VERSION ""

NS_ :

BS_:

BU_: EMS FR_CMR TCU vBDM AFS ILCU_LH ILCU_RH VCU BMS CLU EPB ESC H_U_MM IBU IBU_HS LDC MCU MDPS OBC RR_C_RDR SVM DATC ADAS_DRV ADAS_PRK AWD RWS AMP APSU DAU DVRS Dummy FCS HUD IAU ICSC ICU MLM PFSU PTGM SBW ACU ADM ECS TPMS HCU OPU PSB eCall AHLS ODS VESS AHV DHV DLBCU DPSS DPSU PSM RLHV RRHV SHVU_FR SHVU_RR DIBOX SAS FPCM SCM AFCU_DRV ESC_C CGW SCU WPC MFSW SWRC ESU AFCU_AST AFCU_RL AFCU_RR APSM ARS BCM BCW CCM DSS ECW FCU FICU GST HFKS HSWS LPI OPI PSD PSU RDC RLPSM RRPSM RWPC SLB SMK YRS SML CTM FR_C_RDR_LH FR_C_RDR_RH RR_C_RDR_LH CLU_MM HUD_MM LSD MKBD MM_CGW SBW_FF eCall_MM H_U_ETH FR_RDR

BO_ 388 L_FR_CMR_Obj_05_30ms: 32 FR_CMR
 SG_ FR_CMR_Obj_Crc05Val : 0|16@1+ (1,0) [0|65535] ""  ADAS_DRV
 SG_ FR_CMR_Obj_AlvCnt05Val : 16|8@1+ (1,0) [0|255] ""  ADAS_DRV
 SG_ FR_CMR_Obj_QualLvl09Sta : 24|7@1+ (1,0) [0|100] "%"  ADAS_DRV
 SG_ FR_CMR_Obj_AlvAge09Val : 32|8@1+ (1,0) [0|255] ""  ADAS_DRV
 SG_ FR_CMR_Obj_MvngFlag09Sta : 40|4@1+ (1,0) [0|9] ""  ADAS_DRV
 SG_ FR_CMR_Obj_Id09Val : 44|7@1+ (1,0) [0|127] ""  ADAS_DRV
 SG_ FR_CMR_Obj_Wth09Val : 52|7@1+ (0.05,0) [0|6.35] "m"  ADAS_DRV
 SG_ FR_CMR_Obj_Clfct09Sta : 60|3@1+ (1,0) [0|6] ""  ADAS_DRV
 SG_ FR_CMR_Obj_RelPosX09Val : 64|13@1+ (0.05,0) [0|350] "m"  ADAS_DRV
 SG_ FR_CMR_Obj_RelPosY09Val : 78|12@1+ (0.05,-102.4) [-102.4|102.35] "m"  ADAS_DRV
 SG_ FR_CMR_Obj_RelVelX09Val : 91|12@1+ (0.05,-100) [-100|100] "m/s"  ADAS_DRV
 SG_ FR_CMR_Obj_RelVelY09Val : 104|10@1+ (0.05,-25) [-25|25] "m/s"  ADAS_DRV
 SG_ FR_CMR_Obj_RelAccelX09Val : 115|9@1- (0.05,0) [-12.8|12.75] "m/s^2"  ADAS_DRV
 SG_ FR_CMR_Obj_QualLvl10Sta : 152|7@1+ (1,0) [0|100] "%"  ADAS_DRV
 SG_ FR_CMR_Obj_AlvAge10Val : 160|8@1+ (1,0) [0|255] ""  ADAS_DRV
 SG_ FR_CMR_Obj_MvngFlag10Sta : 168|4@1+ (1,0) [0|9] ""  ADAS_DRV
 SG_ FR_CMR_Obj_Id10Val : 172|7@1+ (1,0) [0|127] ""  ADAS_DRV
 SG_ FR_CMR_Obj_Wth10Val : 180|7@1+ (0.05,0) [0|6.35] "m"  ADAS_DRV
 SG_ FR_CMR_Obj_Clfct10Sta : 188|3@1+ (1,0) [0|6] ""  ADAS_DRV
 SG_ FR_CMR_Obj_RelPosX10Val : 192|13@1+ (0.05,0) [0|350] "m"  ADAS_DRV
 SG_ FR_CMR_Obj_RelPosY10Val : 206|12@1+ (0.05,-102.4) [-102.4|102.35] "m"  ADAS_DRV
 SG_ FR_CMR_Obj_RelVelX10Val : 219|12@1+ (0.05,-100) [-100|100] "m/s"  ADAS_DRV
 SG_ FR_CMR_Obj_RelVelY10Val : 232|10@1+ (0.05,-25) [-25|25] "m/s"  ADAS_DRV
 SG_ FR_CMR_Obj_RelAccelX10Val : 243|9@1- (0.05,0) [-12.8|12.75] "m/s^2"  ADAS_DRV

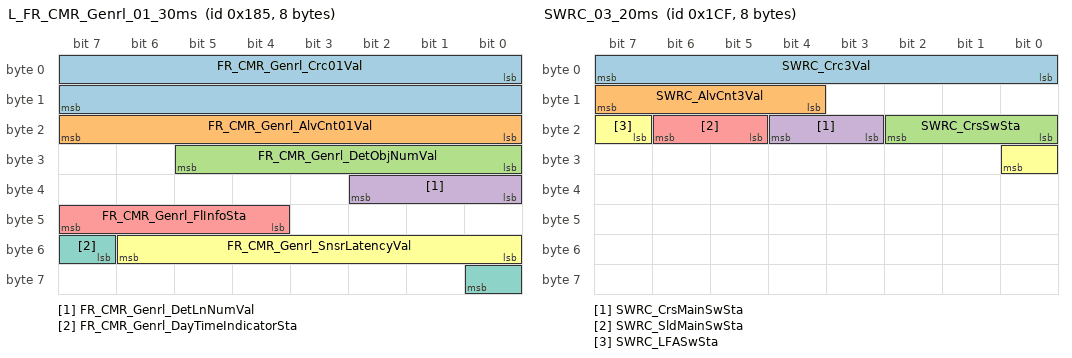
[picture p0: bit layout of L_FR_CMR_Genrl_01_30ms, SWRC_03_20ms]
BO_ 389 L_FR_CMR_Genrl_01_30ms: 8 FR_CMR
 SG_ FR_CMR_Genrl_Crc01Val : 0|16@1+ (1,0) [0|65535] ""  ADAS_DRV
 SG_ FR_CMR_Genrl_AlvCnt01Val : 16|8@1+ (1,0) [0|255] ""  ADAS_DRV
 SG_ FR_CMR_Genrl_DetObjNumVal : 24|6@1+ (1,0) [0|20] ""  ADAS_DRV
 SG_ FR_CMR_Genrl_DetLnNumVal : 32|3@1+ (1,0) [0|4] ""  ADAS_DRV
 SG_ FR_CMR_Genrl_FlInfoSta : 44|4@1+ (1,0) [0|2] ""  ADAS_DRV
 SG_ FR_CMR_Genrl_SnsrLatencyVal : 48|7@1+ (10,0) [0|1270] "ms"  ADAS_DRV
 SG_ FR_CMR_Genrl_DayTimeIndicatorSta : 55|2@1+ (1,0) [0|2] ""  ADAS_DRV

BO_ 416 ADAS_CMD_20_20ms: 32 FR_CMR
 SG_ ADAS_CMD_Crc20Val : 0|16@1+ (1,0) [0|65535] ""  ESC_C
 SG_ ADAS_CMD_AlvCnt20Val : 16|8@1+ (1,0) [0|255] ""  ESC_C,FR_CMR,CGW
 SG_ SCC_ObjDstVal : 24|11@1+ (0.1,0) [0|0] "m"  ESC_C,CGW
 SG_ SCC_ObjRelSpdVal : 35|12@1+ (0.1,-170) [0|0] "m/s"  CGW
 SG_ SCC_ObjLatPosVal : 47|9@1+ (0.1,-20) [0|0] "m"  CGW
 SG_ SCC_SysFlrSta : 64|2@1+ (1,0) [0|0] ""  ACU,ESC_C,CGW
 SG_ SCC_MainOnOffSta : 66|2@1+ (1,0) [0|0] ""  ACU,ESC_C,CGW
 SG_ SCC_OpSta : 68|3@1+ (1,0) [0|0] ""  ACU,ESC_C,CGW
 SG_ SCC_TakeoverReq : 72|2@1+ (1,0) [0|0] ""  ESC_C,CGW
 SG_ SCC_InfoDis : 74|3@1+ (1,0) [0|0] ""  ESC_C,CGW
 SG_ SCC_DrvAlrtDis : 77|2@1+ (1,0) [0|0] ""  ESC_C,CGW
 SG_ SCC_ObjDstLvlVal : 80|8@1+ (1,0) [0|0] ""  CGW
 SG_ SCC_HeadwayDstSetVal : 88|4@1+ (1,0) [0|0] ""  CGW
 SG_ SCC_EquipSta : 92|2@1+ (1,0) [0|0] ""  ESC_C,CGW
 SG_ SCC_TrgtSpdSetVal : 96|8@1+ (1,0) [0|0] "km/h or MPH"  ACU,ESC_C,CGW
 SG_ SCC_NSCCOpSta : 104|2@1+ (1,0) [0|0] ""  CGW
 SG_ SCC_NSCCOnOffSta : 106|2@1+ (1,0) [0|0] ""  FR_CMR,CGW
 SG_ SCC_ObjSta : 108|3@1+ (1,0) [0|0] ""  CGW
 SG_ SCC_SnstvtyModRetVal : 112|3@1+ (1,0) [0|0] ""  ESC_C,CGW
 SG_ SCC_AccelReqVal : 128|11@1+ (0.01,-10.23) [0|0] "m/s^2"  ESC_C,CGW
 SG_ SCC_AccelReqRawVal : 140|11@1+ (0.01,-10.23) [-10.23|10.24] "m/s^2"  ESC_C,CGW
 SG_ SCC_JrkUppLimVal : 152|7@1+ (0.1,0) [0|0] "m/s^3"  ESC_C,CGW
 SG_ SCC_JrkLwrLimVal : 160|7@1+ (0.1,0) [0|0] "m/s^3"  ESC_C,CGW
 SG_ SCC_AccelLimBandUppVal : 168|6@1+ (0.02,0) [0|1.26] "m/s^2"  ESC_C,CGW
 SG_ SCC_AccelLimBandLwrVal : 176|6@1+ (0.02,0) [0|1.26] "m/s^2"  ESC_C,CGW
 SG_ SCC_VehStpReq : 184|2@1+ (1,0) [0|0] ""  EPB,ESC_C,CGW
 SG_ SCC_TrgtDstVal : 192|11@1+ (0.1,0) [0|0] "m"  CGW

BO_ 426 CLU_01_20ms: 16 CLU
 SG_ CLU_Crc1Val : 0|16@1+ (1,0) [0|65535] ""  ADAS_PRK,DPSS,DPSU,Dummy,FR_CMR,ICU,MDPS,PSM,vBDM
 SG_ CLU_AlvCnt1Val : 16|8@1+ (1,0) [0|255] ""  ADAS_DRV,ADAS_PRK,AHLS,DPSS,DPSU,EMS,EPB,FR_CMR,ICU,MDPS,PSM,vBDM
 SG_ CLU_DtntOutSta : 28|2@1+ (1,0) [0|3] ""  ADAS_PRK,APSU,DATC,DAU,DVRS,FCS,FR_CMR,H_U_MM,IBU_HS,ICU,RR_C_RDR,SBW,SVM,WPC,vBDM
 SG_ CLU_SpdUnitTyp : 30|2@1+ (1,0) [0|3] ""  ACU,ADAS_DRV,ADAS_PRK,AMP,DPSU,EMS,FR_CMR,HCU,HUD,H_U_MM,IAU,ICU,MDPS,PSM,RR_C_RDR,SCM,VCU,WPC,eCall,vBDM
 SG_ CLU_SWRCLFASwSta : 39|2@1+ (1,0) [0|3] ""  ACU,ADAS_DRV,EMS,FR_CMR,TCU
 SG_ CLU_RhstaLvlSta : 43|5@1+ (1,0) [0|31] ""  ADAS_PRK,DATC,DAU,FCS,FR_CMR,HUD,H_U_MM,IBU_HS,ICU,MFSW,RR_C_RDR,SBW,SVM,SWRC,WPC,vBDM
 SG_ CLU_DisSpdVal : 48|10@1+ (0.5,0) [0|511.5] "km/h or MPH"  ADAS_DRV,ADAS_PRK,ADM,AMP,APSU,DPSU,EMS,FR_CMR,HCU,HUD,H_U_MM,IAU,IBU_HS,ICU,MDPS,PSM,RR_C_RDR,SCM,WPC,eCall,vBDM

BO_ 437 FR_CMR_03_50ms: 32 FR_CMR
 SG_ FR_CMR_Crc3Val : 0|16@1+ (1,0) [0|65535] ""  Dummy,ECS,vBDM
 SG_ FR_CMR_AlvCnt3Val : 16|8@1+ (1,0) [0|255] ""  Dummy,ECS,vBDM
 SG_ Info_LftLnQualSta : 24|3@1+ (1,0) [0|7] ""  Dummy,ECS,vBDM
 SG_ Info_LftLnDptSta : 27|2@1+ (1,0) [0|3] ""  Dummy,vBDM
 SG_ Info_LftLnPosVal : 29|14@1- (0.0039625,0) [-32.4608|32.4568375] "m"  Dummy,vBDM
 SG_ Info_LftLnHdingAnglVal : 43|10@1- (0.000976563,0) [-0.500000256|0.499023693] "rad"  Dummy,ECS,vBDM
 SG_ Info_LftLnCvtrVal : 64|16@1- (1E-006,0) [-0.032768|0.032767] "1/m"  Dummy,ECS,vBDM
 SG_ Info_LftLnCrvtrDrvtvVal : 80|16@1- (4E-009,0) [-0.000131072|0.000131068] "1/m2"  Dummy,ECS,vBDM
 SG_ Info_RtLnQualSta : 96|3@1+ (1,0) [0|7] ""  Dummy,ECS,vBDM
 SG_ Info_RtLnDptSta : 99|2@1+ (1,0) [0|3] ""  Dummy,vBDM
 SG_ Info_RtLnPosVal : 101|14@1- (0.0039625,0) [-32.4608|32.4568375] "m"  Dummy,vBDM
 SG_ Info_RtLnHdingAnglVal : 115|10@1- (0.000976563,0) [-0.500000256|0.499023693] "rad"  Dummy,ECS,vBDM
 SG_ Info_RtLnCvtrVal : 128|16@1- (1E-006,0) [-0.032768|0.032767] "1/m"  Dummy,ECS,vBDM
 SG_ Info_RtLnCrvtrDrvtvVal : 144|16@1- (4E-009,0) [-0.000131072|0.000131068] "1/m2"  Dummy,ECS,vBDM

BO_ 442 ADAS_CMD_40_50ms: 24 ADAS_DRV
 SG_ ADAS_CMD_AlvCnt40Val : 16|8@1+ (1,0) [0|0] ""  CLU,ESC,FR_CMR,H_U_MM,vBDM
 SG_ BCA_Sta : 64|4@1+ (1,0) [0|0] ""  CLU,ESC,FR_CMR,H_U_MM,vBDM
 SG_ BCA_LftWrngSta : 72|2@1+ (1,0) [0|0] ""  CLU,ESC,FR_CMR,H_U_MM,vBDM
 SG_ BCA_RtWrngSta : 74|2@1+ (1,0) [0|0] ""  CLU,ESC,FR_CMR,H_U_MM,vBDM

BO_ 463 SWRC_03_20ms: 8 SWRC
 SG_ SWRC_Crc3Val : 0|8@1+ (1,0) [0|0] ""  ACU,ADAS_DRV,Dummy,EMS,FR_CMR,TCU
 SG_ SWRC_AlvCnt3Val : 12|4@1+ (1,0) [0|0] ""  ACU,ADAS_DRV,Dummy,EMS,FR_CMR,TCU
 SG_ SWRC_CrsSwSta : 16|3@1+ (1,0) [0|0] ""  ACU,ADAS_DRV,EMS,FR_CMR,TCU
 SG_ SWRC_CrsMainSwSta : 19|2@1+ (1,0) [0|0] ""  FR_CMR
 SG_ SWRC_SldMainSwSta : 21|2@1+ (1,0) [0|0] ""  FR_CMR
 SG_ SWRC_LFASwSta : 23|2@1+ (1,0) [0|0] ""  ACU,ADAS_DRV,EMS,FR_CMR,TCU

BO_ 480 ADAS_CMD_31_50ms: 16 FR_CMR
 SG_ ADAS_CMD_Crc31Val : 0|16@1+ (1,0) [0|0] ""  CGW
 SG_ ADAS_CMD_AlvCnt31Val : 16|8@1+ (1,0) [0|0] ""  CGW
 SG_ HDA_OptUsmSta : 24|3@1+ (1,0) [0|0] ""  CGW
 SG_ LFA_OptUsmSta : 27|3@1+ (1,0) [0|0] ""  CGW
 SG_ HDA_CntrlModSta : 30|2@1+ (1,0) [0|0] ""  CGW
 SG_ HDA_InfoPUDis : 32|3@1+ (1,0) [0|0] ""  CGW
 SG_ HDA_AutoSetSpdSta : 35|2@1+ (1,0) [0|0] ""  CGW
 SG_ HDA_AutoSetSpdUpdtSta : 37|2@1+ (1,0) [0|0] ""  CGW
 SG_ HDA_AutoSetSpdVal : 39|8@1+ (1,0) [0|0] "km/h"  CGW
 SG_ HDA_LFA_SymSta : 47|2@1+ (1,0) [0|0] ""  CGW
 SG_ HDA_LFA_WrnSnd : 49|2@1+ (1,0) [0|0] ""  Dummy

BO_ 506 FR_CMR_02_100ms: 32 FR_CMR
 SG_ ISLA_SpdwOffst : 112|8@1+ (1,0) [0|255] ""  CLU,CGW
 SG_ ISLA_SwIgnoreReq : 120|2@1+ (1,0) [0|3] ""  CGW
 SG_ ISLA_SpdChgReq : 122|2@1+ (1,0) [0|3] ""  CGW
 SG_ ISLA_SpdWrn : 124|2@1+ (1,0) [0|3] ""  CLU,CGW
 SG_ ISLA_IcyWrn : 126|2@1+ (1,0) [0|3] ""  CLU,CGW
 SG_ ISLA_SymFlashMod : 128|3@1+ (1,0) [0|7] ""  CLU,CGW
 SG_ ISLA_Popup : 131|3@1+ (1,0) [0|7] ""  CLU
 SG_ ISLA_OptUsmSta : 136|3@1+ (1,0) [0|7] ""  CLU,CGW
 SG_ ISLA_OffstUsmSta : 139|3@1+ (1,0) [0|7] ""  CLU,CGW
 SG_ ISLA_AutoUsmSta : 142|2@1+ (1,0) [0|3] ""  CLU,CGW
 SG_ ISLA_Cntry : 144|4@1+ (1,0) [0|15] ""  CLU,CGW
 SG_ ISLA_AddtnlSign : 149|5@1+ (1,0) [0|31] ""  CLU,CGW
 SG_ ISLA_SchoolZone : 154|2@1+ (1,0) [0|3] ""  CLU,CGW
 SG_ FR_CMR_Crc2Val : 0|16@1+ (1,0) [0|65535] ""  CLU,IBU_HS
 SG_ FR_CMR_AlvCnt2Val : 16|8@1+ (1,0) [0|255] ""  CLU,H_U_MM,IBU_HS
 SG_ ISLW_OptUsmSta : 24|2@1+ (1,0) [0|3] ""  CLU,HUD,H_U_MM
 SG_ ISLW_SysSta : 26|2@1+ (1,0) [0|3] ""  CGW,CLU,EMS,HUD,H_U_MM
 SG_ ISLW_NoPassingInfoDis : 28|3@1+ (1,0) [0|7] ""  CGW,CLU,HUD,H_U_MM
 SG_ ISLW_OvrlpSignDis : 31|2@1+ (1,0) [0|3] ""  CGW,CLU,HUD,H_U_MM
 SG_ ISLW_SpdCluMainDis : 33|8@1+ (1,0) [0|255] ""  CLU,HUD,H_U_MM
 SG_ ISLW_SpdNaviMainDis : 41|8@1+ (1,0) [0|255] ""  CGW,H_U_MM
 SG_ ISLW_SubCondinfoSta1 : 49|4@1+ (1,0) [0|15] ""  CGW,CLU,H_U_MM
 SG_ ISLW_SubCondinfoSta2 : 53|4@1+ (1,0) [0|15] ""  CGW,CLU,H_U_MM
 SG_ ISLW_SpdCluSubMainDis : 64|8@1+ (1,0) [0|255] ""  CLU,H_U_MM
 SG_ ISLW_SpdCluDisSubCond1 : 72|8@1+ (1,0) [0|255] ""  CLU,H_U_MM
 SG_ ISLW_SpdCluDisSubCond2 : 80|8@1+ (1,0) [0|255] ""  CLU,H_U_MM
 SG_ ISLW_SpdNaviSubMainDis : 88|8@1+ (1,0) [0|255] ""  CLU,H_U_MM
 SG_ ISLW_SpdNaviDisSubCond1 : 96|8@1+ (1,0) [0|255] ""  CGW,CLU,H_U_MM
 SG_ ISLW_SpdNaviDisSubCond2 : 104|8@1+ (1,0) [0|255] ""  CGW,CLU,H_U_MM

BO_ 549 CLU_02_100ms: 16 CLU
 SG_ CLU_AlvCnt2Val : 16|8@1+ (1,0) [0|255] ""  AWD,EMS,ESC,FR_CMR,H_U_MM,IBU,RWS,vBDM
 SG_ CLU_TerrainMainSwSta : 62|2@1+ (1,0) [0|3] ""  AWD,ESC,FR_CMR,HCU,H_U_MM,ICSC,MDPS,VCU,vBDM
 SG_ CLU_OdoVal : 72|24@1+ (0.1,0) [0|1677721.5] "km"  ADAS_DRV,AMP,AWD,BMS,EMS,EPB,ESC,ESU,FR_CMR,HCU,H_U_MM,IAU,IBU,ICU,LDC,MCU,OBC,OPU,RR_C_RDR,TCU,TPMS,VCU,eCall,vBDM
 SG_ CLU_DawLastBrkTimeVal : 96|4@1+ (1,0) [0|15] ""  Dummy,FR_CMR,H_U_MM,vBDM
 SG_ CLU_IceWrnIndSta : 102|2@1+ (1,0) [0|3] ""  Dummy,FR_CMR,vBDM
 SG_ CLU_DrvngModSwSta : 104|4@1+ (1,0) [0|15] ""  ADAS_DRV,AMP,AWD,DATC,ECS,EMS,ESC,FR_CMR,HCU,HUD,H_U_MM,ICSC,MDPS,TCU,vBDM
 SG_ CLU_TerrainModSwSta : 123|3@1+ (1,0) [0|7] ""  ADAS_DRV,AWD,DATC,ECS,EMS,ESC,FR_CMR,HCU,HUD,H_U_MM,ICSC,MDPS,TCU,vBDM

BO_ 560 HCU_05_100ms: 32 HCU
 SG_ HCU_BrkLmpOnReq : 80|2@1+ (1,0) [0|0] ""  CLU,ESC,FR_CMR,H_U_MM,ICU

BO_ 608 EMS_05_100ms: 32 EMS
 SG_ ENG_TransmsnTyp : 176|6@1+ (1,0) [0|63] ""  ACU,AWD,DATC,EPB,ESC,FR_CMR,HUD,H_U_MM,IBU,IBU_HS,ICSC,ICU,RR_C_RDR,TCU,vBDM
 SG_ ENG_EngDsplceTyp : 184|8@1+ (0.1,0) [0|25.5] "liter"  ACU,ADAS_PRK,AMP,AWD,CLU,DATC,EPB,ESC,FR_CMR,H_U_MM,IBU,ICSC,ICU,vBDM

BO_ 613 EMS_08_100ms: 32 EMS
 SG_ HEV_BrkLtSwSta : 62|2@1+ (1,0) [0|0] ""  ACU,EPB,FR_CMR,H_U_MM,OPU,RR_C_RDR,TCU

BO_ 661 EMS_06_100ms: 24 EMS
 SG_ OBD_EngRpmVal : 40|16@1+ (0.25,0) [0|0] "rpm"  BMS,FR_CMR,MCU,TCU,vBDM

BO_ 674 L_FR_CMR_Ln_01_50ms: 32 FR_CMR
 SG_ FR_CMR_Ln_Crc01Val : 0|16@1+ (1,0) [0|65535] ""  ADAS_DRV
 SG_ FR_CMR_Ln_AlvCnt01Val : 16|8@1+ (1,0) [0|255] ""  ADAS_DRV
 SG_ FR_CMR_Ln_LftDptDstVal : 24|16@1+ (0.01,-10) [-10|10] "m"  ADAS_DRV
 SG_ FR_CMR_Ln_RtDptDstVal : 40|16@1+ (0.01,-10) [-10|10] "m"  ADAS_DRV
 SG_ FR_CMR_Ln_LftDptAnglVal : 64|16@1+ (0.000977,-0.357) [-0.357|0.357] "rad"  ADAS_DRV
 SG_ FR_CMR_Ln_RtDptAnglVal : 96|16@1+ (0.000977,-0.357) [-0.357|0.357] "rad"  ADAS_DRV
 SG_ FR_CMR_Ln_LftCurveVal : 128|32@1+ (9.77E-007,-0.032) [-0.032|0.032] "1/m"  ADAS_DRV
 SG_ FR_CMR_Ln_RtCurveVal : 160|32@1+ (9.77E-007,-0.032) [-0.032|0.032] "1/m"  ADAS_DRV
 SG_ FR_CMR_Ln_LftCurveRatVal : 192|32@1+ (3.73E-009,-0.00012) [-0.00012|0.000122] "1/m^2"  ADAS_DRV
 SG_ FR_CMR_Ln_RtCurveRatVal : 224|32@1+ (3.73E-009,-0.00012) [-0.00012|0.000122] "1/m^2"  ADAS_DRV

BO_ 675 L_FR_CMR_Ln_02_50ms: 32 FR_CMR
 SG_ FR_CMR_Ln_Crc02Val : 0|16@1+ (1,0) [0|65535] ""  ADAS_DRV
 SG_ FR_CMR_Ln_AlvCnt02Val : 16|8@1+ (1,0) [0|255] ""  ADAS_DRV
 SG_ FR_CMR_Ln_LftNextLnDptDstVal : 24|16@1+ (0.01,-10) [-10|10] "m"  ADAS_DRV
 SG_ FR_CMR_Ln_RtNextDptDstVal : 40|16@1+ (0.01,-10) [-10|10] "m"  ADAS_DRV
 SG_ FR_CMR_Ln_LftNextDptAnglVal : 64|16@1+ (0.000977,-0.357) [-0.357|0.357] "rad"  ADAS_DRV
 SG_ FR_CMR_Ln_RtNextDptAnglVal : 96|16@1+ (0.000977,-0.357) [-0.357|0.357] "rad"  ADAS_DRV
 SG_ FR_CMR_Ln_LftNextCurveVal : 128|32@1+ (9.77E-007,-0.032) [-0.032|0.032] "1/m"  ADAS_DRV
 SG_ FR_CMR_Ln_RtNextCurveVal : 160|32@1+ (9.77E-007,-0.032) [-0.032|0.032] "1/m"  ADAS_DRV
 SG_ FR_CMR_Ln_LftNextCurveRatVal : 192|32@1+ (3.73E-009,-0.00012) [-0.00012|0.000122] "1/m^2"  ADAS_DRV
 SG_ FR_CMR_Ln_RtNextCurveRatVal : 224|32@1+ (3.73E-009,-0.00012) [-0.00012|0.000122] "1/m^2"  ADAS_DRV

BO_ 676 L_FR_CMR_Ln_03_50ms: 24 FR_CMR
 SG_ FR_CMR_Ln_Crc03Val : 0|16@1+ (1,0) [0|65535] ""  ADAS_DRV
 SG_ FR_CMR_Ln_AlvCnt03Val : 16|8@1+ (1,0) [0|255] ""  ADAS_DRV
 SG_ FR_CMR_Ln_WthLnLft01Val : 24|8@1+ (0.01,0) [0|0.5] "m"  ADAS_DRV
 SG_ FR_CMR_Ln_WthLnRt01Val : 32|8@1+ (0.01,0) [0|0.5] "m"  ADAS_DRV
 SG_ FR_CMR_Ln_ClfctLft01Sta : 40|4@1+ (1,0) [0|8] ""  ADAS_DRV
 SG_ FR_CMR_Ln_ClfctRt01Sta : 44|4@1+ (1,0) [0|8] ""  ADAS_DRV
 SG_ FR_CMR_Ln_LftClr01Sta : 48|3@1+ (1,0) [0|3] ""  ADAS_DRV
 SG_ FR_CMR_Ln_RtClr01Sta : 52|3@1+ (1,0) [0|3] ""  ADAS_DRV
 SG_ FR_CMR_Ln_QualLvlLft01Sta : 56|3@1+ (1,0) [0|7] ""  ADAS_DRV
 SG_ FR_CMR_Ln_QualLvlRt01Sta : 60|3@1+ (1,0) [0|7] ""  ADAS_DRV
 SG_ FR_CMR_Ln_ClfctLft02Sta : 64|4@1+ (1,0) [0|8] ""  ADAS_DRV
 SG_ FR_CMR_Ln_ClfctRt02Sta : 68|4@1+ (1,0) [0|8] ""  ADAS_DRV
 SG_ FR_CMR_Ln_QualLvlLft02Sta : 72|3@1+ (1,0) [0|7] ""  ADAS_DRV
 SG_ FR_CMR_Ln_QualLvlRt02Sta : 76|3@1+ (1,0) [0|7] ""  ADAS_DRV
 SG_ FR_CMR_Ln_LftViewRngVal : 80|16@1+ (0.1,0) [0|200] "m"  ADAS_DRV
 SG_ FR_CMR_Ln_RtViewRngVal : 96|16@1+ (0.1,0) [0|200] "m"  ADAS_DRV

BO_ 698 FR_CMR_04_00ms: 32 FR_CMR
 SG_ FR_CMR_Crc4Val : 0|16@1+ (1,0) [0|0] ""  Dummy
 SG_ FR_CMR_AlvCnt4Val : 16|8@1+ (1,0) [0|0] ""  Dummy
 SG_ IFSref_FR_CMR_Sta : 24|2@1+ (1,0) [0|0] ""  ILCU_LH,ILCU_RH
 SG_ IFSref_VehNumVal : 26|4@1+ (1,0) [0|0] ""  ILCU_LH,ILCU_RH
 SG_ IFSref_ILLAmbtSta : 30|2@1+ (0.1,0) [0|0] ""  ILCU_LH,ILCU_RH
 SG_ IFSref_VehLftAngl1Val : 32|9@1+ (0.1,-25) [0|0] "Deg"  ILCU_LH,ILCU_RH
 SG_ IFSref_VehRtAngl1Val : 41|9@1+ (0.1,-25) [0|0] "Deg"  ILCU_LH,ILCU_RH
 SG_ IFSref_VehLftAngl2Val : 50|9@1+ (0.1,-25) [0|0] "Deg"  ILCU_LH,ILCU_RH
 SG_ IFSref_VehDst1Val : 59|4@1+ (1,0) [0|0] ""  ILCU_LH,ILCU_RH
 SG_ IFSref_VehRtAngl2Val : 64|9@1+ (0.1,-25) [0|0] "Deg"  ILCU_LH,ILCU_RH
 SG_ IFSref_VehLftAngl3Val : 73|9@1+ (0.1,-25) [0|0] "Deg"  ILCU_LH,ILCU_RH
 SG_ IFSref_VehRtAngl3Val : 82|9@1+ (0.1,-25) [0|0] "Deg"  ILCU_LH,ILCU_RH
 SG_ IFSref_VehLftAngl4Val : 91|9@1+ (0.1,-25) [0|0] "Deg"  ILCU_LH,ILCU_RH
 SG_ IFSref_VehRtAngl4Val : 100|9@1+ (0.1,-25) [0|0] "Deg"  ILCU_LH,ILCU_RH
 SG_ IFSref_VehLftAngl5Val : 109|9@1+ (0.1,-25) [0|0] "Deg"  ILCU_LH,ILCU_RH
 SG_ IFSref_VehRtAngl5Val : 118|9@1+ (0.1,-25) [0|0] "Deg"  ILCU_LH,ILCU_RH
 SG_ IFSref_VehLftAngl6Val : 128|9@1+ (0.1,-25) [0|0] "Deg"  ILCU_LH,ILCU_RH
 SG_ IFSref_VehRtAngl6Val : 137|9@1+ (0.1,-25) [0|0] "Deg"  ILCU_LH,ILCU_RH
 SG_ IFSref_VehLftAngl7Val : 146|9@1+ (0.1,-25) [0|0] "Deg"  ILCU_LH,ILCU_RH
 SG_ IFSref_VehRtAngl7Val : 155|9@1+ (0.1,-25) [0|0] "Deg"  ILCU_LH,ILCU_RH
 SG_ IFSref_VehLftAngl8Val : 164|9@1+ (0.1,-25) [0|0] "Deg"  ILCU_LH,ILCU_RH
 SG_ IFSref_VehRtAngl8Val : 173|9@1+ (0.1,-25) [0|0] "Deg"  ILCU_LH,ILCU_RH
 SG_ IFSref_VehLftAngl9Val : 182|9@1+ (0.1,-25) [0|0] "Deg"  ILCU_LH,ILCU_RH
 SG_ IFSref_VehRtAngl9Val : 192|9@1+ (0.1,-25) [0|0] "Deg"  ILCU_LH,ILCU_RH
 SG_ IFSref_VehLftAngl10Val : 201|9@1+ (0.1,-25) [0|0] "Deg"  ILCU_LH,ILCU_RH
 SG_ IFSref_VehRtAngl10Val : 210|9@1+ (0.1,-25) [0|0] "Deg"  ILCU_LH,ILCU_RH
 SG_ IFSref_VehDst2Val : 219|4@1+ (1,0) [0|0] ""  ILCU_LH,ILCU_RH
 SG_ IFSref_VehDst3Val : 223|4@1+ (1,0) [0|0] ""  ILCU_LH,ILCU_RH
 SG_ IFSref_VehDst4Val : 227|4@1+ (1,0) [0|0] ""  ILCU_LH,ILCU_RH
 SG_ IFSref_VehDst5Val : 231|4@1+ (1,0) [0|0] ""  ILCU_LH,ILCU_RH
 SG_ IFSref_VehDst6Val : 235|4@1+ (1,0) [0|0] ""  ILCU_LH,ILCU_RH
 SG_ IFSref_VehDst7Val : 239|4@1+ (1,0) [0|0] ""  ILCU_LH,ILCU_RH
 SG_ IFSref_VehDst8Val : 243|4@1+ (1,0) [0|0] ""  ILCU_LH,ILCU_RH
 SG_ IFSref_VehDst9Val : 247|4@1+ (1,0) [0|0] ""  ILCU_LH,ILCU_RH
 SG_ IFSref_VehDst10Val : 251|4@1+ (1,0) [0|0] ""  ILCU_LH,ILCU_RH

BO_ 720 TCU_03_100ms: 32 TCU
 SG_ TCU_Crc3Val : 0|16@1+ (1,0) [0|0] ""  CLU,EMS,ESC,FR_CMR,H_U_MM,vBDM
 SG_ TCU_AlvCnt3Val : 16|8@1+ (1,0) [0|0] ""  CLU,EMS,ESC,FR_CMR,H_U_MM,vBDM
 SG_ TCU_WrngMsgSta : 24|8@1+ (1,0) [0|0] ""  CLU,EMS,ESC,FR_CMR,H_U_MM,ICSC,vBDM

BO_ 832 EMS_13_100ms: 32 EMS
 SG_ HEV_OBD_EngRpmVal : 40|16@1+ (0.25,0) [0|0] "rpm"  BMS,FR_CMR,MCU,TCU,vBDM

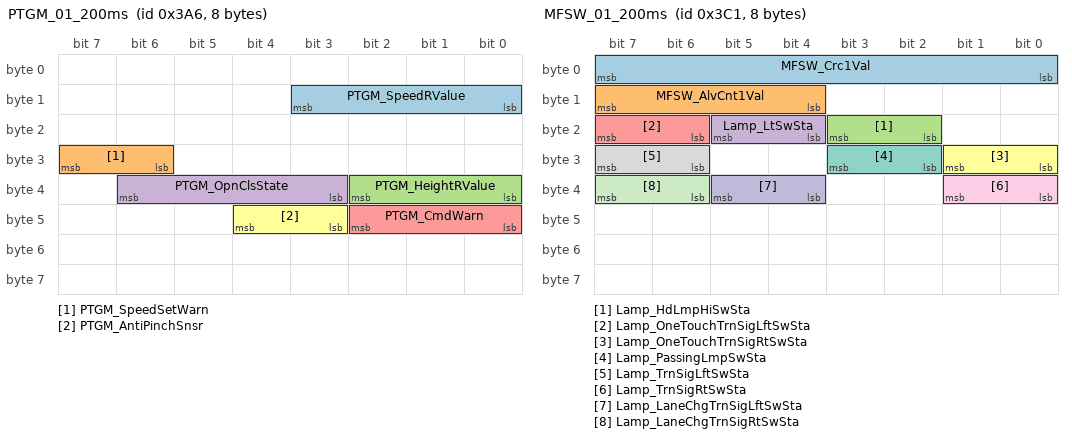
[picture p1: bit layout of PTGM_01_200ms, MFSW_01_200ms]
BO_ 934 PTGM_01_200ms: 8 PTGM
 SG_ PTGM_SpeedRValue : 8|4@1+ (1,0) [0|0] ""  ACU,ADAS_DRV,ADAS_PRK,ADM,AFCU_AST,AFCU_DRV,AFCU_RL,AFCU_RR,AFS,AHLS,AHV,APSM,APSU,ARS,AWD,BCM,BCW,BMS,CCM,CLU,DATC,DAU,DHV,DIBOX,DLBCU,DPSS,DPSU,DSS,DVRS,Dummy,ECS,ECW,EMS,EPB,ESC,ESU,FCS,FCU,FICU,FPCM,FR_CMR,GST,HCU,HFKS,HSWS,HUD,H_U_MM,IAU,IBU,IBU_HS,ICSC,ICU,ILCU_LH,ILCU_RH,LDC,LPI,MCU,MDPS,MFSW,MLM,OBC,ODS,OPI,OPU,PSB,PSD,PSM,PSU,RDC,RLHV,RLPSM,RRHV,RRPSM,RR_C_RDR,RWPC,RWS,SAS,SBW,SCM,SCU,SHVU_FR,SHVU_RR,SLB,SMK,SVM,SWRC,TCU,TPMS,VCU,VESS,WPC,YRS,eCall,vBDM
 SG_ PTGM_SpeedSetWarn : 30|2@1+ (1,0) [0|0] ""  ACU,ADAS_DRV,ADAS_PRK,ADM,AFCU_AST,AFCU_DRV,AFCU_RL,AFCU_RR,AFS,AHLS,AHV,APSM,APSU,ARS,AWD,BCM,BCW,BMS,CCM,CLU,DATC,DAU,DHV,DIBOX,DLBCU,DPSS,DPSU,DSS,DVRS,Dummy,ECS,ECW,EMS,EPB,ESC,ESU,FCS,FCU,FICU,FPCM,FR_CMR,GST,HCU,HFKS,HSWS,HUD,H_U_MM,IAU,IBU,IBU_HS,ICSC,ICU,ILCU_LH,ILCU_RH,LDC,LPI,MCU,MDPS,MFSW,MLM,OBC,ODS,OPI,OPU,PSB,PSD,PSM,PSU,RDC,RLHV,RLPSM,RRHV,RRPSM,RR_C_RDR,RWPC,RWS,SAS,SBW,SCM,SCU,SHVU_FR,SHVU_RR,SLB,SMK,SVM,SWRC,TCU,TPMS,VCU,VESS,WPC,YRS,eCall,vBDM
 SG_ PTGM_HeightRValue : 32|3@1+ (1,0) [0|0] ""  ACU,ADAS_DRV,ADAS_PRK,ADM,AFCU_AST,AFCU_DRV,AFCU_RL,AFCU_RR,AFS,AHLS,AHV,APSM,APSU,ARS,AWD,BCM,BCW,BMS,CCM,CLU,DATC,DAU,DHV,DIBOX,DLBCU,DPSS,DPSU,DSS,DVRS,Dummy,ECS,ECW,EMS,EPB,ESC,ESU,FCS,FCU,FICU,FPCM,FR_CMR,GST,HCU,HFKS,HSWS,HUD,H_U_MM,IAU,IBU,IBU_HS,ICSC,ICU,ILCU_LH,ILCU_RH,LDC,LPI,MCU,MDPS,MFSW,MLM,OBC,ODS,OPI,OPU,PSB,PSD,PSM,PSU,RDC,RLHV,RLPSM,RRHV,RRPSM,RR_C_RDR,RWPC,RWS,SAS,SBW,SCM,SCU,SHVU_FR,SHVU_RR,SLB,SMK,SVM,SWRC,TCU,TPMS,VCU,VESS,WPC,YRS,eCall,vBDM
 SG_ PTGM_OpnClsState : 35|4@1+ (1,0) [0|0] ""  ACU,ADAS_DRV,ADAS_PRK,ADM,AFCU_AST,AFCU_DRV,AFCU_RL,AFCU_RR,AFS,AHLS,AHV,APSM,APSU,ARS,AWD,BCM,BCW,BMS,CCM,CLU,DATC,DAU,DHV,DIBOX,DLBCU,DPSS,DPSU,DSS,DVRS,Dummy,ECS,ECW,EMS,EPB,ESC,ESU,FCS,FCU,FICU,FPCM,FR_CMR,GST,HCU,HFKS,HSWS,HUD,H_U_MM,IAU,IBU,IBU_HS,ICSC,ICU,ILCU_LH,ILCU_RH,LDC,LPI,MCU,MDPS,MFSW,MLM,OBC,ODS,OPI,OPU,PSB,PSD,PSM,PSU,RDC,RLHV,RLPSM,RRHV,RRPSM,RR_C_RDR,RWPC,RWS,SAS,SBW,SCM,SCU,SHVU_FR,SHVU_RR,SLB,SMK,SVM,SWRC,TCU,TPMS,VCU,VESS,WPC,YRS,eCall,vBDM
 SG_ PTGM_CmdWarn : 40|3@1+ (1,0) [0|0] ""  ACU,ADAS_DRV,ADAS_PRK,ADM,AFCU_AST,AFCU_DRV,AFCU_RL,AFCU_RR,AFS,AHLS,AHV,APSM,APSU,ARS,AWD,BCM,BCW,BMS,CCM,CLU,DATC,DAU,DHV,DIBOX,DLBCU,DPSS,DPSU,DSS,DVRS,Dummy,ECS,ECW,EMS,EPB,ESC,ESU,FCS,FCU,FICU,FPCM,FR_CMR,GST,HCU,HFKS,HSWS,HUD,H_U_MM,IAU,IBU,IBU_HS,ICSC,ICU,ILCU_LH,ILCU_RH,LDC,LPI,MCU,MDPS,MFSW,MLM,OBC,ODS,OPI,OPU,PSB,PSD,PSM,PSU,RDC,RLHV,RLPSM,RRHV,RRPSM,RR_C_RDR,RWPC,RWS,SAS,SBW,SCM,SCU,SHVU_FR,SHVU_RR,SLB,SMK,SVM,SWRC,TCU,TPMS,VCU,VESS,WPC,YRS,eCall,vBDM
 SG_ PTGM_AntiPinchSnsr : 43|2@1+ (1,0) [0|0] ""  ACU,ADAS_DRV,ADAS_PRK,ADM,AFCU_AST,AFCU_DRV,AFCU_RL,AFCU_RR,AFS,AHLS,AHV,APSM,APSU,ARS,AWD,BCM,BCW,BMS,CCM,CLU,DATC,DAU,DHV,DIBOX,DLBCU,DPSS,DPSU,DSS,DVRS,Dummy,ECS,ECW,EMS,EPB,ESC,ESU,FCS,FCU,FICU,FPCM,FR_CMR,GST,HCU,HFKS,HSWS,HUD,H_U_MM,IAU,IBU,IBU_HS,ICSC,ICU,ILCU_LH,ILCU_RH,LDC,LPI,MCU,MDPS,MFSW,MLM,OBC,ODS,OPI,OPU,PSB,PSD,PSM,PSU,RDC,RLHV,RLPSM,RRHV,RRPSM,RR_C_RDR,RWPC,RWS,SAS,SBW,SCM,SCU,SHVU_FR,SHVU_RR,SLB,SMK,SVM,SWRC,TCU,TPMS,VCU,VESS,WPC,YRS,eCall,vBDM

BO_ 961 MFSW_01_200ms: 8 IBU_HS
 SG_ MFSW_Crc1Val : 0|8@1+ (1,0) [0|0] ""  Dummy,FR_CMR,IBU_HS,ICU
 SG_ MFSW_AlvCnt1Val : 12|4@1+ (1,0) [0|0] ""  Dummy,FR_CMR,IBU_HS,ICU
 SG_ Lamp_HdLmpHiSwSta : 18|2@1+ (1,0) [0|0] ""  ADAS_DRV,Dummy,FR_CMR,IBU_HS
 SG_ Lamp_LtSwSta : 20|2@1+ (1,0) [0|0] ""  AFS,CLU,Dummy,FR_CMR,IBU_HS,ILCU_LH,ILCU_RH,SBW
 SG_ Lamp_OneTouchTrnSigLftSwSta : 22|2@1+ (1,0) [0|0] ""  Dummy,FR_CMR,IBU_HS,RR_C_RDR
 SG_ Lamp_OneTouchTrnSigRtSwSta : 24|2@1+ (1,0) [0|0] ""  Dummy,FR_CMR,IBU_HS,RR_C_RDR
 SG_ Lamp_PassingLmpSwSta : 26|2@1+ (1,0) [0|0] ""  AFS,FR_CMR,IBU_HS,ILCU_LH,ILCU_RH
 SG_ Lamp_TrnSigLftSwSta : 30|2@1+ (1,0) [0|0] ""  ADAS_DRV,CLU,Dummy,FR_CMR,HCU,H_U_MM,IBU_HS,ICU,RR_C_RDR,TCU
 SG_ Lamp_TrnSigRtSwSta : 32|2@1+ (1,0) [0|0] ""  ADAS_DRV,CLU,Dummy,FR_CMR,HCU,H_U_MM,IBU_HS,ICU,RR_C_RDR,TCU
 SG_ Lamp_LaneChgTrnSigLftSwSta : 36|2@1+ (1,0) [0|0] ""  ADAS_DRV,CLU,Dummy,FR_CMR,HCU,IBU_HS,ICU,TCU
 SG_ Lamp_LaneChgTrnSigRtSwSta : 38|2@1+ (1,0) [0|0] ""  ADAS_DRV,CLU,Dummy,FR_CMR,HCU,IBU_HS,ICU,TCU

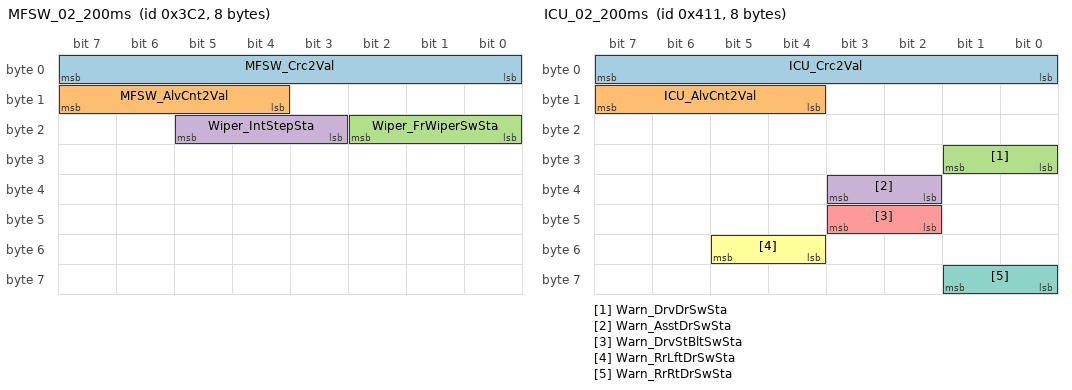
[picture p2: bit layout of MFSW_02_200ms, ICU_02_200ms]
BO_ 962 MFSW_02_200ms: 8 IBU_HS
 SG_ MFSW_Crc2Val : 0|8@1+ (1,0) [0|0] ""  Dummy,FR_CMR,IBU_HS
 SG_ MFSW_AlvCnt2Val : 12|4@1+ (1,0) [0|0] ""  Dummy,FR_CMR,IBU_HS
 SG_ Wiper_FrWiperSwSta : 16|3@1+ (1,0) [0|0] ""  CLU,Dummy,EMS,ESC,FICU,FR_CMR,H_U_MM,IBU_HS,LDC
 SG_ Wiper_IntStepSta : 19|3@1+ (1,0) [0|0] ""  ADAS_DRV,CLU,Dummy,EMS,ESC,FR_CMR,H_U_MM,IBU_HS,LDC

BO_ 1035 FICU_01_200ms: 8 FICU
 SG_ ExtLamp_IRLmpLftFlSta : 0|2@1+ (1,0) [0|0] ""  Dummy,FR_CMR
 SG_ ExtLamp_IRLmpRtFlSta : 2|2@1+ (1,0) [0|0] ""  Dummy,FR_CMR

BO_ 1041 ICU_02_200ms: 8 ICU
 SG_ ICU_Crc2Val : 0|8@1+ (1,0) [0|0] ""  ADAS_PRK,Dummy,FR_CMR,IBU_HS,vBDM
 SG_ ICU_AlvCnt2Val : 12|4@1+ (1,0) [0|0] ""  ADAS_PRK,Dummy,FR_CMR,IBU_HS,vBDM
 SG_ Warn_DrvDrSwSta : 24|2@1+ (1,0) [0|0] ""  ADAS_DRV,ADAS_PRK,AMP,CLU,DATC,DAU,DPSU,EPB,ESC,FR_CMR,HCU,HUD,H_U_MM,IAU,IBU_HS,LPI,MLM,PSM,PTGM,RWPC,SBW,SCM,SML,SVM,TCU,WPC,vBDM
 SG_ Warn_AsstDrSwSta : 34|2@1+ (1,0) [0|0] ""  ADAS_DRV,ADAS_PRK,AMP,APSM,APSU,BMS,CLU,DATC,DAU,FR_CMR,HCU,HUD,H_U_MM,IAU,IBU_HS,MLM,PTGM,RWPC,SBW,SCM,SML,SVM,TCU,WPC,vBDM
 SG_ Warn_DrvStBltSwSta : 42|2@1+ (1,0) [0|0] ""  ADAS_DRV,ADAS_PRK,DPSU,Dummy,EPB,ESC,FR_CMR,H_U_MM,IBU_HS,PSB,PSM,TCU,vBDM
 SG_ Warn_RrLftDrSwSta : 52|2@1+ (1,0) [0|0] ""  ADAS_DRV,ADAS_PRK,AMP,APSU,BMS,CLU,DATC,DAU,FR_CMR,HCU,HUD,H_U_MM,IAU,IBU_HS,MLM,PSM,PTGM,RLPSM,RWPC,SCM,SML,SVM,TCU,WPC,vBDM
 SG_ Warn_RrRtDrSwSta : 56|2@1+ (1,0) [0|0] ""  ADAS_DRV,ADAS_PRK,AMP,APSU,BMS,CLU,DATC,DAU,FR_CMR,HCU,HUD,H_U_MM,IAU,IBU_HS,MLM,PSM,PTGM,RLPSM,RWPC,SCM,SML,SVM,TCU,WPC,vBDM

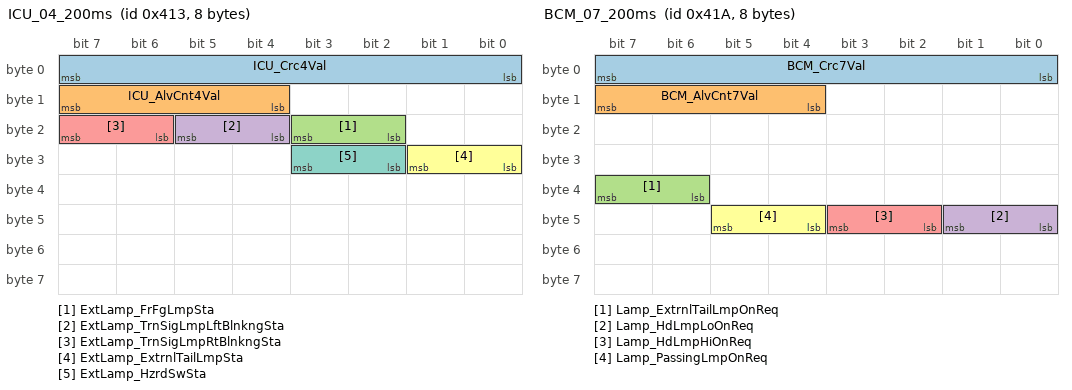
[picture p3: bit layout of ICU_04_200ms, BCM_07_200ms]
BO_ 1043 ICU_04_200ms: 8 ICU
 SG_ ICU_Crc4Val : 0|8@1+ (1,0) [0|0] ""  Dummy,FR_CMR
 SG_ ICU_AlvCnt4Val : 12|4@1+ (1,0) [0|0] ""  Dummy,FR_CMR
 SG_ ExtLamp_FrFgLmpSta : 18|2@1+ (1,0) [0|0] ""  AFS,CLU,Dummy,FR_CMR
 SG_ ExtLamp_TrnSigLmpLftBlnkngSta : 20|2@1+ (1,0) [0|3] ""  ADAS_DRV,CLU,DATC,Dummy,FR_CMR,IBU_HS
 SG_ ExtLamp_TrnSigLmpRtBlnkngSta : 22|2@1+ (1,0) [0|3] ""  ADAS_DRV,CLU,DATC,Dummy,FR_CMR,IBU_HS
 SG_ ExtLamp_ExtrnlTailLmpSta : 24|2@1+ (1,0) [0|0] ""  ADAS_PRK,CLU,DVRS,Dummy,FR_CMR,HUD,H_U_MM,RR_C_RDR,SVM
 SG_ ExtLamp_HzrdSwSta : 26|2@1+ (1,0) [0|0] ""  ADAS_DRV,ESC,FR_CMR,H_U_MM

BO_ 1044 ICU_05_200ms: 8 ICU
 SG_ C_CrashUnlockState : 58|2@1+ (1,0) [0|0] ""  ACU,ADAS_DRV,ADAS_PRK,ADM,AFCU_AST,AFCU_DRV,AFCU_RL,AFCU_RR,AFS,AHLS,AHV,APSM,APSU,ARS,AWD,BCM,BCW,BMS,CCM,CLU,CTM,DATC,DAU,DHV,DIBOX,DLBCU,DPSS,DPSU,DSS,DVRS,Dummy,ECS,ECW,EMS,EPB,ESC,ESU,FCS,FCU,FICU,FPCM,FR_CMR,FR_C_RDR_LH,FR_C_RDR_RH,GST,HCU,HFKS,HSWS,HUD,H_U_MM,IAU,IBU,IBU_HS,ICSC,ILCU_LH,ILCU_RH,LDC,LPI,MCU,MDPS,MFSW,MLM,OBC,ODS,OPI,OPU,PFSU,PSB,PSD,PSM,PSU,PTGM,RDC,RLHV,RLPSM,RRHV,RRPSM,RR_C_RDR,RR_C_RDR_LH,RWPC,RWS,SAS,SBW,SCM,SCU,SHVU_FR,SHVU_RR,SLB,SMK,SVM,SWRC,TCU,TPMS,VCU,VESS,WPC,YRS,eCall,vBDM

BO_ 1050 BCM_07_200ms: 8 IBU_HS
 SG_ BCM_Crc7Val : 0|8@1+ (1,0) [0|0] ""  ADAS_PRK,Dummy,FR_CMR,vBDM
 SG_ BCM_AlvCnt7Val : 12|4@1+ (1,0) [0|0] ""  ADAS_PRK,Dummy,FR_CMR
 SG_ Lamp_ExtrnlTailLmpOnReq : 38|2@1+ (1,0) [0|0] ""  ADAS_PRK,CLU,FR_CMR,HUD,H_U_MM,ICU,ILCU_LH,ILCU_RH
 SG_ Lamp_HdLmpLoOnReq : 40|2@1+ (1,0) [0|0] ""  AFS,FR_CMR,ILCU_LH,ILCU_RH
 SG_ Lamp_HdLmpHiOnReq : 42|2@1+ (1,0) [0|0] ""  FR_CMR,ILCU_LH,ILCU_RH
 SG_ Lamp_PassingLmpOnReq : 44|2@1+ (1,0) [0|0] ""  Dummy,FR_CMR

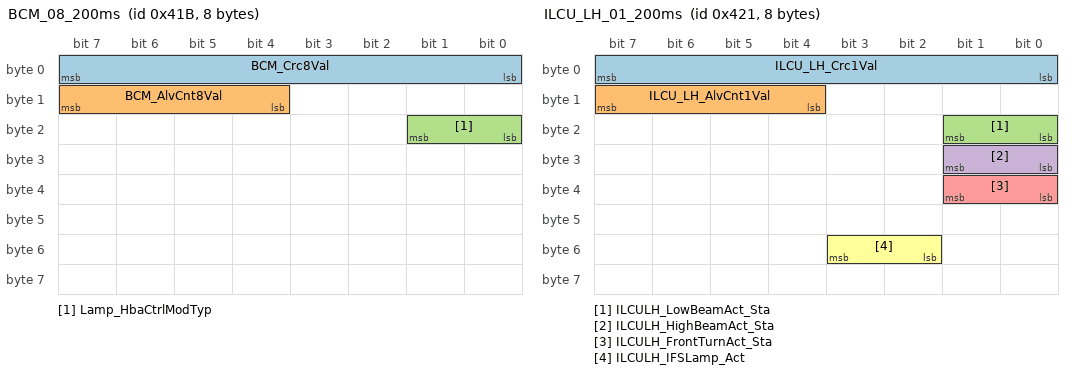
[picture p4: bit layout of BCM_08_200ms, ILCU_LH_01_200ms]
BO_ 1051 BCM_08_200ms: 8 IBU_HS
 SG_ BCM_Crc8Val : 0|8@1+ (1,0) [0|0] ""  Dummy,FR_CMR,vBDM
 SG_ BCM_AlvCnt8Val : 12|4@1+ (1,0) [0|0] ""  Dummy,FR_CMR
 SG_ Lamp_HbaCtrlModTyp : 16|2@1+ (1,0) [0|0] ""  Dummy,FR_CMR

BO_ 1052 BCM_09_200ms: 8 IBU_HS
 SG_ Lamp_AutoLtSnsrNightSta : 19|2@1+ (1,0) [0|0] ""  CLU,Dummy,ECS,FR_CMR,H_U_MM,RR_C_RDR,SML

BO_ 1057 ILCU_LH_01_200ms: 8 ILCU_LH
 SG_ ILCU_LH_Crc1Val : 0|8@1+ (1,0) [0|0] ""  ADAS_DRV,CLU,FR_CMR,IBU_HS,ICU
 SG_ ILCU_LH_AlvCnt1Val : 12|4@1+ (1,0) [0|0] ""  ADAS_DRV,CLU,FR_CMR,IBU_HS,ICU
 SG_ ILCULH_LowBeamAct_Sta : 16|2@1+ (1,0) [0|0] ""  CLU,Dummy,FR_CMR
 SG_ ILCULH_HighBeamAct_Sta : 24|2@1+ (1,0) [0|0] ""  CLU,Dummy,FR_CMR
 SG_ ILCULH_FrontTurnAct_Sta : 32|2@1+ (1,0) [0|0] ""  ADAS_DRV,Dummy,FR_CMR,ICU,RR_C_RDR
 SG_ ILCULH_IFSLamp_Act : 50|2@1+ (1,0) [0|0] ""  CLU,Dummy,FR_CMR

BO_ 1058 BCM_10_200ms: 8 IBU_HS
 SG_ Wiper_PrkngPosSta : 16|2@1+ (1,0) [0|0] ""  AFS,Dummy,ECS,FR_CMR
 SG_ Wiper_RainSnsrSta : 22|4@1+ (1,0) [0|0] ""  AFS,AWD,EMS,ESC,FR_CMR,H_U_MM

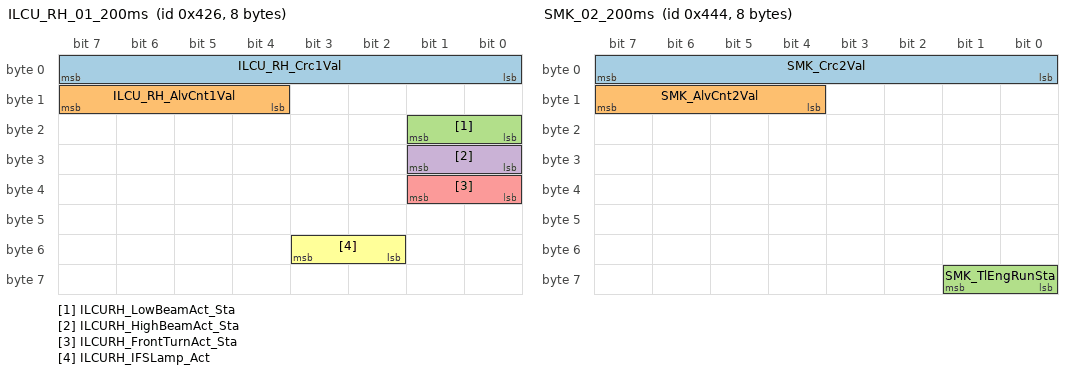
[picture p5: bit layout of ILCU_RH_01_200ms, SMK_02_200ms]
BO_ 1062 ILCU_RH_01_200ms: 8 ILCU_RH
 SG_ ILCU_RH_Crc1Val : 0|8@1+ (1,0) [0|0] ""  ADAS_DRV,CLU,Dummy,FR_CMR,IBU_HS,ICU
 SG_ ILCU_RH_AlvCnt1Val : 12|4@1+ (1,0) [0|0] ""  ADAS_DRV,CLU,Dummy,FR_CMR,IBU_HS,ICU
 SG_ ILCURH_LowBeamAct_Sta : 16|2@1+ (1,0) [0|0] ""  CLU,Dummy,FR_CMR
 SG_ ILCURH_HighBeamAct_Sta : 24|2@1+ (1,0) [0|0] ""  CLU,Dummy,FR_CMR
 SG_ ILCURH_FrontTurnAct_Sta : 32|2@1+ (1,0) [0|0] ""  ADAS_DRV,Dummy,FR_CMR,ICU,RR_C_RDR
 SG_ ILCURH_IFSLamp_Act : 50|2@1+ (1,0) [0|0] ""  CLU,Dummy,FR_CMR

BO_ 1076 IAU_16_200ms: 8 IAU
 SG_ IAU_ProfileIDRVal : 10|4@1+ (1,0) [0|0] ""  ACU,ADAS_DRV,ADAS_PRK,ADM,AFCU_AST,AFCU_DRV,AFCU_RL,AFCU_RR,AFS,AHLS,AHV,AMP,APSM,APSU,ARS,AWD,BCM,BCW,BMS,CCM,CGW,CLU,CLU_MM,CTM,DATC,DAU,DHV,DIBOX,DLBCU,DPSS,DPSU,DSS,DVRS,Dummy,ECS,ECW,EMS,EPB,ESC,ESU,FCS,FCU,FICU,FPCM,FR_CMR,FR_C_RDR_LH,FR_C_RDR_RH,GST,HCU,HFKS,HSWS,HUD,HUD_MM,H_U_MM,IBU,IBU_HS,ICSC,ICU,ILCU_LH,ILCU_RH,LDC,LPI,LSD,MCU,MDPS,MFSW,MKBD,MLM,MM_CGW,OBC,ODS,OPI,OPU,PFSU,PSB,PSD,PSM,PSU,PTGM,RDC,RLHV,RLPSM,RRHV,RRPSM,RR_C_RDR,RR_C_RDR_LH,RWPC,RWS,SAS,SBW,SBW_FF,SCM,SCU,SHVU_FR,SHVU_RR,SLB,SMK,SML,SVM,SWRC,TCU,TPMS,VCU,VESS,WPC,YRS,eCall,eCall_MM,vBDM

BO_ 1092 SMK_02_200ms: 8 IBU_HS
 SG_ SMK_Crc2Val : 0|8@1+ (1,0) [0|0] ""  ADAS_PRK,Dummy,FR_CMR
 SG_ SMK_AlvCnt2Val : 12|4@1+ (1,0) [0|0] ""  ADAS_PRK,Dummy,FR_CMR
 SG_ SMK_TlEngRunSta : 56|2@1+ (1,0) [0|0] ""  APSU,DLBCU,DPSS,DPSU,Dummy,FR_CMR,H_U_MM,ICU,PSM

BO_ 1097 BCM_13_200ms: 8 IBU_HS
 SG_ Lamp_ExtrnlTailLmpSta_BCM : 18|2@1+ (1,0) [0|0] ""  ADAS_PRK,Dummy,FR_CMR,HUD,H_U_MM,SVM
 SG_ Lamp_HzrdSwSta_BCM : 20|2@1+ (1,0) [0|0] ""  Dummy,ESC,FR_CMR

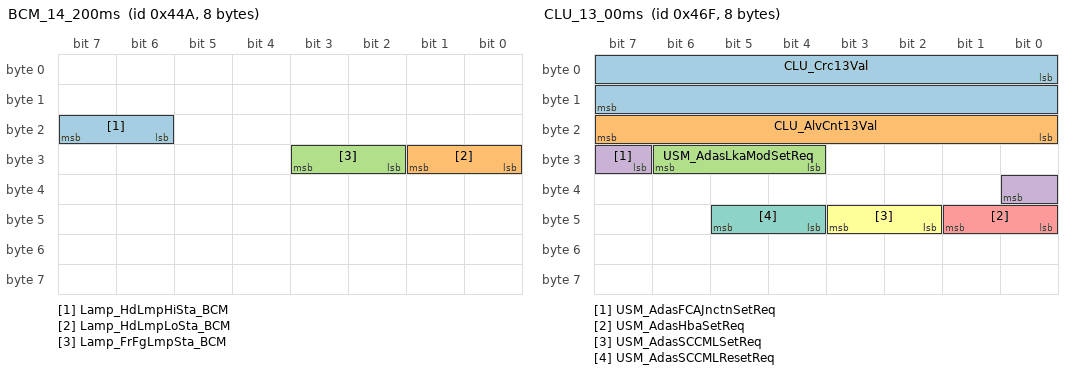
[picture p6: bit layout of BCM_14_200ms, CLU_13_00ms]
BO_ 1098 BCM_14_200ms: 8 IBU_HS
 SG_ Lamp_HdLmpHiSta_BCM : 22|2@1+ (1,0) [0|0] ""  AFS,CLU,Dummy,FR_CMR,HCU,H_U_MM
 SG_ Lamp_HdLmpLoSta_BCM : 24|2@1+ (1,0) [0|0] ""  AFS,CLU,Dummy,FR_CMR,HCU,H_U_MM
 SG_ Lamp_FrFgLmpSta_BCM : 26|2@1+ (1,0) [0|0] ""  AFS,CLU,Dummy,FR_CMR,H_U_MM

BO_ 1135 CLU_13_00ms: 8 CLU
 SG_ CLU_Crc13Val : 0|16@1+ (1,0) [0|65535] ""  Dummy,FR_CMR
 SG_ CLU_AlvCnt13Val : 16|8@1+ (1,0) [0|255] ""  Dummy,FR_CMR
 SG_ USM_AdasLkaModSetReq : 28|3@1+ (1,0) [0|7] ""  ADAS_DRV,FR_CMR
 SG_ USM_AdasFCAJnctnSetReq : 31|2@1+ (1,0) [0|3] ""  FR_CMR
 SG_ USM_AdasHbaSetReq : 40|2@1+ (1,0) [0|3] ""  FR_CMR
 SG_ USM_AdasSCCMLSetReq : 42|2@1+ (1,0) [0|3] ""  ADAS_DRV,FR_CMR
 SG_ USM_AdasSCCMLResetReq : 44|2@1+ (1,0) [0|3] ""  ADAS_DRV,FR_CMR

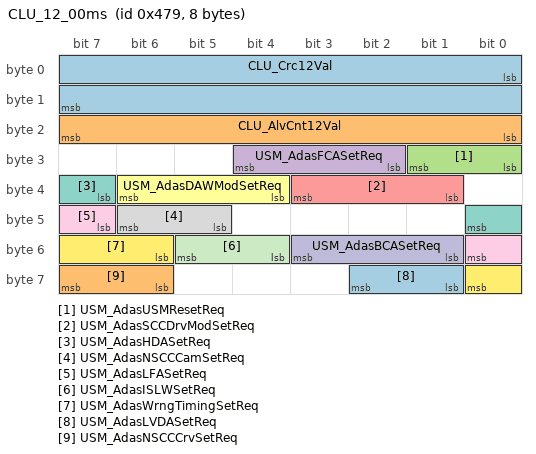
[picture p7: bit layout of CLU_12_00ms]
BO_ 1145 CLU_12_00ms: 8 CLU
 SG_ CLU_Crc12Val : 0|16@1+ (1,0) [0|65535] ""  FR_CMR
 SG_ CLU_AlvCnt12Val : 16|8@1+ (1,0) [0|255] ""  Dummy,FR_CMR
 SG_ USM_AdasUSMResetReq : 24|2@1+ (1,0) [0|3] ""  ADAS_DRV,ADAS_PRK,FR_CMR,RR_C_RDR
 SG_ USM_AdasFCASetReq : 26|3@1+ (1,0) [0|7] ""  ADAS_DRV,FR_CMR
 SG_ USM_AdasSCCDrvModSetReq : 33|3@1+ (1,0) [0|0] ""  FR_CMR
 SG_ USM_AdasDAWModSetReq : 36|3@1+ (1,0) [0|7] ""  ADAS_DRV,FR_CMR
 SG_ USM_AdasHDASetReq : 39|2@1+ (1,0) [0|3] ""  ADAS_DRV,FR_CMR
 SG_ USM_AdasNSCCCamSetReq : 45|2@1+ (1,0) [0|3] ""  FR_CMR
 SG_ USM_AdasLFASetReq : 47|2@1+ (1,0) [0|3] ""  ADAS_DRV,FR_CMR
 SG_ USM_AdasBCASetReq : 49|3@1+ (1,0) [0|7] ""  ADAS_DRV,FR_CMR,RR_C_RDR
 SG_ USM_AdasISLWSetReq : 52|2@1+ (1,0) [0|3] ""  ADAS_DRV,FR_CMR
 SG_ USM_AdasWrngTimingSetReq : 54|3@1+ (1,0) [0|7] ""  ADAS_DRV,FR_CMR,RR_C_RDR
 SG_ USM_AdasLVDASetReq : 57|2@1+ (1,0) [0|3] ""  ADAS_DRV,FR_CMR
 SG_ USM_AdasNSCCCrvSetReq : 62|2@1+ (1,0) [0|0] ""  FR_CMR

CM_ BO_ 388 "[P] Periodic";
CM_ SG_ 388 FR_CMR_Obj_Crc05Val "FR_CMR_Obj_CyclicRedundancyCheck05Value";
CM_ SG_ 388 FR_CMR_Obj_AlvCnt05Val "FR_CMR_Obj_AliveCounter05Value";
CM_ SG_ 388 FR_CMR_Obj_QualLvl09Sta "FR_CMR_Obj_QualityLevel09Value";
CM_ SG_ 388 FR_CMR_Obj_AlvAge09Val "FR_CMR_Obj_AliveAge09Value";
CM_ SG_ 388 FR_CMR_Obj_MvngFlag09Sta "FR_CMR_Obj_MovingFlag09Status";
CM_ SG_ 388 FR_CMR_Obj_Id09Val "FR_CMR_Obj_ID09Value";
CM_ SG_ 388 FR_CMR_Obj_Wth09Val "FR_CMR_Obj_Width09Value";
CM_ SG_ 388 FR_CMR_Obj_Clfct09Sta "FR_CMR_Obj_Classification09Status";
CM_ SG_ 388 FR_CMR_Obj_RelPosX09Val "FR_CMR_Obj_RelativePositionX09Value";
CM_ SG_ 388 FR_CMR_Obj_RelPosY09Val "FR_CMR_Obj_RelativePositionY09Value";
CM_ SG_ 388 FR_CMR_Obj_RelVelX09Val "FR_CMR_Obj_RelativeVelocityX09Value";
CM_ SG_ 388 FR_CMR_Obj_RelVelY09Val "FR_CMR_Obj_RelativeVelocityY09Value";
CM_ SG_ 388 FR_CMR_Obj_RelAccelX09Val "FR_CMR_Obj_RelativeAccelerationX09Value";
CM_ SG_ 388 FR_CMR_Obj_QualLvl10Sta "FR_CMR_Obj_QualityLevel10Value";
CM_ SG_ 388 FR_CMR_Obj_AlvAge10Val "FR_CMR_Obj_AliveAge10Value";
CM_ SG_ 388 FR_CMR_Obj_MvngFlag10Sta "FR_CMR_Obj_MovingFlag10Status";
CM_ SG_ 388 FR_CMR_Obj_Id10Val "FR_CMR_Obj_ID10Value";
CM_ SG_ 388 FR_CMR_Obj_Wth10Val "FR_CMR_Obj_Width10Value";
CM_ SG_ 388 FR_CMR_Obj_Clfct10Sta "FR_CMR_Obj_Classification10Status";
CM_ SG_ 388 FR_CMR_Obj_RelPosX10Val "FR_CMR_Obj_RelativePositionX10Value";
CM_ SG_ 388 FR_CMR_Obj_RelPosY10Val "FR_CMR_Obj_RelativePositionY10Value";
CM_ SG_ 388 FR_CMR_Obj_RelVelX10Val "FR_CMR_Obj_RelativeVelocityX10Value";
CM_ SG_ 388 FR_CMR_Obj_RelVelY10Val "FR_CMR_Obj_RelativeVelocityY10Value";
CM_ SG_ 388 FR_CMR_Obj_RelAccelX10Val "FR_CMR_Obj_RelativeAccelerationX10Value";
CM_ BO_ 389 "[P] Periodic";
CM_ SG_ 389 FR_CMR_Genrl_Crc01Val "FR_CMR_Genrl_CyclicRedundancyCheck01Value";
CM_ SG_ 389 FR_CMR_Genrl_AlvCnt01Val "FR_CMR_Genrl_AliveCounter01Value";
CM_ SG_ 389 FR_CMR_Genrl_DetObjNumVal "FR_CMR_Genrl_DetectionObjectNumberValue";
CM_ SG_ 389 FR_CMR_Genrl_DetLnNumVal "FR_CMR_Genrl_DetectionLineNumberValue";
CM_ SG_ 389 FR_CMR_Genrl_FlInfoSta "FR_CMR_Genrl_FailInformationStatus";
CM_ SG_ 389 FR_CMR_Genrl_SnsrLatencyVal "FR_CMR_Genrl_SensorLatencyValue";
CM_ SG_ 389 FR_CMR_Genrl_DayTimeIndicatorSta "FR_CMR_Genrl_DayTimeIndicatorStatus";
CM_ BO_ 416 "[P] Periodic";
CM_ SG_ 416 ADAS_CMD_Crc20Val "ADAS_CMD_CyclicRedundancyCheck20Value ##2G##SCC - SCC12 - CR_VSM_ChkSum";
CM_ SG_ 416 ADAS_CMD_AlvCnt20Val "ADAS_CMD_AliveCounter20Value ##2G##SCC - SCC12 - CR_VSM_Alive";
CM_ SG_ 416 SCC_ObjDstVal "SCC_ObjectDistanceValue ##2G##SCC - SCC11 - SCC_ObjDist";
CM_ SG_ 416 SCC_ObjRelSpdVal "SCC_ObjectRelativeSpeedValue ##2G##SCC - SCC11 - SCC_ObjRelSpd";
CM_ SG_ 416 SCC_ObjLatPosVal "SCC_ObjectLateralPositionValue ##2G##SCC - SCC11 - SCC_ObjLatPos";
CM_ SG_ 416 SCC_SysFlrSta "SCC_SystemFailureStatus ##2G##SCC - SCC12 - SCCFailInfo";
CM_ SG_ 416 SCC_MainOnOffSta "SCC_MainOnOffStatus ##2G##SCC - SCC11 - MainMode_SCC";
CM_ SG_ 416 SCC_OpSta "SCC_OperatingStatus ##2G##SCC - SCC14 - SCCMode2";
CM_ SG_ 416 SCC_TakeoverReq "SCC_TakeoverRequest ##2G##SCC - SCC12 - TakeOverReq";
CM_ SG_ 416 SCC_InfoDis "SCC_InformationDisplay ##2G##SCC - SCC11 - SCCInfoDisplay";
CM_ SG_ 416 SCC_DrvAlrtDis "SCC_DriverAlertDisplay ##2G##SCC - SCC11 - DriverAlertDisplay";
CM_ SG_ 416 SCC_ObjDstLvlVal "SCC_ObjectDistanceLevelValue ##2G##SCC - SCC14 - ObjGap";
CM_ SG_ 416 SCC_HeadwayDstSetVal "SCC_HeadwayDistanceSettingValue ##2G##SCC - SCC11 - TauGapSet";
CM_ SG_ 416 SCC_EquipSta "SCC_EquipmentStatus ##2G##SCC - SCC13 - SCC_Equip";
CM_ SG_ 416 SCC_TrgtSpdSetVal "SCC_TargetSpeedSettingValue ##2G##SCC - SCC11 - VSetDis";
CM_ SG_ 416 SCC_NSCCOpSta "SCC_NSCCOperatingStatus ##2G##SCC - SCC11 - NSCC_Camera_Act";
CM_ SG_ 416 SCC_NSCCOnOffSta "SCC_NSCCOnOffStatus ##2G##SCC - SCC13 - NSCC_Zone_USM";
CM_ SG_ 416 SCC_ObjSta "SCC_ObjectState";
CM_ SG_ 416 SCC_SnstvtyModRetVal "SCC_SensitivityModeReturnValue ##2G##SCC - SCC13 - SCCDrvModeRValue";
CM_ SG_ 416 SCC_AccelReqVal "SCC_AccelerationRequestValue ##2G##SCC - SCC12 - aReqValue";
CM_ SG_ 416 SCC_AccelReqRawVal "SCC_AccelerationRequestRawValue ##2G##SCC - SCC12 - aReqRaw";
CM_ SG_ 416 SCC_JrkUppLimVal "SCC_JerkUpperLimitValue ##2G##SCC - SCC14 - JerkUpperLimit";
CM_ SG_ 416 SCC_JrkLwrLimVal "SCC_JerkLowerLimitValue ##2G##SCC - SCC14 - JerkLowerLimit";
CM_ SG_ 416 SCC_AccelLimBandUppVal "SCC_AccelerationLimitBandUpperValue ##2G##SCC - SCC14 - ComfortBandUpper";
CM_ SG_ 416 SCC_AccelLimBandLwrVal "SCC_AccelerationLimitBandLowerValue ##2G##SCC - SCC14 - ComfortBandLower";
CM_ SG_ 416 SCC_VehStpReq "SCC_VehicleStopRequest ##2G##SCC - SCC12 - StopReq";
CM_ SG_ 416 SCC_TrgtDstVal "SCC_TargetDistanceValue";
CM_ BO_ 426 "[P] Periodic";
CM_ SG_ 426 CLU_Crc1Val "CLU_CyclicRedundancyCheck1Value";
CM_ SG_ 426 CLU_AlvCnt1Val "CLU_AliveCounter1Value";
CM_ SG_ 426 CLU_DtntOutSta "CLU_DetentOutStatus";
CM_ SG_ 426 CLU_SpdUnitTyp "CLU_SpeedUnitType";
CM_ SG_ 426 CLU_SWRCLFASwSta "SWRC_LFASwitchStatus";
CM_ SG_ 426 CLU_RhstaLvlSta "CLU_RheostatLevelStatus";
CM_ SG_ 426 CLU_DisSpdVal "CLU_DisplaySpeedValue";
CM_ BO_ 437 "[P] Periodic";
CM_ SG_ 437 FR_CMR_Crc3Val "FR_CMR_CyclicRedundancyCheck3Value";
CM_ SG_ 437 FR_CMR_AlvCnt3Val "FR_CMR_AliveCounter3Value";
CM_ SG_ 437 Info_LftLnQualSta "Info_LeftLineQualityStatus ##2G##LDW_LKA - LKA14 - CF_LeftLine_Quality";
CM_ SG_ 437 Info_LftLnDptSta "Info_LeftLineDepartureStatus ##2G##LDW_LKA - LKA14 - CF_LeftLine_Departure";
CM_ SG_ 437 Info_LftLnPosVal "Info_LeftLinePositionValue ##2G##LDW_LKA - LKA14 - CF_LeftLine_Position";
CM_ SG_ 437 Info_LftLnHdingAnglVal "Info_LeftLineHeadingAngleValue ##2G##LDW_LKA - LKA14 - CF_LeftLine_HeadingAngle";
CM_ SG_ 437 Info_LftLnCvtrVal "Info_LeftLineCurvatureValue";
CM_ SG_ 437 Info_LftLnCrvtrDrvtvVal "Info_LeftLineCurvatureDerivativeValue";
CM_ SG_ 437 Info_RtLnQualSta "Info_RightLineQualityStatus ##2G##LDW_LKA - LKA14 - CF_RightLine_Quality";
CM_ SG_ 437 Info_RtLnDptSta "Info_RightLineDepartureStatus ##2G##LDW_LKA - LKA14 - CF_RightLine_Departure";
CM_ SG_ 437 Info_RtLnPosVal "Info_RightLinePositionValue ##2G##LDW_LKA - LKA14 - CF_RightLine_Position";
CM_ SG_ 437 Info_RtLnHdingAnglVal "Info_RightLineHeadingAngleValue ##2G##LDW_LKA - LKA14 - CF_RightLine_HeadingAngle";
CM_ SG_ 437 Info_RtLnCvtrVal "Info_RightLineCurvatureValue";
CM_ SG_ 437 Info_RtLnCrvtrDrvtvVal "Info_RightLineCurvatureDerivativeValue";
CM_ BO_ 442 "[P] Periodic";
CM_ SG_ 442 ADAS_CMD_AlvCnt40Val "ADAS_CMD_AliveCounter40Value ##2G##BCW - BCA11 - AliveCounter";
CM_ SG_ 442 BCA_Sta "BCA_Status ##2G##BCW - BCA11 - CF_BCA_State";
CM_ SG_ 442 BCA_LftWrngSta "BCA_LeftWarningStatus ##2G##BCW - BCA11 - CF_BCA_Warning";
CM_ SG_ 442 BCA_RtWrngSta "BCA_RightWarningStatus ##2G##BCW - BCA11 - CF_BCA_Warning";
CM_ BO_ 463 "[P] Periodic";
CM_ SG_ 463 SWRC_Crc3Val "SWRC_CyclicRedundancyCheck3Value";
CM_ SG_ 463 SWRC_AlvCnt3Val "SWRC_AliveCounter3Value";
CM_ SG_ 463 SWRC_CrsSwSta "SWRC_CruiseSwitchStatus";
CM_ SG_ 463 SWRC_CrsMainSwSta "SWRC_CruiseMainSwitchStatus";
CM_ SG_ 463 SWRC_SldMainSwSta "SWRC_SpeedLimiterMainSwitchStatus";
CM_ SG_ 463 SWRC_LFASwSta "SWRC_LFASwitchStatus";
CM_ BO_ 480 "[P] Periodic";
CM_ SG_ 480 ADAS_CMD_Crc31Val "ADAS_CMD_CyclicRedundancyCheck31Value";
CM_ SG_ 480 ADAS_CMD_AlvCnt31Val "ADAS_CMD_AliveCounter31Value";
CM_ SG_ 480 HDA_OptUsmSta "HDA_OptionUSMStatus ##2G##LDW_LKA - HDA11 - CF_HDA_Opt_USM";
CM_ SG_ 480 LFA_OptUsmSta "LFA_OptionUSMStatus ##2G##LDW_LKA - HDA11 - CF_LFA_Opt_USM";
CM_ SG_ 480 HDA_CntrlModSta "HDA_ControlModeStatus ##2G##LDW_LKA - HDA11 - CF_HDA_Mode";
CM_ SG_ 480 HDA_InfoPUDis "HDA_InformationPopUpDisplay ##2G##LDW_LKA - HDA11 - CF_HDA_InfoDisplay";
CM_ SG_ 480 HDA_AutoSetSpdSta "HDA_AutoSetSpeedStatus ##2G##LDW_LKA - HDA11 - CF_HDA_AutoSetSpdEnable";
CM_ SG_ 480 HDA_AutoSetSpdUpdtSta "HDA_AutoSetSpeedUpdateStatus ##2G##LDW_LKA - HDA11 - CF_HDA_AutoSetSpdUpdate";
CM_ SG_ 480 HDA_AutoSetSpdVal "HDA_AutoSetSpeedValue ##2G##LDW_LKA - HDA11 - CF_HDA_AutoSetSpd";
CM_ SG_ 480 HDA_LFA_SymSta "HDA_LFA_SymbolStatus ##2G##LDW_LKA - HDA11 - CF_HDA_LFA_SymbolState";
CM_ SG_ 480 HDA_LFA_WrnSnd "HDA/LFA Additional Warning Sound";
CM_ BO_ 506 "[P] Periodic";
CM_ SG_ 506 FR_CMR_Crc2Val "FR_CMR_CyclicRedundancyCheck2Value";
CM_ SG_ 506 FR_CMR_AlvCnt2Val "FR_CMR_AliveCounter2Value";
CM_ SG_ 506 ISLW_OptUsmSta "ISLW_OptionUsmStatus ##2G##LDW_LKA - LKA12 - CF_ISLW_Opt_USM";
CM_ SG_ 506 ISLW_SysSta "ISLW_SystemStatus ##2G##LDW_LKA - LKA12 - CF_ISLW_Status";
CM_ SG_ 506 ISLW_NoPassingInfoDis "ISLW_NoPassingInfoDisplay ##2G##LDW_LKA - LKA12 - CF_ISLW_Addinfo_Display";
CM_ SG_ 506 ISLW_OvrlpSignDis "ISLW_OverlapSignDisplay ##2G##LDW_LKA - LKA12 - CF_ISLW_OvrlapSign_Dis";
CM_ SG_ 506 ISLW_SpdCluMainDis "ISLW_SpeedCluMainDisplay ##2G##LDW_LKA - LKA12 - CF_ISLW_Spd_Dis_CLU_Main";
CM_ SG_ 506 ISLW_SpdNaviMainDis "ISLW_SpeedNaviMainDisplay ##2G##LDW_LKA - LKA12 - CF_ISLW_Spd_Dis_NAVI_Main";
CM_ SG_ 506 ISLW_SubCondinfoSta1 "ISLW_SubConditionInformationStatus1 ##2G##LDW_LKA - LKA13 - CF_ISLW_ConInfo_Sta_Con1";
CM_ SG_ 506 ISLW_SubCondinfoSta2 "ISLW_SubConditionInformationStatus2 ##2G##LDW_LKA - LKA13 - CF_ISLW_ConInfo_Sta_Con2";
CM_ SG_ 506 ISLW_SpdCluSubMainDis "ISLW_SpeedClusterSubMainDisplay ##2G##LDW_LKA - LKA13 - CF_ISLW_Speed_Dis_Clu_ConM";
CM_ SG_ 506 ISLW_SpdCluDisSubCond1 "ISLW_SpeedCluDisplaySubCondition1 ##2G##LDW_LKA - LKA13 - CF_ISLW_Spd_Dis_CLU_Con1";
CM_ SG_ 506 ISLW_SpdCluDisSubCond2 "ISLW_SpeedCluDisplaySubCondition2 ##2G##LDW_LKA - LKA13 - CF_ISLW_Spd_Dis_CLU_Con2";
CM_ SG_ 506 ISLW_SpdNaviSubMainDis "ISLW_SpeedNaviSubMainDisplay ##2G##LDW_LKA - LKA13 - CF_ISLW_Speed_Dis_NAVI_ConM";
CM_ SG_ 506 ISLW_SpdNaviDisSubCond1 "ISLW_SpeedNaviDisplaySubCondition1 ##2G##LDW_LKA - LKA13 - CF_ISLW_Spd_Dis_NAVI_Con1";
CM_ SG_ 506 ISLW_SpdNaviDisSubCond2 "ISLW_SpeedNaviDisplaySubCondition2 ##2G##LDW_LKA - LKA13 - CF_ISLW_Spd_Dis_NAVI_Con1";
CM_ BO_ 549 "[P] Periodic";
CM_ SG_ 549 CLU_AlvCnt2Val "CLU_AliveCounter2Value";
CM_ SG_ 549 CLU_TerrainMainSwSta "CLU_TerrainMainSwitchStatus";
CM_ SG_ 549 CLU_OdoVal "CLU_OdometerValue";
CM_ SG_ 549 CLU_DawLastBrkTimeVal "CLU_DawLastBreakTimeValue";
CM_ SG_ 549 CLU_IceWrnIndSta "CLU_IceWarnIndicatorStatus";
CM_ SG_ 549 CLU_DrvngModSwSta "CLU_DrivingModeSwitchStatus";
CM_ SG_ 549 CLU_TerrainModSwSta "CLU_TerrainModeSwitchStatus";
CM_ BO_ 560 "[P] Periodic";
CM_ SG_ 560 HCU_BrkLmpOnReq "HCU_BrakeLampOnRequest";
CM_ BO_ 608 "[P] Periodic";
CM_ SG_ 608 ENG_TransmsnTyp "ENG_TransmissionType";
CM_ SG_ 608 ENG_EngDsplceTyp "ENG_EngineDisplacementType ##2G##EMS - EMS12 - ENG_VOL";
CM_ BO_ 613 "[P] Periodic";
CM_ SG_ 613 HEV_BrkLtSwSta "HEV_BrakeLightSwitchStatus";
CM_ BO_ 661 "[P] Periodic";
CM_ SG_ 661 OBD_EngRpmVal "OBD_EngineRpmValue ##2G##EMS - EngFrzFrm11 - PID_0Ch";
CM_ BO_ 674 "[P] Periodic";
CM_ SG_ 674 FR_CMR_Ln_Crc01Val "FR_CMR_Ln_CyclicRedundancyCheck01Value";
CM_ SG_ 674 FR_CMR_Ln_AlvCnt01Val "FR_CMR_Ln_AliveCounter01Value";
CM_ SG_ 674 FR_CMR_Ln_LftDptDstVal "FR_CMR_Ln_LeftDepartureDistanceValue";
CM_ SG_ 674 FR_CMR_Ln_RtDptDstVal "FR_CMR_Ln_RightDepartureDistanceValue";
CM_ SG_ 674 FR_CMR_Ln_LftDptAnglVal "FR_CMR_Ln_LeftDepartureAngleValue";
CM_ SG_ 674 FR_CMR_Ln_RtDptAnglVal "FR_CMR_Ln_RightDepartureAngleValue";
CM_ SG_ 674 FR_CMR_Ln_LftCurveVal "FR_CMR_Ln_LeftCurvatureValue";
CM_ SG_ 674 FR_CMR_Ln_RtCurveVal "FR_CMR_Ln_RightCurvatureValue";
CM_ SG_ 674 FR_CMR_Ln_LftCurveRatVal "FR_CMR_Ln_LeftCurvatureRateValue";
CM_ SG_ 674 FR_CMR_Ln_RtCurveRatVal "FR_CMR_Ln_RightCurvatureRateValue";
CM_ BO_ 675 "[P] Periodic";
CM_ SG_ 675 FR_CMR_Ln_Crc02Val "FR_CMR_Ln_CyclicRedundancyCheck02Value";
CM_ SG_ 675 FR_CMR_Ln_AlvCnt02Val "FR_CMR_Ln_AliveCounter02Value";
CM_ SG_ 675 FR_CMR_Ln_LftNextLnDptDstVal "FR_CMR_Ln_LeftNextDepartureDistanceValue";
CM_ SG_ 675 FR_CMR_Ln_RtNextDptDstVal "FR_CMR_Ln_RightNextDepartureDistanceValue";
CM_ SG_ 675 FR_CMR_Ln_LftNextDptAnglVal "FR_CMR_Ln_LeftNextDepartureAngleValue";
CM_ SG_ 675 FR_CMR_Ln_RtNextDptAnglVal "FR_CMR_Ln_RightNextDepartureAngleValue";
CM_ SG_ 675 FR_CMR_Ln_LftNextCurveVal "FR_CMR_Ln_LeftNextCurvatureValue";
CM_ SG_ 675 FR_CMR_Ln_RtNextCurveVal "FR_CMR_Ln_RightNextCurvatureValue";
CM_ SG_ 675 FR_CMR_Ln_LftNextCurveRatVal "FR_CMR_Ln_LeftNextCurvatureRateValue";
CM_ SG_ 675 FR_CMR_Ln_RtNextCurveRatVal "FR_CMR_Ln_RightNextCurvatureRateValue";
CM_ BO_ 676 "[P] Periodic";
CM_ SG_ 676 FR_CMR_Ln_Crc03Val "FR_CMR_Ln_CyclicRedundancyCheck03Value";
CM_ SG_ 676 FR_CMR_Ln_AlvCnt03Val "FR_CMR_Ln_AliveCounter03Value";
CM_ SG_ 676 FR_CMR_Ln_WthLnLft01Val "FR_CMR_Ln_WidthLineLeft01Value";
CM_ SG_ 676 FR_CMR_Ln_WthLnRt01Val "FR_CMR_Ln_WidthLineRight01Value";
CM_ SG_ 676 FR_CMR_Ln_ClfctLft01Sta "FR_CMR_Ln_ClassificationLeft01Status";
CM_ SG_ 676 FR_CMR_Ln_ClfctRt01Sta "FR_CMR_Ln_ClassificationRight01Status";
CM_ SG_ 676 FR_CMR_Ln_LftClr01Sta "FR_CMR_Ln_LeftColor01Status";
CM_ SG_ 676 FR_CMR_Ln_RtClr01Sta "FR_CMR_Ln_RightColor01Status";
CM_ SG_ 676 FR_CMR_Ln_QualLvlLft01Sta "FR_CMR_Ln_QualityLevelLeft01Status";
CM_ SG_ 676 FR_CMR_Ln_QualLvlRt01Sta "FR_CMR_Ln_QualityLevelRight01Status";
CM_ SG_ 676 FR_CMR_Ln_ClfctLft02Sta "FR_CMR_Ln_ClassificationLeft02Status";
CM_ SG_ 676 FR_CMR_Ln_ClfctRt02Sta "FR_CMR_Ln_ClassificationRight02Status";
CM_ SG_ 676 FR_CMR_Ln_QualLvlLft02Sta "FR_CMR_Ln_QualityLevelLeft02Status";
CM_ SG_ 676 FR_CMR_Ln_QualLvlRt02Sta "FR_CMR_Ln_QualityLevelRight02Status";
CM_ SG_ 676 FR_CMR_Ln_LftViewRngVal "FR_CMR_Ln_LeftViewRangeValue";
CM_ SG_ 676 FR_CMR_Ln_RtViewRngVal "FR_CMR_Ln_RightViewRangeValue";
CM_ BO_ 698 "[EW] On Event and On Write";
CM_ SG_ 698 FR_CMR_Crc4Val "FR_CMR_CyclicRedundancyCheck4Value";
CM_ SG_ 698 FR_CMR_AlvCnt4Val "FR_CMR_AliveCounter4Value";
CM_ SG_ 698 IFSref_FR_CMR_Sta "IFSref_FR_CMR_Status";
CM_ SG_ 698 IFSref_VehNumVal "IFSref_VehicleNumberValue";
CM_ SG_ 698 IFSref_ILLAmbtSta "IFSref_IlluminationAmbientStatus";
CM_ SG_ 698 IFSref_VehLftAngl1Val "IFSref_VehicleLeftAngle1Value";
CM_ SG_ 698 IFSref_VehRtAngl1Val "IFSref_VehicleRightAngle1Value";
CM_ SG_ 698 IFSref_VehLftAngl2Val "IFSref_VehicleLeftAngle2Value";
CM_ SG_ 698 IFSref_VehDst1Val "IFSref_VehicleDistance1Value";
CM_ SG_ 698 IFSref_VehRtAngl2Val "IFSref_VehicleRightAngle2Value";
CM_ SG_ 698 IFSref_VehLftAngl3Val "IFSref_VehicleLeftAngle3Value";
CM_ SG_ 698 IFSref_VehRtAngl3Val "IFSref_VehicleRightAngle3Value";
CM_ SG_ 698 IFSref_VehLftAngl4Val "IFSref_VehicleLeftAngle4Value";
CM_ SG_ 698 IFSref_VehRtAngl4Val "IFSref_VehicleRightAngle4Value";
CM_ SG_ 698 IFSref_VehLftAngl5Val "IFSref_VehicleLeftAngle5Value";
CM_ SG_ 698 IFSref_VehRtAngl5Val "IFSref_VehicleRightAngle5Value";
CM_ SG_ 698 IFSref_VehLftAngl6Val "IFSref_VehicleLeftAngle6Value";
CM_ SG_ 698 IFSref_VehRtAngl6Val "IFSref_VehicleRightAngle6Value";
CM_ SG_ 698 IFSref_VehLftAngl7Val "IFSref_VehicleLeftAngle7Value";
CM_ SG_ 698 IFSref_VehRtAngl7Val "IFSref_VehicleRightAngle7Value";
CM_ SG_ 698 IFSref_VehLftAngl8Val "IFSref_VehicleLeftAngle8Value";
CM_ SG_ 698 IFSref_VehRtAngl8Val "IFSref_VehicleRightAngle8Value";
CM_ SG_ 698 IFSref_VehLftAngl9Val "IFSref_VehicleLeftAngle9Value";
CM_ SG_ 698 IFSref_VehRtAngl9Val "IFSref_VehicleRightAngle9Value";
CM_ SG_ 698 IFSref_VehLftAngl10Val "IFSref_VehicleLeftAngle10Value";
CM_ SG_ 698 IFSref_VehRtAngl10Val "IFSref_VehicleRightAngle10Value";
CM_ SG_ 698 IFSref_VehDst2Val "IFSref_VehicleDistance2Value";
CM_ SG_ 698 IFSref_VehDst3Val "IFSref_VehicleDistance3Value";
CM_ SG_ 698 IFSref_VehDst4Val "IFSref_VehicleDistance4Value";
CM_ SG_ 698 IFSref_VehDst5Val "IFSref_VehicleDistance5Value";
CM_ SG_ 698 IFSref_VehDst6Val "IFSref_VehicleDistance6Value";
CM_ SG_ 698 IFSref_VehDst7Val "IFSref_VehicleDistance7Value";
CM_ SG_ 698 IFSref_VehDst8Val "IFSref_VehicleDistance8Value";
CM_ SG_ 698 IFSref_VehDst9Val "IFSref_VehicleDistance9Value";
CM_ SG_ 698 IFSref_VehDst10Val "IFSref_VehicleDistance10Value";
CM_ BO_ 720 "[P] Periodic";
CM_ SG_ 720 TCU_Crc3Val "TCU_CyclicRedundancyCheck3Value";
CM_ SG_ 720 TCU_AlvCnt3Val "TCU_AliveCounter3Value";
CM_ SG_ 720 TCU_WrngMsgSta "TCU_WarningMessageStatus";
CM_ BO_ 832 "[P] Periodic";
CM_ SG_ 832 HEV_OBD_EngRpmVal "OBD_EngineRpmValue ##2G##EMS - EngFrzFrm11 - PID_0Ch";
CM_ BO_ 934 "[PE] Periodic and On Event";
CM_ BO_ 961 "[PE] Periodic and On Event";
CM_ SG_ 961 MFSW_Crc1Val "MFSW_CyclicRedundancyCheck1Value";
CM_ SG_ 961 MFSW_AlvCnt1Val "MFSW_AliveCounter1Value";
CM_ SG_ 961 Lamp_HdLmpHiSwSta "Lamp_HeadLampHighSwitchStatus";
CM_ SG_ 961 Lamp_LtSwSta "Lamp_LightSwitchStatus";
CM_ SG_ 961 Lamp_OneTouchTrnSigLftSwSta "Lamp_OneTouchTurnSignalLeftSwitchStatus";
CM_ SG_ 961 Lamp_OneTouchTrnSigRtSwSta "Lamp_OneTouchTurnSignalRightSwitchStatus";
CM_ SG_ 961 Lamp_PassingLmpSwSta "Lamp_PassingLampSwitchStatus";
CM_ SG_ 961 Lamp_TrnSigLftSwSta "Lamp_TurnSignalLeftSwitchStatus";
CM_ SG_ 961 Lamp_TrnSigRtSwSta "Lamp_TurnSignalRightSwitchStatus";
CM_ SG_ 961 Lamp_LaneChgTrnSigLftSwSta "Lamp_LaneChangeTurnSignalLeftSwitchStatus";
CM_ SG_ 961 Lamp_LaneChgTrnSigRtSwSta "Lamp_LaneChangeTurnSignalRightSwitchStatus";
CM_ BO_ 962 "[PE] Periodic and On Event";
CM_ SG_ 962 MFSW_Crc2Val "MFSW_CyclicRedundancyCheck2Value";
CM_ SG_ 962 MFSW_AlvCnt2Val "MFSW_AliveCounter2Value";
CM_ SG_ 962 Wiper_FrWiperSwSta "Wiper_FrontWiperSwitchStatus";
CM_ SG_ 962 Wiper_IntStepSta "Wiper_IntermittentStepStatus";
CM_ BO_ 1035 "[PE] Periodic and On Event";
CM_ SG_ 1035 ExtLamp_IRLmpLftFlSta "ExtLamp_IRLampLeftFailStatus";
CM_ SG_ 1035 ExtLamp_IRLmpRtFlSta "ExtLamp_IRLampRightFailStatus";
CM_ BO_ 1041 "[PE] Periodic and On Event";
CM_ SG_ 1041 ICU_Crc2Val "ICU_CyclicRedundancyCheck2Value";
CM_ SG_ 1041 ICU_AlvCnt2Val "ICU_AliveCounter2Value";
CM_ SG_ 1041 Warn_DrvDrSwSta "DoorLock_DriverDoorSwitchStatus ##2G## -  - C_DrvDrSw,CF_Gway_DrvDrSw,Warn_DrvDrSwSta";
CM_ SG_ 1041 Warn_AsstDrSwSta "Warn_AssistDoorSwitchStatus ##2G## -  - C_AstDrSw,CF_Gway_AstDrSw,Warn_AsstDrSwSta";
CM_ SG_ 1041 Warn_DrvStBltSwSta "Warn_DriverSeatbeltSwitchStatus ##2G## -  - C_DrvSeatBeltSw,CF_Gway_DrvSeatBeltSw";
CM_ SG_ 1041 Warn_RrLftDrSwSta "Warn_RearLeftDoorSwitchStatus ##2G## -  - C_RLDrSw,CF_Gway_RLDrSw,Warn_RrLftDrSwSta";
CM_ SG_ 1041 Warn_RrRtDrSwSta "Warn_RearRightDoorSwitchStatus ##2G## -  - C_RRDrSw,CF_Gway_RRDrSw,Warn_RrRtDrSwSta";
CM_ BO_ 1043 "[PE] Periodic and On Event";
CM_ SG_ 1043 ICU_Crc4Val "ICU_CyclicRedundancyCheck4Value";
CM_ SG_ 1043 ICU_AlvCnt4Val "ICU_AliveCounter4Value";
CM_ SG_ 1043 ExtLamp_FrFgLmpSta "ExtLamp_FrontFogLampStatus ##2G## -  - C_FrtFogAct";
CM_ SG_ 1043 ExtLamp_TrnSigLmpLftBlnkngSta "ExtLamp_TurnSignalLampLeftBlinkingStatus ##2G## -  - CF_Gway_TurnSigLh,C_TSigLhAct";
CM_ SG_ 1043 ExtLamp_TrnSigLmpRtBlnkngSta "ExtLamp_TurnSignalLampRightBlinkingStatus ##2G## -  - CF_Gway_TurnSigRh,C_TSigRhAct";
CM_ SG_ 1043 ExtLamp_ExtrnlTailLmpSta "ExtLamp_ExternalTailLampStatus ##2G## -  - C_ExtTailAct,CF_Gway_ExtTailAct";
CM_ SG_ 1043 ExtLamp_HzrdSwSta "ExtLamp_HazardSwitchStatus ##2G## -  - C_HazardSw,CF_Gway_HazardSw";
CM_ BO_ 1044 "[PE] Periodic and On Event";
CM_ SG_ 1044 C_CrashUnlockState "Crash Unlock Active State";
CM_ BO_ 1050 "[PE] Periodic and On Event";
CM_ SG_ 1050 BCM_Crc7Val "BCM_CyclicRedundancyCheck7Value";
CM_ SG_ 1050 BCM_AlvCnt7Val "BCM_AliveCounter7Value";
CM_ SG_ 1050 Lamp_ExtrnlTailLmpOnReq "Lamp_ExternalTailLampOnRequest ##2G##BCM - BCMmsg19 - C_ExtTailOn";
CM_ SG_ 1050 Lamp_HdLmpLoOnReq "Lamp_HeadLampLowOnRequest ##2G##BCM - BCMmsg19 - C_HLpLowOn";
CM_ SG_ 1050 Lamp_HdLmpHiOnReq "Lamp_HeadLampHighOnRequest ##2G##BCM - BCMmsg19 - C_HLpHighOn";
CM_ SG_ 1050 Lamp_PassingLmpOnReq "Lamp_PassingLampOnRequest ##2G##BCM - BCMmsg19 - C_PassingLpOn";
CM_ BO_ 1051 "[PE] Periodic and On Event";
CM_ SG_ 1051 BCM_Crc8Val "BCM_CyclicRedundancyCheck8Value";
CM_ SG_ 1051 BCM_AlvCnt8Val "BCM_AliveCounter8Value";
CM_ SG_ 1051 Lamp_HbaCtrlModTyp "Lamp_HbaControlModeType ##2G##BCM - BCMmsg22 - C_HBAControlMode";
CM_ BO_ 1052 "[PE] Periodic and On Event";
CM_ SG_ 1052 Lamp_AutoLtSnsrNightSta "Lamp_AutoLightSensorNightStatus ##2G##BCM - BCMmsg24 - C_AutolightValue";
CM_ BO_ 1057 "[PE] Periodic and On Event";
CM_ SG_ 1057 ILCU_LH_Crc1Val "ILCU_LH_CyclicRedundancyCheck1Value";
CM_ SG_ 1057 ILCU_LH_AlvCnt1Val "ILCU_LH_AliveCounter1Value";
CM_ SG_ 1057 ILCULH_LowBeamAct_Sta "LH Lowbeam activation feedback";
CM_ SG_ 1057 ILCULH_HighBeamAct_Sta "LH Highbeam activation feedback";
CM_ SG_ 1057 ILCULH_FrontTurnAct_Sta "LH Front turn tell-tale";
CM_ SG_ 1057 ILCULH_IFSLamp_Act "LH IFS activation status feedback";
CM_ BO_ 1058 "[PE] Periodic and On Event";
CM_ SG_ 1058 Wiper_PrkngPosSta "Wiper_ParkingPositionStatus ##2G##BCM - BCMmsg22 - C_WiperParkPosition";
CM_ SG_ 1058 Wiper_RainSnsrSta "Wiper_RainSensorStatus ##2G##BCM - BCMmsg24 - C_RainSnsState";
CM_ BO_ 1062 "[PE] Periodic and On Event";
CM_ SG_ 1062 ILCU_RH_Crc1Val "ILCU_RH_CyclicRedundancyCheck1Value";
CM_ SG_ 1062 ILCU_RH_AlvCnt1Val "ILCU_RH_AliveCounter1Value";
CM_ SG_ 1062 ILCURH_LowBeamAct_Sta "RH Lowbeam activation feedback";
CM_ SG_ 1062 ILCURH_HighBeamAct_Sta "RH Highbeam activation feedback";
CM_ SG_ 1062 ILCURH_FrontTurnAct_Sta "RH Front turn tell-tale";
CM_ SG_ 1062 ILCURH_IFSLamp_Act "RH IFS activation status feedback";
CM_ BO_ 1076 "[PE] Periodic and On Event";
CM_ SG_ 1076 IAU_ProfileIDRVal "This signal Indicate the Current detected Profile ID by IAU.";
CM_ BO_ 1092 "[PE] Periodic and On Event";
CM_ SG_ 1092 SMK_Crc2Val "SMK_CyclicRedundancyCheck2Value";
CM_ SG_ 1092 SMK_AlvCnt2Val "SMK_AliveCounter2Value";
CM_ SG_ 1092 SMK_TlEngRunSta "SMK_TeleEngineRunStatus ##2G##SMK - SMKmsg18 - C_SMKTeleEngineRunning";
CM_ BO_ 1097 "[PE] Periodic and On Event";
CM_ SG_ 1097 Lamp_ExtrnlTailLmpSta_BCM "Lamp_ExternalTailLampStatus ##2G##BCM - BCMmsg20 - C_ExtTailAct";
CM_ SG_ 1097 Lamp_HzrdSwSta_BCM "Lamp_HazardSwitchStatus ##2G##BCM - BCMmsg20 - C_HazardSw";
CM_ BO_ 1098 "[PE] Periodic and On Event";
CM_ SG_ 1098 Lamp_HdLmpHiSta_BCM "Lamp_HeadLampHighStatus ##2G##BCM - BCMmsg20 - C_HLpHighAct";
CM_ SG_ 1098 Lamp_HdLmpLoSta_BCM "Lamp_HeadLampLowStatus ##2G##BCM - BCMmsg20 - C_HLpLowAct";
CM_ SG_ 1098 Lamp_FrFgLmpSta_BCM "Lamp_FrontFogLampStatus ##2G##BCM - BCMmsg20 - C_FrtFogAct";
CM_ BO_ 1135 "[EC] Periodic and On Event";
CM_ SG_ 1135 CLU_Crc13Val "CLU_CyclicRedundancyCheck13Value";
CM_ SG_ 1135 CLU_AlvCnt13Val "CLU_AliveCounter13Value";
CM_ SG_ 1135 USM_AdasLkaModSetReq "USM_AdasLkaModSetRequest";
CM_ SG_ 1135 USM_AdasFCAJnctnSetReq "USM_AdasFCAJnctnSetReq";
CM_ SG_ 1135 USM_AdasHbaSetReq "USM_AdasHbaSetReq";
CM_ SG_ 1135 USM_AdasSCCMLSetReq "USM_AdasSCCMLSetReq";
CM_ SG_ 1135 USM_AdasSCCMLResetReq "USM_AdasSCCMLResetReq";
CM_ BO_ 1145 "[EC] Periodic and On Event";
CM_ SG_ 1145 CLU_Crc12Val "CLU_CyclicRedundancyCheck12Value";
CM_ SG_ 1145 CLU_AlvCnt12Val "CLU_AliveCounter12Value";
CM_ SG_ 1145 USM_AdasUSMResetReq "USM_AdasUSMResetRequest";
CM_ SG_ 1145 USM_AdasFCASetReq "USM_AdasFCASetRequest";
CM_ SG_ 1145 USM_AdasSCCDrvModSetReq "USM_AdasSCCDrivingModeSetRequest";
CM_ SG_ 1145 USM_AdasDAWModSetReq "USM_AdasDAWModeSetRequest";
CM_ SG_ 1145 USM_AdasHDASetReq "USM_AdasHDASetRequest";
CM_ SG_ 1145 USM_AdasNSCCCamSetReq "USM_AdasNSCCCamSetRequest";
CM_ SG_ 1145 USM_AdasLFASetReq "USM_AdasLFASetRequest";
CM_ SG_ 1145 USM_AdasBCASetReq "USM_AdasBCASetRequest";
CM_ SG_ 1145 USM_AdasISLWSetReq "USM_AdasISLWSetRequest";
CM_ SG_ 1145 USM_AdasWrngTimingSetReq "USM_AdasWarningTimingSetRequest";
CM_ SG_ 1145 USM_AdasLVDASetReq "USM_AdasLVDASetRequest";
CM_ SG_ 1145 USM_AdasNSCCCrvSetReq "USM_AdasNSCCCrvSetRequest";
BA_DEF_ BO_  "GenMsgILSupport" ENUM  "No","Yes";
BA_DEF_ BO_  "DiagState" ENUM  "No","Yes";
BA_DEF_ BO_  "DiagResponse" ENUM  "No","Yes";
BA_DEF_ BO_  "DiagRequest" ENUM  "No","Yes";
BA_DEF_ BO_  "VFrameFormat" ENUM  "StandardCAN","ExtendedCAN","reserved","reserved","reserved","reserved","reserved","reserved","reserved","reserved","reserved","reserved","reserved","reserved","StandardCAN_FD","ExtendedCAN_FD";
BA_DEF_ BO_  "GenMsgSendType" ENUM  "Cyclic","NoMsgSendType";
BA_DEF_ SG_  "UserSigValidity" ENUM  "B+","ACC","IG","IG1","IG2","IG3","IG1 or IG2","IG1 or IG3","Undef";
BA_DEF_ SG_  "RoutingFactor" INT 1 1215752192;
BA_DEF_ SG_  "NetworkRequestHoldingTime" INT 0 65535;
BA_DEF_ SG_  "Description" STRING ;
BA_DEF_ SG_  "Version" STRING ;
BA_DEF_ BO_  "GenMsgCycleTime" INT 0 2000;
BA_DEF_ BO_  "GenMsgStartDelayTime" INT 0 2000;
BA_DEF_ SG_  "UsrSigPurpose" ENUM  "Undef","FN","DIAG","DEV","NM";
BA_DEF_ SG_  "GenSigStartValue" INT 0 0;
BA_DEF_DEF_  "GenMsgILSupport" "Yes";
BA_DEF_DEF_  "DiagState" "No";
BA_DEF_DEF_  "DiagResponse" "No";
BA_DEF_DEF_  "DiagRequest" "No";
BA_DEF_DEF_  "VFrameFormat" "";
BA_DEF_DEF_  "GenMsgSendType" "NoMsgSendType";
BA_DEF_DEF_  "UserSigValidity" "IG";
BA_DEF_DEF_  "RoutingFactor" 1;
BA_DEF_DEF_  "NetworkRequestHoldingTime" 0;
BA_DEF_DEF_  "Description" "";
BA_DEF_DEF_  "Version" "";
BA_DEF_DEF_  "GenMsgCycleTime" 0;
BA_DEF_DEF_  "GenMsgStartDelayTime" 0;
BA_DEF_DEF_  "UsrSigPurpose" "FN";
BA_DEF_DEF_  "GenSigStartValue" 0;
BA_ "GenMsgCycleTime" BO_ 388 30;
BA_ "GenMsgSendType" BO_ 388 0;
BA_ "VFrameFormat" BO_ 388 14;
BA_ "GenMsgCycleTime" BO_ 389 30;
BA_ "GenMsgSendType" BO_ 389 0;
BA_ "VFrameFormat" BO_ 389 14;
BA_ "GenMsgCycleTime" BO_ 416 20;
BA_ "GenMsgSendType" BO_ 416 0;
BA_ "VFrameFormat" BO_ 416 14;
BA_ "GenMsgCycleTime" BO_ 426 20;
BA_ "GenMsgSendType" BO_ 426 0;
BA_ "VFrameFormat" BO_ 426 14;
BA_ "GenMsgCycleTime" BO_ 437 50;
BA_ "GenMsgSendType" BO_ 437 0;
BA_ "VFrameFormat" BO_ 437 14;
BA_ "GenMsgCycleTime" BO_ 442 50;
BA_ "GenMsgSendType" BO_ 442 0;
BA_ "VFrameFormat" BO_ 442 14;
BA_ "GenMsgCycleTime" BO_ 463 20;
BA_ "GenMsgSendType" BO_ 463 0;
BA_ "VFrameFormat" BO_ 463 0;
BA_ "GenMsgCycleTime" BO_ 480 50;
BA_ "GenMsgSendType" BO_ 480 0;
BA_ "VFrameFormat" BO_ 480 14;
BA_ "GenMsgCycleTime" BO_ 506 100;
BA_ "GenMsgSendType" BO_ 506 0;
BA_ "VFrameFormat" BO_ 506 14;
BA_ "GenMsgCycleTime" BO_ 549 100;
BA_ "GenMsgSendType" BO_ 549 0;
BA_ "VFrameFormat" BO_ 549 14;
BA_ "GenMsgCycleTime" BO_ 560 100;
BA_ "GenMsgSendType" BO_ 560 0;
BA_ "VFrameFormat" BO_ 560 14;
BA_ "GenMsgCycleTime" BO_ 608 100;
BA_ "GenMsgSendType" BO_ 608 0;
BA_ "VFrameFormat" BO_ 608 14;
BA_ "GenMsgCycleTime" BO_ 613 100;
BA_ "GenMsgSendType" BO_ 613 0;
BA_ "VFrameFormat" BO_ 613 14;
BA_ "GenMsgCycleTime" BO_ 661 100;
BA_ "GenMsgSendType" BO_ 661 0;
BA_ "VFrameFormat" BO_ 661 14;
BA_ "GenMsgCycleTime" BO_ 674 50;
BA_ "GenMsgSendType" BO_ 674 0;
BA_ "VFrameFormat" BO_ 674 14;
BA_ "GenMsgCycleTime" BO_ 675 50;
BA_ "GenMsgSendType" BO_ 675 0;
BA_ "VFrameFormat" BO_ 675 14;
BA_ "GenMsgCycleTime" BO_ 676 50;
BA_ "GenMsgSendType" BO_ 676 0;
BA_ "VFrameFormat" BO_ 676 14;
BA_ "VFrameFormat" BO_ 698 14;
BA_ "GenMsgCycleTime" BO_ 720 100;
BA_ "GenMsgSendType" BO_ 720 0;
BA_ "VFrameFormat" BO_ 720 14;
BA_ "GenMsgCycleTime" BO_ 832 100;
BA_ "GenMsgSendType" BO_ 832 0;
BA_ "VFrameFormat" BO_ 832 14;
BA_ "GenMsgCycleTime" BO_ 934 200;
BA_ "GenMsgSendType" BO_ 934 0;
BA_ "VFrameFormat" BO_ 934 0;
BA_ "GenMsgCycleTime" BO_ 961 200;
BA_ "GenMsgSendType" BO_ 961 0;
BA_ "VFrameFormat" BO_ 961 0;
BA_ "GenMsgCycleTime" BO_ 962 200;
BA_ "GenMsgSendType" BO_ 962 0;
BA_ "VFrameFormat" BO_ 962 0;
BA_ "GenMsgCycleTime" BO_ 1035 200;
BA_ "GenMsgSendType" BO_ 1035 0;
BA_ "VFrameFormat" BO_ 1035 0;
BA_ "GenMsgCycleTime" BO_ 1041 200;
BA_ "GenMsgSendType" BO_ 1041 0;
BA_ "VFrameFormat" BO_ 1041 0;
BA_ "GenMsgCycleTime" BO_ 1043 200;
BA_ "GenMsgSendType" BO_ 1043 0;
BA_ "VFrameFormat" BO_ 1043 0;
BA_ "GenMsgCycleTime" BO_ 1044 200;
BA_ "GenMsgSendType" BO_ 1044 0;
BA_ "VFrameFormat" BO_ 1044 0;
BA_ "GenMsgCycleTime" BO_ 1050 200;
BA_ "GenMsgSendType" BO_ 1050 0;
BA_ "VFrameFormat" BO_ 1050 0;
BA_ "GenMsgCycleTime" BO_ 1051 200;
BA_ "GenMsgSendType" BO_ 1051 0;
BA_ "VFrameFormat" BO_ 1051 0;
BA_ "GenMsgCycleTime" BO_ 1052 200;
BA_ "GenMsgSendType" BO_ 1052 0;
BA_ "VFrameFormat" BO_ 1052 0;
BA_ "GenMsgCycleTime" BO_ 1057 200;
BA_ "GenMsgSendType" BO_ 1057 0;
BA_ "VFrameFormat" BO_ 1057 0;
BA_ "GenMsgCycleTime" BO_ 1058 200;
BA_ "GenMsgSendType" BO_ 1058 0;
BA_ "VFrameFormat" BO_ 1058 0;
BA_ "GenMsgCycleTime" BO_ 1062 200;
BA_ "GenMsgSendType" BO_ 1062 0;
BA_ "VFrameFormat" BO_ 1062 0;
BA_ "GenMsgCycleTime" BO_ 1076 200;
BA_ "GenMsgSendType" BO_ 1076 0;
BA_ "VFrameFormat" BO_ 1076 0;
BA_ "GenMsgCycleTime" BO_ 1092 200;
BA_ "GenMsgSendType" BO_ 1092 0;
BA_ "VFrameFormat" BO_ 1092 0;
BA_ "GenMsgCycleTime" BO_ 1097 200;
BA_ "GenMsgSendType" BO_ 1097 0;
BA_ "VFrameFormat" BO_ 1097 0;
BA_ "GenMsgCycleTime" BO_ 1098 200;
BA_ "GenMsgSendType" BO_ 1098 0;
BA_ "VFrameFormat" BO_ 1098 0;
BA_ "GenMsgSendType" BO_ 1135 0;
BA_ "VFrameFormat" BO_ 1135 14;
BA_ "GenMsgSendType" BO_ 1145 0;
BA_ "VFrameFormat" BO_ 1145 14;
BA_ "UserSigValidity" SG_ 388 FR_CMR_Obj_Crc05Val 3;
BA_ "GenSigStartValue" SG_ 388 FR_CMR_Obj_Crc05Val 65535;
BA_ "Description" SG_ 388 FR_CMR_Obj_Crc05Val "[Cyclic redundancy check] The CRC checking process calculates the CRC over the entire data block, including the CRC result CRC Polynomial (0x1021) ,

Initial Value : 0xFFFF, XOR value : 0x0000

The mathematical expression to 16 bit CRC polynomial is give";
BA_ "Version" SG_ 388 FR_CMR_Obj_Crc05Val "18.03.01";
BA_ "UserSigValidity" SG_ 388 FR_CMR_Obj_AlvCnt05Val 3;
BA_ "Description" SG_ 388 FR_CMR_Obj_AlvCnt05Val "[Alive counter] For the first transmission request for a data element the counter shall be initialized with 0 and shall be incremented by 1

for every subsequent send request. When the counter reaches the maximum value(0xFF), then it shall restart with �";
BA_ "Version" SG_ 388 FR_CMR_Obj_AlvCnt05Val "18.03.01";
BA_ "UserSigValidity" SG_ 388 FR_CMR_Obj_QualLvl09Sta 3;
BA_ "Description" SG_ 388 FR_CMR_Obj_QualLvl09Sta "[Quality level] Information quality for a target object. Information quality can be interpreted by reliability, validity, probability etc.  

Value range : 0~100 (0~30 : Low, 30~60 : Medium, 60~100 : High)";
BA_ "Version" SG_ 388 FR_CMR_Obj_QualLvl09Sta "18.03.01";
BA_ "UserSigValidity" SG_ 388 FR_CMR_Obj_AlvAge09Val 3;
BA_ "Description" SG_ 388 FR_CMR_Obj_AlvAge09Val "[Alive Age] Lifetime

(Keep the higher values than 255 as 255.)";
BA_ "Version" SG_ 388 FR_CMR_Obj_AlvAge09Val "18.03.01";
BA_ "UserSigValidity" SG_ 388 FR_CMR_Obj_MvngFlag09Sta 3;
BA_ "Description" SG_ 388 FR_CMR_Obj_MvngFlag09Sta "[Moving flag] Moving information for a forward or oncoming object (ex. preceding vehicle, oncoming vehicle) : Stationary, Movable (Moving, Stopped) etc.";
BA_ "Version" SG_ 388 FR_CMR_Obj_MvngFlag09Sta "18.03.01";
BA_ "UserSigValidity" SG_ 388 FR_CMR_Obj_Id09Val 3;
BA_ "Description" SG_ 388 FR_CMR_Obj_Id09Val "[Track ID] Unlike radar (including corner radar), extra 'Track ID' signal is required because camera automatically sorts messages according to distance between subject and track vehicle. (1-127 valid and 0 is always invalid)";
BA_ "Version" SG_ 388 FR_CMR_Obj_Id09Val "18.03.01";
BA_ "UserSigValidity" SG_ 388 FR_CMR_Obj_Wth09Val 3;
BA_ "Description" SG_ 388 FR_CMR_Obj_Wth09Val "[Object width] Target object width. ";
BA_ "Version" SG_ 388 FR_CMR_Obj_Wth09Val "18.03.01";
BA_ "UserSigValidity" SG_ 388 FR_CMR_Obj_Clfct09Sta 3;
BA_ "Description" SG_ 388 FR_CMR_Obj_Clfct09Sta "[Object classification] Object classification result. 

Passenger car, Motor bike, truck, bicycle, pedestrian, etc. ";
BA_ "Version" SG_ 388 FR_CMR_Obj_Clfct09Sta "18.03.01";
BA_ "UserSigValidity" SG_ 388 FR_CMR_Obj_RelPosX09Val 3;
BA_ "GenSigStartValue" SG_ 388 FR_CMR_Obj_RelPosX09Val 7000;
BA_ "Description" SG_ 388 FR_CMR_Obj_RelPosX09Val "[Longitudinal distance] Physical distance between the subject vehicle and a target object in the x-axis of vehicle fixed coordinate system (ISO).

Reference point of the subject vehicle : the center of front bumper

Reference point of a target object : t";
BA_ "Version" SG_ 388 FR_CMR_Obj_RelPosX09Val "18.03.01";
BA_ "UserSigValidity" SG_ 388 FR_CMR_Obj_RelPosY09Val 3;
BA_ "Description" SG_ 388 FR_CMR_Obj_RelPosY09Val "[Lateral distance] Physical distance between the subject and a target object in the y-axis of vehicle fixed coordinate system (ISO). 

Reference point of the subject vehicle : centerline of the subject vehicle (x-axis of vehicle fixed coordinate system)

";
BA_ "Version" SG_ 388 FR_CMR_Obj_RelPosY09Val "18.03.01";
BA_ "UserSigValidity" SG_ 388 FR_CMR_Obj_RelVelX09Val 3;
BA_ "GenSigStartValue" SG_ 388 FR_CMR_Obj_RelVelX09Val 2000;
BA_ "Description" SG_ 388 FR_CMR_Obj_RelVelX09Val "[Longitudinal velocity] Relative velocity between the subject vehicle and a target object. 

Positive velocity : A forward object moves away from the subject vehicle, or a following object approaches the subject vehicle.";
BA_ "Version" SG_ 388 FR_CMR_Obj_RelVelX09Val "18.03.01";
BA_ "UserSigValidity" SG_ 388 FR_CMR_Obj_RelVelY09Val 3;
BA_ "GenSigStartValue" SG_ 388 FR_CMR_Obj_RelVelY09Val 500;
BA_ "Description" SG_ 388 FR_CMR_Obj_RelVelY09Val "[Lateral velocity] Relative velocity between the subject vehicle and target object. 

Positive velocity : A target object on the left side of the subject vehicle moves away from subject vehicle, or a target object on the right side of the subject vehicle";
BA_ "Version" SG_ 388 FR_CMR_Obj_RelVelY09Val "18.03.01";
BA_ "UserSigValidity" SG_ 388 FR_CMR_Obj_RelAccelX09Val 3;
BA_ "Description" SG_ 388 FR_CMR_Obj_RelAccelX09Val "[Longitudinal acceleration] Relative acceleration between the subject and target vehicle. 

Positive acceleration : a target object moves away from the subject vehicle, or a following object approaches the subject vehicle.";
BA_ "Version" SG_ 388 FR_CMR_Obj_RelAccelX09Val "18.03.01";
BA_ "UserSigValidity" SG_ 388 FR_CMR_Obj_QualLvl10Sta 3;
BA_ "Description" SG_ 388 FR_CMR_Obj_QualLvl10Sta "[Quality level] Information quality for a target object. Information quality can be interpreted by reliability, validity, probability etc.  

Value range : 0~100 (0~30 : Low, 30~60 : Medium, 60~100 : High)";
BA_ "Version" SG_ 388 FR_CMR_Obj_QualLvl10Sta "18.03.01";
BA_ "UserSigValidity" SG_ 388 FR_CMR_Obj_AlvAge10Val 3;
BA_ "Description" SG_ 388 FR_CMR_Obj_AlvAge10Val "[Alive Age] Lifetime

(Keep the higher values than 255 as 255.)";
BA_ "Version" SG_ 388 FR_CMR_Obj_AlvAge10Val "18.03.01";
BA_ "UserSigValidity" SG_ 388 FR_CMR_Obj_MvngFlag10Sta 3;
BA_ "Description" SG_ 388 FR_CMR_Obj_MvngFlag10Sta "[Moving flag] Moving information for a forward or oncoming object (ex. preceding vehicle, oncoming vehicle) : Stationary, Movable (Moving, Stopped) etc.";
BA_ "Version" SG_ 388 FR_CMR_Obj_MvngFlag10Sta "18.03.01";
BA_ "UserSigValidity" SG_ 388 FR_CMR_Obj_Id10Val 3;
BA_ "Description" SG_ 388 FR_CMR_Obj_Id10Val "[Track ID] Unlike radar (including corner radar), extra 'Track ID' signal is required because camera automatically sorts messages according to distance between subject and track vehicle. (1-127 valid and 0 is always invalid)";
BA_ "Version" SG_ 388 FR_CMR_Obj_Id10Val "18.03.01";
BA_ "UserSigValidity" SG_ 388 FR_CMR_Obj_Wth10Val 3;
BA_ "Description" SG_ 388 FR_CMR_Obj_Wth10Val "[Object width] Target object width. ";
BA_ "Version" SG_ 388 FR_CMR_Obj_Wth10Val "18.03.01";
BA_ "UserSigValidity" SG_ 388 FR_CMR_Obj_Clfct10Sta 3;
BA_ "Description" SG_ 388 FR_CMR_Obj_Clfct10Sta "[Object classification] Object classification result. 

Passenger car, Motor bike, truck, bicycle, pedestrian, etc. ";
BA_ "Version" SG_ 388 FR_CMR_Obj_Clfct10Sta "18.03.01";
BA_ "UserSigValidity" SG_ 388 FR_CMR_Obj_RelPosX10Val 3;
BA_ "GenSigStartValue" SG_ 388 FR_CMR_Obj_RelPosX10Val 7000;
BA_ "Description" SG_ 388 FR_CMR_Obj_RelPosX10Val "[Longitudinal distance] Physical distance between the subject vehicle and a target object in the x-axis of vehicle fixed coordinate system (ISO).

Reference point of the subject vehicle : the center of front bumper

Reference point of a target object : t";
BA_ "Version" SG_ 388 FR_CMR_Obj_RelPosX10Val "18.03.01";
BA_ "UserSigValidity" SG_ 388 FR_CMR_Obj_RelPosY10Val 3;
BA_ "Description" SG_ 388 FR_CMR_Obj_RelPosY10Val "[Lateral distance] Physical distance between the subject and a target object in the y-axis of vehicle fixed coordinate system (ISO). 

Reference point of the subject vehicle : centerline of the subject vehicle (x-axis of vehicle fixed coordinate system)

";
BA_ "Version" SG_ 388 FR_CMR_Obj_RelPosY10Val "18.03.01";
BA_ "UserSigValidity" SG_ 388 FR_CMR_Obj_RelVelX10Val 3;
BA_ "GenSigStartValue" SG_ 388 FR_CMR_Obj_RelVelX10Val 2000;
BA_ "Description" SG_ 388 FR_CMR_Obj_RelVelX10Val "[Longitudinal velocity] Relative velocity between the subject vehicle and a target object. 

Positive velocity : A forward object moves away from the subject vehicle, or a following object approaches the subject vehicle.";
BA_ "Version" SG_ 388 FR_CMR_Obj_RelVelX10Val "18.03.01";
BA_ "UserSigValidity" SG_ 388 FR_CMR_Obj_RelVelY10Val 3;
BA_ "GenSigStartValue" SG_ 388 FR_CMR_Obj_RelVelY10Val 500;
BA_ "Description" SG_ 388 FR_CMR_Obj_RelVelY10Val "[Lateral velocity] Relative velocity between the subject vehicle and target object. 

Positive velocity : A target object on the left side of the subject vehicle moves away from subject vehicle, or a target object on the right side of the subject vehicle";
BA_ "Version" SG_ 388 FR_CMR_Obj_RelVelY10Val "18.03.01";
BA_ "UserSigValidity" SG_ 388 FR_CMR_Obj_RelAccelX10Val 3;
BA_ "Description" SG_ 388 FR_CMR_Obj_RelAccelX10Val "[Longitudinal acceleration] Relative acceleration between the subject and target vehicle. 

Positive acceleration : a target object moves away from the subject vehicle, or a following object approaches the subject vehicle.";
BA_ "Version" SG_ 388 FR_CMR_Obj_RelAccelX10Val "18.03.01";
BA_ "UserSigValidity" SG_ 389 FR_CMR_Genrl_Crc01Val 3;
BA_ "GenSigStartValue" SG_ 389 FR_CMR_Genrl_Crc01Val 65535;
BA_ "Description" SG_ 389 FR_CMR_Genrl_Crc01Val "The CRC checking process calculates the CRC over the entire data block, including the CRC result CRC Polynomial (0x1021) ,

Initial Value : 0xFFFF, XOR value : 0x0000

The mathematical expression to 16 bit CRC polynomial is given here. G(x) = x16 + x12 +";
BA_ "Version" SG_ 389 FR_CMR_Genrl_Crc01Val "18.03.01";
BA_ "UserSigValidity" SG_ 389 FR_CMR_Genrl_AlvCnt01Val 3;
BA_ "Description" SG_ 389 FR_CMR_Genrl_AlvCnt01Val "For the first transmission request for a data element the counter shall be initialized with 0 and shall be incremented by 1

for every subsequent send request. When the counter reaches the maximum value(0xFF), then it shall restart with – for the next ";
BA_ "Version" SG_ 389 FR_CMR_Genrl_AlvCnt01Val "18.03.01";
BA_ "UserSigValidity" SG_ 389 FR_CMR_Genrl_DetObjNumVal 3;
BA_ "Description" SG_ 389 FR_CMR_Genrl_DetObjNumVal "Total number of detected objects";
BA_ "Version" SG_ 389 FR_CMR_Genrl_DetObjNumVal "18.03.01";
BA_ "UserSigValidity" SG_ 389 FR_CMR_Genrl_DetLnNumVal 3;
BA_ "Description" SG_ 389 FR_CMR_Genrl_DetLnNumVal "Total number of detected Lines";
BA_ "Version" SG_ 389 FR_CMR_Genrl_DetLnNumVal "18.03.01";
BA_ "UserSigValidity" SG_ 389 FR_CMR_Genrl_FlInfoSta 3;
BA_ "Description" SG_ 389 FR_CMR_Genrl_FlInfoSta "Fail information, Status";
BA_ "Version" SG_ 389 FR_CMR_Genrl_FlInfoSta "18.03.01";
BA_ "UserSigValidity" SG_ 389 FR_CMR_Genrl_SnsrLatencyVal 3;
BA_ "Description" SG_ 389 FR_CMR_Genrl_SnsrLatencyVal "Sensor latency time";
BA_ "Version" SG_ 389 FR_CMR_Genrl_SnsrLatencyVal "18.03.01";
BA_ "UserSigValidity" SG_ 389 FR_CMR_Genrl_DayTimeIndicatorSta 3;
BA_ "Description" SG_ 389 FR_CMR_Genrl_DayTimeIndicatorSta "DayTimeIndicator";
BA_ "Version" SG_ 389 FR_CMR_Genrl_DayTimeIndicatorSta "18.03.01";
BA_ "UserSigValidity" SG_ 416 ADAS_CMD_Crc20Val 3;
BA_ "GenSigStartValue" SG_ 416 ADAS_CMD_Crc20Val 65535;
BA_ "RoutingFactor" SG_ 416 ADAS_CMD_Crc20Val 5;
BA_ "Description" SG_ 416 ADAS_CMD_Crc20Val "The CRC checking process calculates the CRC over the entire data block, including the CRC result.

- CRC Polynomial (0x1021) , Initial Value : 0xFFFF, XOR value : 0x0000

- The mathematical expression to 16 bit CRC polynomial is given here. G(x) = x16 + ";
BA_ "Version" SG_ 416 ADAS_CMD_Crc20Val "17.12.00";
BA_ "UserSigValidity" SG_ 416 ADAS_CMD_AlvCnt20Val 3;
BA_ "RoutingFactor" SG_ 416 ADAS_CMD_AlvCnt20Val 5;
BA_ "Description" SG_ 416 ADAS_CMD_AlvCnt20Val "For the first transmission request for a data element the counter shall be initialized with 0 and shall be incremented by 1

for every subsequent send request. When the counter reaches the maximum value(0xFF), then it shall restart with – for the next ";
BA_ "Version" SG_ 416 ADAS_CMD_AlvCnt20Val "17.12.00";
BA_ "UserSigValidity" SG_ 416 SCC_ObjDstVal 3;
BA_ "GenSigStartValue" SG_ 416 SCC_ObjDstVal 2047;
BA_ "RoutingFactor" SG_ 416 SCC_ObjDstVal 5;
BA_ "Description" SG_ 416 SCC_ObjDstVal "This signal provides the distance to the in lane detected SCC object regarding to the own vehicle.

- 자차선상의 전방 인식된 물체와의 거리";
BA_ "Version" SG_ 416 SCC_ObjDstVal "18.01.07";
BA_ "UserSigValidity" SG_ 416 SCC_ObjRelSpdVal 3;
BA_ "GenSigStartValue" SG_ 416 SCC_ObjRelSpdVal 4095;
BA_ "RoutingFactor" SG_ 416 SCC_ObjRelSpdVal 5;
BA_ "Description" SG_ 416 SCC_ObjRelSpdVal "This signal provides the relative speed to the in lane detected SCC object regarding to the own vehicle.

- 자차선상의 전방 인식된 물체와 자차간 상대 속도";
BA_ "Version" SG_ 416 SCC_ObjRelSpdVal "18.01.07";
BA_ "UserSigValidity" SG_ 416 SCC_ObjLatPosVal 3;
BA_ "GenSigStartValue" SG_ 416 SCC_ObjLatPosVal 511;
BA_ "RoutingFactor" SG_ 416 SCC_ObjLatPosVal 5;
BA_ "Description" SG_ 416 SCC_ObjLatPosVal "This signal provides the lateral position of the detected SCC object regarding to the own vehicle. 

The position of the SCC object on the left side in driving direction of the vehicle longitudinal axis correlates with a negative signal value. 

Thus an ";
BA_ "Version" SG_ 416 SCC_ObjLatPosVal "18.01.07";
BA_ "UserSigValidity" SG_ 416 SCC_SysFlrSta 3;
BA_ "RoutingFactor" SG_ 416 SCC_SysFlrSta 5;
BA_ "Description" SG_ 416 SCC_SysFlrSta "This signal is evaluated by the driver information device to release the failure information to the driver.

If this signal is set to anything other than 0, the TCS/ESC shall ignore any requests from SCC

- 시스템 고장 발생 정보용

- 해당 값";
BA_ "Version" SG_ 416 SCC_SysFlrSta "17.12.00";
BA_ "UserSigValidity" SG_ 416 SCC_MainOnOffSta 3;
BA_ "RoutingFactor" SG_ 416 SCC_MainOnOffSta 5;
BA_ "Description" SG_ 416 SCC_MainOnOffSta "This signal specifies the status of a Main switch of SCC system

- Main swith 에 의한 SCC ON/OFF 상태 정보";
BA_ "Version" SG_ 416 SCC_MainOnOffSta "17.12.00";
BA_ "UserSigValidity" SG_ 416 SCC_OpSta 3;
BA_ "RoutingFactor" SG_ 416 SCC_OpSta 5;
BA_ "Description" SG_ 416 SCC_OpSta "The signal ACCmode specifies the operational mode of SCC

- ACC 작동 상태 정보(off&ready / active / override / shut off)";
BA_ "Version" SG_ 416 SCC_OpSta "17.12.00";
BA_ "UserSigValidity" SG_ 416 SCC_TakeoverReq 3;
BA_ "RoutingFactor" SG_ 416 SCC_TakeoverReq 5;
BA_ "Description" SG_ 416 SCC_TakeoverReq "The Take-over Request supports the driver to identify the limits of the SCC control. Reasons for such a request may be:

- Deceleration capability insufficient for the current situation.

Clutch actuation by the driver is necessary to avoid stopping of t";
BA_ "Version" SG_ 416 SCC_TakeoverReq "17.12.00";
BA_ "UserSigValidity" SG_ 416 SCC_InfoDis 3;
BA_ "RoutingFactor" SG_ 416 SCC_InfoDis 5;
BA_ "Description" SG_ 416 SCC_InfoDis "This signal carries information that indicates below 4 signals.

(1) SCC Mode display

(2) CC Mode display

(3) Object disapearing display

(4) Go notifying display

- SCC 제어 상세 상태를 보여주는 정보 신호

(SCC 모드 / CC 모드 / 전�";
BA_ "Version" SG_ 416 SCC_InfoDis "17.12.00";
BA_ "UserSigValidity" SG_ 416 SCC_DrvAlrtDis 3;
BA_ "RoutingFactor" SG_ 416 SCC_DrvAlrtDis 5;
BA_ "Description" SG_ 416 SCC_DrvAlrtDis "This signal carries the information which message shall be displayed to the driver 

when the SCC must be disengaged by the system or cann’t be engaged.

A signal value unequal 00H is repeated for 5 messages cycles in order to ensure it appears for at ";
BA_ "Version" SG_ 416 SCC_DrvAlrtDis "17.12.00";
BA_ "UserSigValidity" SG_ 416 SCC_ObjDstLvlVal 3;
BA_ "RoutingFactor" SG_ 416 SCC_ObjDstLvlVal 5;
BA_ "Description" SG_ 416 SCC_ObjDstLvlVal "If a in-path object is recognized by SCC, the driver should be informed.

- 자차선상의 전방 물체 인식 여부 정보";
BA_ "Version" SG_ 416 SCC_ObjDstLvlVal "17.12.00";
BA_ "UserSigValidity" SG_ 416 SCC_HeadwayDstSetVal 3;
BA_ "RoutingFactor" SG_ 416 SCC_HeadwayDstSetVal 5;
BA_ "Description" SG_ 416 SCC_HeadwayDstSetVal "The desired time gap from which a following distance is extracted has to be presented to the driver at least if the value changes. 

The representation of the information depends on the display concept.

- 전방 차량과의 거리 setting 정보

※ S";
BA_ "Version" SG_ 416 SCC_HeadwayDstSetVal "17.12.00";
BA_ "UserSigValidity" SG_ 416 SCC_EquipSta 3;
BA_ "RoutingFactor" SG_ 416 SCC_EquipSta 5;
BA_ "Description" SG_ 416 SCC_EquipSta "This signal indicates equipment for SCC

- SCC 장착 사양 정보";
BA_ "Version" SG_ 416 SCC_EquipSta "17.12.00";
BA_ "UserSigValidity" SG_ 416 SCC_TrgtSpdSetVal 3;
BA_ "RoutingFactor" SG_ 416 SCC_TrgtSpdSetVal 5;
BA_ "Description" SG_ 416 SCC_TrgtSpdSetVal "The desired vehicle speed for free cruising has to be displayed all the time SCC is under active control.

※This signal can be sent in km/h or MPH according to the “SPEED_UNIT” signal (See CLU1 message).

SPEED_UNIT = 0 : [km/h], SPEED_UNIT = 1 : [";
BA_ "Version" SG_ 416 SCC_TrgtSpdSetVal "17.12.00";
BA_ "UserSigValidity" SG_ 416 SCC_NSCCOpSta 3;
BA_ "RoutingFactor" SG_ 416 SCC_NSCCOpSta 5;
BA_ "Description" SG_ 416 SCC_NSCCOpSta "This signal describes the operational status of NSCC-Z/C/R function. 



NSCC-Z/C/R  작동 상태 정보(off/ready/active)";
BA_ "Version" SG_ 416 SCC_NSCCOpSta "17.12.00";
BA_ "UserSigValidity" SG_ 416 SCC_NSCCOnOffSta 3;
BA_ "RoutingFactor" SG_ 416 SCC_NSCCOnOffSta 5;
BA_ "Description" SG_ 416 SCC_NSCCOnOffSta "This signal describes the on/off status of NSCC-Z/C/R and HDA Auto-set function. 



NSCC-Z/C/R  and HDA auto-set on/off 상태 정보";
BA_ "Version" SG_ 416 SCC_NSCCOnOffSta "17.12.00";
BA_ "UserSigValidity" SG_ 416 SCC_ObjSta 3;
BA_ "RoutingFactor" SG_ 416 SCC_ObjSta 5;
BA_ "Description" SG_ 416 SCC_ObjSta "This signal represents the state of in-path object and information of controllable state.

- 자차선상의 전방 차량 인식 여부 및 제어 가능 상태 정보";
BA_ "Version" SG_ 416 SCC_ObjSta "18.01.07";
BA_ "UserSigValidity" SG_ 416 SCC_SnstvtyModRetVal 3;
BA_ "GenSigStartValue" SG_ 416 SCC_SnstvtyModRetVal 2;
BA_ "RoutingFactor" SG_ 416 SCC_SnstvtyModRetVal 5;
BA_ "Description" SG_ 416 SCC_SnstvtyModRetVal "This signal is SCC sensitive set mode switch info return value to cluster

- SCC 민감도 설정 관련 USM 설정 스위치 정보의 리턴 값";
BA_ "Version" SG_ 416 SCC_SnstvtyModRetVal "17.12.00";
BA_ "UserSigValidity" SG_ 416 SCC_AccelReqVal 3;
BA_ "RoutingFactor" SG_ 416 SCC_AccelReqVal 5;
BA_ "Description" SG_ 416 SCC_AccelReqVal "This signal represents the SCC acceleration request after jerk limit.

- Jerk limit를 거친 SCC 의 요구 가속도/감속도 값";
BA_ "Version" SG_ 416 SCC_AccelReqVal "17.12.00";
BA_ "UserSigValidity" SG_ 416 SCC_AccelReqRawVal 3;
BA_ "RoutingFactor" SG_ 416 SCC_AccelReqRawVal 5;
BA_ "Description" SG_ 416 SCC_AccelReqRawVal "This signal represents the SCC acceleration request before jerk limit. 

- Jerk limit를 거치지 않은 SCC 의 요구 가속도/감속도 값";
BA_ "Version" SG_ 416 SCC_AccelReqRawVal "17.12.00";
BA_ "UserSigValidity" SG_ 416 SCC_JrkUppLimVal 3;
BA_ "RoutingFactor" SG_ 416 SCC_JrkUppLimVal 5;
BA_ "Description" SG_ 416 SCC_JrkUppLimVal "This signal is the value of positive jerk limit request. 

- SCC 의 요구 가속도 상승변화율 제한 값";
BA_ "Version" SG_ 416 SCC_JrkUppLimVal "17.12.00";
BA_ "UserSigValidity" SG_ 416 SCC_JrkLwrLimVal 3;
BA_ "RoutingFactor" SG_ 416 SCC_JrkLwrLimVal 5;
BA_ "Description" SG_ 416 SCC_JrkLwrLimVal "This signal is the value of negative jerk limit request. 

- SCC 의 요구 가속도 하강변화율 제한 값";
BA_ "Version" SG_ 416 SCC_JrkLwrLimVal "17.12.00";
BA_ "UserSigValidity" SG_ 416 SCC_AccelLimBandUppVal 3;
BA_ "RoutingFactor" SG_ 416 SCC_AccelLimBandUppVal 5;
BA_ "Description" SG_ 416 SCC_AccelLimBandUppVal "This signal is the upper value of acceleration limit band.

- SCC 의 가속도 제어 허용 범위 상한 참고값";
BA_ "Version" SG_ 416 SCC_AccelLimBandUppVal "17.12.03";
BA_ "UserSigValidity" SG_ 416 SCC_AccelLimBandLwrVal 3;
BA_ "RoutingFactor" SG_ 416 SCC_AccelLimBandLwrVal 5;
BA_ "Description" SG_ 416 SCC_AccelLimBandLwrVal "This signal is the lower value of acceleration limit band.

- SCC 의 가속도 제어 허용 범위 하한 참고값";
BA_ "Version" SG_ 416 SCC_AccelLimBandLwrVal "17.12.03";
BA_ "UserSigValidity" SG_ 416 SCC_VehStpReq 3;
BA_ "RoutingFactor" SG_ 416 SCC_VehStpReq 5;
BA_ "Description" SG_ 416 SCC_VehStpReq "A control request flag for vehicle stop. SCC expects vehicle to be controlled to a complete stop and hold its state.

- SCC 해제 상황 발생시 차량 정차 유지를 위한 제동 요청 신호";
BA_ "Version" SG_ 416 SCC_VehStpReq "17.12.00";
BA_ "UserSigValidity" SG_ 416 SCC_TrgtDstVal 3;
BA_ "GenSigStartValue" SG_ 416 SCC_TrgtDstVal 2047;
BA_ "RoutingFactor" SG_ 416 SCC_TrgtDstVal 5;
BA_ "Description" SG_ 416 SCC_TrgtDstVal "This signal provides the target distance for SCC fallowing control.

- SCC 거리 제어를 위한 목표 차간 거리 정보";
BA_ "Version" SG_ 416 SCC_TrgtDstVal "18.01.07";
BA_ "UserSigValidity" SG_ 426 CLU_Crc1Val 3;
BA_ "GenSigStartValue" SG_ 426 CLU_Crc1Val 65535;
BA_ "RoutingFactor" SG_ 426 CLU_Crc1Val 5;
BA_ "Description" SG_ 426 CLU_Crc1Val "The CRC checking process calculates the CRC over the entire data block, including the CRC result.

- CRC Polynomial (0x1021) , Initial Value : 0xFFFF, XOR value : 0x0000

- The mathematical expression to 16 bit CRC polynomial is given here. G(x) = x16 + ";
BA_ "Version" SG_ 426 CLU_Crc1Val "17.11.00";
BA_ "UserSigValidity" SG_ 426 CLU_AlvCnt1Val 3;
BA_ "RoutingFactor" SG_ 426 CLU_AlvCnt1Val 5;
BA_ "Description" SG_ 426 CLU_AlvCnt1Val "For the first transmission request for a data element the counter shall be initialized with 0 and shall be incremented by 1

for every subsequent send request. When the counter reaches the maximum value(0xFF), then it shall restart with – for the next ";
BA_ "Version" SG_ 426 CLU_AlvCnt1Val "17.11.00";
BA_ "UserSigValidity" SG_ 426 CLU_DtntOutSta 0;
BA_ "RoutingFactor" SG_ 426 CLU_DtntOutSta 5;
BA_ "Description" SG_ 426 CLU_DtntOutSta "This signal indicates the status of detent illumination. Cluster sends the detent information for a Unified Illumination system.";
BA_ "Version" SG_ 426 CLU_DtntOutSta "17.11.00";
BA_ "UserSigValidity" SG_ 426 CLU_SpdUnitTyp 3;
BA_ "RoutingFactor" SG_ 426 CLU_SpdUnitTyp 5;
BA_ "Description" SG_ 426 CLU_SpdUnitTyp "This signal indicates the unit of the speed displayed in the speedometer.";
BA_ "Version" SG_ 426 CLU_SpdUnitTyp "17.11.00";
BA_ "UserSigValidity" SG_ 426 CLU_SWRCLFASwSta 3;
BA_ "RoutingFactor" SG_ 426 CLU_SWRCLFASwSta 5;
BA_ "Description" SG_ 426 CLU_SWRCLFASwSta "LFA/HDA on/off switch";
BA_ "Version" SG_ 426 CLU_SWRCLFASwSta "18.04.00";
BA_ "UserSigValidity" SG_ 426 CLU_RhstaLvlSta 0;
BA_ "RoutingFactor" SG_ 426 CLU_RhstaLvlSta 5;
BA_ "Description" SG_ 426 CLU_RhstaLvlSta "This signal is used for a rheostat level of CLUSTER from 1 to 21 level (21 level : Detent) for a Unified Illumination system.



※ Start Value : Current value";
BA_ "Version" SG_ 426 CLU_RhstaLvlSta "17.11.00";
BA_ "UserSigValidity" SG_ 426 CLU_DisSpdVal 3;
BA_ "RoutingFactor" SG_ 426 CLU_DisSpdVal 5;
BA_ "Description" SG_ 426 CLU_DisSpdVal "The vehicle speed which is indicated in the speedmeter has to be sent to SCC. This value is used for evalution of SCC command values instead of the vehicle velocity in order to avoid significant difference between the speedmeter indicator and the set spe";
BA_ "Version" SG_ 426 CLU_DisSpdVal "17.12.03";
BA_ "UserSigValidity" SG_ 437 FR_CMR_Crc3Val 3;
BA_ "RoutingFactor" SG_ 437 FR_CMR_Crc3Val 3;
BA_ "Description" SG_ 437 FR_CMR_Crc3Val "The CRC checking process calculates the CRC over the entire data block, including the CRC result.

- CRC Polynomial (0x1021) , Initial Value : 0xFFFF, XOR value : 0x0000

- The mathematical expression to 16 bit CRC polynomial is given here. G(x) = x16 + ";
BA_ "Version" SG_ 437 FR_CMR_Crc3Val "17.12.03";
BA_ "UserSigValidity" SG_ 437 FR_CMR_AlvCnt3Val 3;
BA_ "RoutingFactor" SG_ 437 FR_CMR_AlvCnt3Val 3;
BA_ "Description" SG_ 437 FR_CMR_AlvCnt3Val "For the first transmission request for a data element the counter shall be initialized with 0 and shall be incremented by 1

for every subsequent send request. When the counter reaches the maximum value(0xFF), then it shall restart with – for the next ";
BA_ "Version" SG_ 437 FR_CMR_AlvCnt3Val "17.12.03";
BA_ "UserSigValidity" SG_ 437 Info_LftLnQualSta 3;
BA_ "RoutingFactor" SG_ 437 Info_LftLnQualSta 3;
BA_ "Description" SG_ 437 Info_LftLnQualSta "This signal indicates the quality of left line.";
BA_ "Version" SG_ 437 Info_LftLnQualSta "17.12.02";
BA_ "UserSigValidity" SG_ 437 Info_LftLnDptSta 3;
BA_ "RoutingFactor" SG_ 437 Info_LftLnDptSta 3;
BA_ "Description" SG_ 437 Info_LftLnDptSta "This signal indicates the lane departure status of left line.";
BA_ "Version" SG_ 437 Info_LftLnDptSta "17.12.02";
BA_ "UserSigValidity" SG_ 437 Info_LftLnPosVal 3;
BA_ "RoutingFactor" SG_ 437 Info_LftLnPosVal 3;
BA_ "Description" SG_ 437 Info_LftLnPosVal "This signal outputs the position of left line from camera center.";
BA_ "Version" SG_ 437 Info_LftLnPosVal "17.12.02";
BA_ "UserSigValidity" SG_ 437 Info_LftLnHdingAnglVal 3;
BA_ "RoutingFactor" SG_ 437 Info_LftLnHdingAnglVal 3;
BA_ "Description" SG_ 437 Info_LftLnHdingAnglVal "This signal outputs the heading angle of left line.";
BA_ "Version" SG_ 437 Info_LftLnHdingAnglVal "17.12.02";
BA_ "UserSigValidity" SG_ 437 Info_LftLnCvtrVal 3;
BA_ "RoutingFactor" SG_ 437 Info_LftLnCvtrVal 3;
BA_ "Description" SG_ 437 Info_LftLnCvtrVal "This signal outputs the curvature of left line.";
BA_ "Version" SG_ 437 Info_LftLnCvtrVal "17.11.00";
BA_ "UserSigValidity" SG_ 437 Info_LftLnCrvtrDrvtvVal 3;
BA_ "RoutingFactor" SG_ 437 Info_LftLnCrvtrDrvtvVal 3;
BA_ "Version" SG_ 437 Info_LftLnCrvtrDrvtvVal "17.11.00";
BA_ "UserSigValidity" SG_ 437 Info_RtLnQualSta 3;
BA_ "RoutingFactor" SG_ 437 Info_RtLnQualSta 3;
BA_ "Description" SG_ 437 Info_RtLnQualSta "This signal indicates the quality of right line.";
BA_ "Version" SG_ 437 Info_RtLnQualSta "17.12.02";
BA_ "UserSigValidity" SG_ 437 Info_RtLnDptSta 3;
BA_ "RoutingFactor" SG_ 437 Info_RtLnDptSta 3;
BA_ "Description" SG_ 437 Info_RtLnDptSta "This signal indicates the lane departure status of right line.";
BA_ "Version" SG_ 437 Info_RtLnDptSta "17.12.02";
BA_ "UserSigValidity" SG_ 437 Info_RtLnPosVal 3;
BA_ "RoutingFactor" SG_ 437 Info_RtLnPosVal 3;
BA_ "Description" SG_ 437 Info_RtLnPosVal "This signal outputs the position of right line from camera center.";
BA_ "Version" SG_ 437 Info_RtLnPosVal "17.12.02";
BA_ "UserSigValidity" SG_ 437 Info_RtLnHdingAnglVal 3;
BA_ "RoutingFactor" SG_ 437 Info_RtLnHdingAnglVal 3;
BA_ "Description" SG_ 437 Info_RtLnHdingAnglVal "This signal outputs the heading angle of right line.";
BA_ "Version" SG_ 437 Info_RtLnHdingAnglVal "17.12.02";
BA_ "UserSigValidity" SG_ 437 Info_RtLnCvtrVal 3;
BA_ "RoutingFactor" SG_ 437 Info_RtLnCvtrVal 3;
BA_ "Description" SG_ 437 Info_RtLnCvtrVal "This signal outputs the curvature of right line.";
BA_ "Version" SG_ 437 Info_RtLnCvtrVal "17.11.00";
BA_ "UserSigValidity" SG_ 437 Info_RtLnCrvtrDrvtvVal 3;
BA_ "RoutingFactor" SG_ 437 Info_RtLnCrvtrDrvtvVal 3;
BA_ "Version" SG_ 437 Info_RtLnCrvtrDrvtvVal "17.11.00";
BA_ "UserSigValidity" SG_ 442 ADAS_CMD_AlvCnt40Val 3;
BA_ "RoutingFactor" SG_ 442 ADAS_CMD_AlvCnt40Val 3;
BA_ "Description" SG_ 442 ADAS_CMD_AlvCnt40Val "For the first transmission request for a data element the counter shall be initialized with 0 and shall be incremented by 1

for every subsequent send request. When the counter reaches the maximum value(0xFF), then it shall restart with – for the next ";
BA_ "Version" SG_ 442 ADAS_CMD_AlvCnt40Val "17.12.00";
BA_ "UserSigValidity" SG_ 442 BCA_Sta 3;
BA_ "RoutingFactor" SG_ 442 BCA_Sta 3;
BA_ "Description" SG_ 442 BCA_Sta "This signal indicates the status of BCA";
BA_ "Version" SG_ 442 BCA_Sta "17.12.00";
BA_ "UserSigValidity" SG_ 442 BCA_LftWrngSta 3;
BA_ "RoutingFactor" SG_ 442 BCA_LftWrngSta 3;
BA_ "Description" SG_ 442 BCA_LftWrngSta "This signal indicates the left warning of BCA";
BA_ "Version" SG_ 442 BCA_LftWrngSta "17.12.03";
BA_ "UserSigValidity" SG_ 442 BCA_RtWrngSta 3;
BA_ "RoutingFactor" SG_ 442 BCA_RtWrngSta 3;
BA_ "Description" SG_ 442 BCA_RtWrngSta "This signal indicates the Right warning of BCA";
BA_ "Version" SG_ 442 BCA_RtWrngSta "17.12.03";
BA_ "UserSigValidity" SG_ 463 SWRC_Crc3Val 3;
BA_ "GenSigStartValue" SG_ 463 SWRC_Crc3Val 255;
BA_ "Description" SG_ 463 SWRC_Crc3Val "The CRC checking process calculates the CRC over the entire data block, including the CRC result CRC Polynomial (0x1D) ,

Initial Value : 0x00, XOR value : 0x00

The mathematical expression to 8 bit CRC polynomial is given here. G(x) = x8 + x4 + x3 + x2 ";
BA_ "Version" SG_ 463 SWRC_Crc3Val "17.11.00";
BA_ "UserSigValidity" SG_ 463 SWRC_AlvCnt3Val 3;
BA_ "Description" SG_ 463 SWRC_AlvCnt3Val "For the first transmission request for a data element the counter shall be initialized with 0 and shall be incremented by 1

for every subsequent send request. When the counter reaches the maximum value(0xE), then it shall restart with – for the next s";
BA_ "Version" SG_ 463 SWRC_AlvCnt3Val "17.11.00";
BA_ "UserSigValidity" SG_ 463 SWRC_CrsSwSta 3;
BA_ "Description" SG_ 463 SWRC_CrsSwSta "Cruise switch status

C-CAN Gateway needed";
BA_ "Version" SG_ 463 SWRC_CrsSwSta "18.07.00";
BA_ "UserSigValidity" SG_ 463 SWRC_CrsMainSwSta 3;
BA_ "Description" SG_ 463 SWRC_CrsMainSwSta "Cruise on/off switch

C-CAN Gateway needed";
BA_ "Version" SG_ 463 SWRC_CrsMainSwSta "17.11.00";
BA_ "UserSigValidity" SG_ 463 SWRC_SldMainSwSta 3;
BA_ "Description" SG_ 463 SWRC_SldMainSwSta "Speedlimiter on/off switch

C-CAN Gateway needed";
BA_ "Version" SG_ 463 SWRC_SldMainSwSta "17.11.00";
BA_ "UserSigValidity" SG_ 463 SWRC_LFASwSta 3;
BA_ "Description" SG_ 463 SWRC_LFASwSta "LFA on/off switch

C-CAN Gateway needed";
BA_ "Version" SG_ 463 SWRC_LFASwSta "17.11.00";
BA_ "UserSigValidity" SG_ 480 ADAS_CMD_Crc31Val 3;
BA_ "RoutingFactor" SG_ 480 ADAS_CMD_Crc31Val 3;
BA_ "Description" SG_ 480 ADAS_CMD_Crc31Val "The CRC checking process calculates the CRC over the entire data block, including the CRC result.

- CRC Polynomial (0x1021) , Initial Value : 0xFFFF, XOR value : 0x0000

- The mathematical expression to 16 bit CRC polynomial is given here. G(x) = x16 + ";
BA_ "Version" SG_ 480 ADAS_CMD_Crc31Val "17.12.03";
BA_ "UserSigValidity" SG_ 480 ADAS_CMD_AlvCnt31Val 3;
BA_ "RoutingFactor" SG_ 480 ADAS_CMD_AlvCnt31Val 3;
BA_ "Description" SG_ 480 ADAS_CMD_AlvCnt31Val "For the first transmission request for a data element the counter shall be initialized with 0 and shall be incremented by 1

for every subsequent send request. When the counter reaches the maximum value(0xFF), then it shall restart with – for the next ";
BA_ "Version" SG_ 480 ADAS_CMD_AlvCnt31Val "17.12.03";
BA_ "UserSigValidity" SG_ 480 HDA_OptUsmSta 3;
BA_ "RoutingFactor" SG_ 480 HDA_OptUsmSta 3;
BA_ "Description" SG_ 480 HDA_OptUsmSta "This is HDA system status needed for the cluster USM display.";
BA_ "Version" SG_ 480 HDA_OptUsmSta "17.12.02";
BA_ "UserSigValidity" SG_ 480 LFA_OptUsmSta 3;
BA_ "RoutingFactor" SG_ 480 LFA_OptUsmSta 3;
BA_ "Description" SG_ 480 LFA_OptUsmSta "This is LFA system status needed for the cluster USM display.";
BA_ "Version" SG_ 480 LFA_OptUsmSta "17.12.02";
BA_ "UserSigValidity" SG_ 480 HDA_CntrlModSta 3;
BA_ "RoutingFactor" SG_ 480 HDA_CntrlModSta 3;
BA_ "Description" SG_ 480 HDA_CntrlModSta "This is HDA Control Mode needed for longitudinal/lateral control and cluster display.";
BA_ "Version" SG_ 480 HDA_CntrlModSta "17.12.02";
BA_ "UserSigValidity" SG_ 480 HDA_InfoPUDis 3;
BA_ "RoutingFactor" SG_ 480 HDA_InfoPUDis 3;
BA_ "Description" SG_ 480 HDA_InfoPUDis "This is HDA information display needed for the cluster pop-up display.";
BA_ "Version" SG_ 480 HDA_InfoPUDis "17.12.02";
BA_ "UserSigValidity" SG_ 480 HDA_AutoSetSpdSta 3;
BA_ "RoutingFactor" SG_ 480 HDA_AutoSetSpdSta 3;
BA_ "Description" SG_ 480 HDA_AutoSetSpdSta "This is information if Auto Set Speed Control is enabled or not";
BA_ "Version" SG_ 480 HDA_AutoSetSpdSta "17.12.02";
BA_ "UserSigValidity" SG_ 480 HDA_AutoSetSpdUpdtSta 3;
BA_ "RoutingFactor" SG_ 480 HDA_AutoSetSpdUpdtSta 3;
BA_ "Description" SG_ 480 HDA_AutoSetSpdUpdtSta "This is information if Auto Set Speed Control is updated or not.";
BA_ "Version" SG_ 480 HDA_AutoSetSpdUpdtSta "17.12.02";
BA_ "UserSigValidity" SG_ 480 HDA_AutoSetSpdVal 3;
BA_ "RoutingFactor" SG_ 480 HDA_AutoSetSpdVal 3;
BA_ "Description" SG_ 480 HDA_AutoSetSpdVal "This is auto set speed value for SCC controller in Auto Set Spped Mode.";
BA_ "Version" SG_ 480 HDA_AutoSetSpdVal "17.12.02";
BA_ "UserSigValidity" SG_ 480 HDA_LFA_SymSta 3;
BA_ "RoutingFactor" SG_ 480 HDA_LFA_SymSta 3;
BA_ "Description" SG_ 480 HDA_LFA_SymSta "This signal shows the state of steering assist.";
BA_ "Version" SG_ 480 HDA_LFA_SymSta "17.12.02";
BA_ "UserSigValidity" SG_ 480 HDA_LFA_WrnSnd 3;
BA_ "RoutingFactor" SG_ 480 HDA_LFA_WrnSnd 3;
BA_ "Description" SG_ 480 HDA_LFA_WrnSnd "HDA/LFA Additional Warning Sound

";
BA_ "Version" SG_ 480 HDA_LFA_WrnSnd "18.02.03";
BA_ "GenSigStartValue" SG_ 506 ISLA_Cntry 15;
BA_ "UserSigValidity" SG_ 506 FR_CMR_Crc2Val 3;
BA_ "RoutingFactor" SG_ 506 FR_CMR_Crc2Val 2;
BA_ "Description" SG_ 506 FR_CMR_Crc2Val "The CRC checking process calculates the CRC over the entire data block, including the CRC result.

- CRC Polynomial (0x1021) , Initial Value : 0xFFFF, XOR value : 0x0000

- The mathematical expression to 16 bit CRC polynomial is given here. G(x) = x16 + ";
BA_ "Version" SG_ 506 FR_CMR_Crc2Val "17.12.03";
BA_ "UserSigValidity" SG_ 506 FR_CMR_AlvCnt2Val 3;
BA_ "RoutingFactor" SG_ 506 FR_CMR_AlvCnt2Val 2;
BA_ "Description" SG_ 506 FR_CMR_AlvCnt2Val "For the first transmission request for a data element the counter shall be initialized with 0 and shall be incremented by 1

for every subsequent send request. When the counter reaches the maximum value(0xFF), then it shall restart with – for the next ";
BA_ "Version" SG_ 506 FR_CMR_AlvCnt2Val "17.12.03";
BA_ "UserSigValidity" SG_ 506 ISLW_OptUsmSta 3;
BA_ "RoutingFactor" SG_ 506 ISLW_OptUsmSta 2;
BA_ "Description" SG_ 506 ISLW_OptUsmSta "ISLW option information";
BA_ "Version" SG_ 506 ISLW_OptUsmSta "17.12.02";
BA_ "UserSigValidity" SG_ 506 ISLW_SysSta 3;
BA_ "RoutingFactor" SG_ 506 ISLW_SysSta 2;
BA_ "Description" SG_ 506 ISLW_SysSta "Validity of ISLW information";
BA_ "Version" SG_ 506 ISLW_SysSta "17.12.02";
BA_ "UserSigValidity" SG_ 506 ISLW_NoPassingInfoDis 3;
BA_ "RoutingFactor" SG_ 506 ISLW_NoPassingInfoDis 2;
BA_ "Description" SG_ 506 ISLW_NoPassingInfoDis "This signal indicates additional information of ISLW. For example no passing.



";
BA_ "Version" SG_ 506 ISLW_NoPassingInfoDis "17.12.02";
BA_ "UserSigValidity" SG_ 506 ISLW_OvrlpSignDis 3;
BA_ "RoutingFactor" SG_ 506 ISLW_OvrlpSignDis 2;
BA_ "Description" SG_ 506 ISLW_OvrlpSignDis "indicates presence of Overlap sign";
BA_ "Version" SG_ 506 ISLW_OvrlpSignDis "17.12.02";
BA_ "UserSigValidity" SG_ 506 ISLW_SpdCluMainDis 3;
BA_ "RoutingFactor" SG_ 506 ISLW_SpdCluMainDis 2;
BA_ "Description" SG_ 506 ISLW_SpdCluMainDis "Main Speed Information for cluster display

 in main page

(0x1~0xFCH: 1*(HEX VALUE) 



[KPH or MPH :Reference signal is  CF_Clu_SPEED_UNIT of CLU])



";
BA_ "Version" SG_ 506 ISLW_SpdCluMainDis "17.12.02";
BA_ "UserSigValidity" SG_ 506 ISLW_SpdNaviMainDis 3;
BA_ "RoutingFactor" SG_ 506 ISLW_SpdNaviMainDis 2;
BA_ "Description" SG_ 506 ISLW_SpdNaviMainDis "Main Speed information for navigation display

 in main page

(0x1~0xFCH: 1*(HEX VALUE) 



[KPH or MPH :Reference signal is  Navi_ISLW_SpdUnit of Navigation)



";
BA_ "Version" SG_ 506 ISLW_SpdNaviMainDis "17.12.02";
BA_ "UserSigValidity" SG_ 506 ISLW_SubCondinfoSta1 3;
BA_ "RoutingFactor" SG_ 506 ISLW_SubCondinfoSta1 2;
BA_ "Description" SG_ 506 ISLW_SubCondinfoSta1 "Indicates 1st conditional traffic sign status";
BA_ "Version" SG_ 506 ISLW_SubCondinfoSta1 "17.12.02";
BA_ "UserSigValidity" SG_ 506 ISLW_SubCondinfoSta2 3;
BA_ "RoutingFactor" SG_ 506 ISLW_SubCondinfoSta2 2;
BA_ "Description" SG_ 506 ISLW_SubCondinfoSta2 "Indicates 2nd conditional traffic sign status";
BA_ "Version" SG_ 506 ISLW_SubCondinfoSta2 "17.12.02";
BA_ "UserSigValidity" SG_ 506 ISLW_SpdCluSubMainDis 3;
BA_ "RoutingFactor" SG_ 506 ISLW_SpdCluSubMainDis 2;
BA_ "Description" SG_ 506 ISLW_SpdCluSubMainDis "Main Speed Information for cluster display in ISLW detail page";
BA_ "Version" SG_ 506 ISLW_SpdCluSubMainDis "17.12.02";
BA_ "UserSigValidity" SG_ 506 ISLW_SpdCluDisSubCond1 3;
BA_ "RoutingFactor" SG_ 506 ISLW_SpdCluDisSubCond1 2;
BA_ "Description" SG_ 506 ISLW_SpdCluDisSubCond1 "Indicates conditional speed limit/no passing of 1st conditional traffic sign for Cluster in ISLW Detail page";
BA_ "Version" SG_ 506 ISLW_SpdCluDisSubCond1 "17.12.02";
BA_ "UserSigValidity" SG_ 506 ISLW_SpdCluDisSubCond2 3;
BA_ "RoutingFactor" SG_ 506 ISLW_SpdCluDisSubCond2 2;
BA_ "Description" SG_ 506 ISLW_SpdCluDisSubCond2 "Indicates conditional speed limit/no passing of 2nd conditional traffic sign for Cluster in ISLW Detail page";
BA_ "Version" SG_ 506 ISLW_SpdCluDisSubCond2 "17.12.02";
BA_ "UserSigValidity" SG_ 506 ISLW_SpdNaviSubMainDis 3;
BA_ "RoutingFactor" SG_ 506 ISLW_SpdNaviSubMainDis 2;
BA_ "Description" SG_ 506 ISLW_SpdNaviSubMainDis "Main Speed Information for NAVI display in ISLW detail page";
BA_ "Version" SG_ 506 ISLW_SpdNaviSubMainDis "17.12.02";
BA_ "UserSigValidity" SG_ 506 ISLW_SpdNaviDisSubCond1 3;
BA_ "RoutingFactor" SG_ 506 ISLW_SpdNaviDisSubCond1 2;
BA_ "Description" SG_ 506 ISLW_SpdNaviDisSubCond1 "Indicates conditional speed limit/no passing of 1st conditional traffic sign for NAVI in ISLW Detail page";
BA_ "Version" SG_ 506 ISLW_SpdNaviDisSubCond1 "17.12.02";
BA_ "UserSigValidity" SG_ 506 ISLW_SpdNaviDisSubCond2 3;
BA_ "RoutingFactor" SG_ 506 ISLW_SpdNaviDisSubCond2 2;
BA_ "Description" SG_ 506 ISLW_SpdNaviDisSubCond2 "Indicates conditional speed limit/no passing of 2nd conditional traffic sign for NAVI in ISLW Detail page";
BA_ "Version" SG_ 506 ISLW_SpdNaviDisSubCond2 "17.12.02";
BA_ "UserSigValidity" SG_ 549 CLU_AlvCnt2Val 3;
BA_ "RoutingFactor" SG_ 549 CLU_AlvCnt2Val 2;
BA_ "Description" SG_ 549 CLU_AlvCnt2Val "For the first transmission request for a data element the counter shall be initialized with 0 and shall be incremented by 1

for every subsequent send request. When the counter reaches the maximum value(0xFF), then it shall restart with – for the next ";
BA_ "Version" SG_ 549 CLU_AlvCnt2Val "17.11.00";
BA_ "UserSigValidity" SG_ 549 CLU_TerrainMainSwSta 3;
BA_ "RoutingFactor" SG_ 549 CLU_TerrainMainSwSta 2;
BA_ "Description" SG_ 549 CLU_TerrainMainSwSta "This signal represents the terrain mode main switch's state.

0x1:On-Road /0x2:Off-Road

";
BA_ "Version" SG_ 549 CLU_TerrainMainSwSta "18.04.00";
BA_ "UserSigValidity" SG_ 549 CLU_OdoVal 3;
BA_ "RoutingFactor" SG_ 549 CLU_OdoVal 2;
BA_ "Description" SG_ 549 CLU_OdoVal "This signal indicates mileage counter of a vehicle. Cluster calculates total mileage and sends it to SCC and CUBIS. This value shall be the same with the mileage that is displayed to a driver.";
BA_ "Version" SG_ 549 CLU_OdoVal "17.11.00";
BA_ "UserSigValidity" SG_ 549 CLU_DawLastBrkTimeVal 3;
BA_ "RoutingFactor" SG_ 549 CLU_DawLastBrkTimeVal 2;
BA_ "Description" SG_ 549 CLU_DawLastBrkTimeVal "This signal indicates that the elapsed time count after last driver's break. The elapsed time count increase 1 at an interval of 30 minutes.

";
BA_ "Version" SG_ 549 CLU_DawLastBrkTimeVal "17.11.00";
BA_ "UserSigValidity" SG_ 549 CLU_IceWrnIndSta 3;
BA_ "RoutingFactor" SG_ 549 CLU_IceWrnIndSta 2;
BA_ "Description" SG_ 549 CLU_IceWrnIndSta "This signal indicates that the Ice warning indicator in the cluster is on or off.

When Ice warning indicator is on, its value is 0x1 otherwise its value is 0x0.

";
BA_ "Version" SG_ 549 CLU_IceWrnIndSta "17.11.00";
BA_ "UserSigValidity" SG_ 549 CLU_DrvngModSwSta 3;
BA_ "RoutingFactor" SG_ 549 CLU_DrvngModSwSta 2;
BA_ "Description" SG_ 549 CLU_DrvngModSwSta "This signal occurs when drive mode switch is selected either 'Normal' or 'Eco' or 'Sport' or 'Sport+' or 'Smart' or 'Custom' or 'N-mode'. ";
BA_ "Version" SG_ 549 CLU_DrvngModSwSta "18.02.03";
BA_ "UserSigValidity" SG_ 549 CLU_TerrainModSwSta 3;
BA_ "RoutingFactor" SG_ 549 CLU_TerrainModSwSta 2;
BA_ "Description" SG_ 549 CLU_TerrainModSwSta "This signal occurs when terrain mode switch is selected either 'Snow' or 'Sand' or 'Mud'.";
BA_ "Version" SG_ 549 CLU_TerrainModSwSta "18.02.03";
BA_ "UserSigValidity" SG_ 560 HCU_BrkLmpOnReq 3;
BA_ "RoutingFactor" SG_ 560 HCU_BrkLmpOnReq 2;
BA_ "Description" SG_ 560 HCU_BrkLmpOnReq "Brake Lamp On Request ";
BA_ "Version" SG_ 560 HCU_BrkLmpOnReq "17.11.00";
BA_ "UserSigValidity" SG_ 608 ENG_TransmsnTyp 3;
BA_ "RoutingFactor" SG_ 608 ENG_TransmsnTyp 2;
BA_ "Description" SG_ 608 ENG_TransmsnTyp "A/T or M/T information generated by automatic variant coding.

A/T information is got from the “TCU_TYPE” signal of TCU1 message. (See TCU1 message information)";
BA_ "Version" SG_ 608 ENG_TransmsnTyp "17.11.00";
BA_ "UserSigValidity" SG_ 608 ENG_EngDsplceTyp 3;
BA_ "RoutingFactor" SG_ 608 ENG_EngDsplceTyp 2;
BA_ "Description" SG_ 608 ENG_EngDsplceTyp "This signal indicates the engine displacement (volume).";
BA_ "Version" SG_ 608 ENG_EngDsplceTyp "17.12.00";
BA_ "UserSigValidity" SG_ 613 HEV_BrkLtSwSta 3;
BA_ "RoutingFactor" SG_ 613 HEV_BrkLtSwSta 2;
BA_ "Description" SG_ 613 HEV_BrkLtSwSta "Brake light Switch";
BA_ "Version" SG_ 613 HEV_BrkLtSwSta "17.11.00";
BA_ "UserSigValidity" SG_ 661 OBD_EngRpmVal 3;
BA_ "RoutingFactor" SG_ 661 OBD_EngRpmVal 2;
BA_ "Description" SG_ 661 OBD_EngRpmVal "PID_0CH : Parameter ID for CARB OBD regulation - SAE J1979 Service Mode 02

This signal indicates engine speed (RPM-Revolution per Min.) and compatible with signal “N” in EMS1 message.";
BA_ "Version" SG_ 661 OBD_EngRpmVal "17.12.00";
BA_ "UserSigValidity" SG_ 674 FR_CMR_Ln_Crc01Val 3;
BA_ "GenSigStartValue" SG_ 674 FR_CMR_Ln_Crc01Val 65535;
BA_ "Description" SG_ 674 FR_CMR_Ln_Crc01Val "[Cyclic redundancy check] The CRC checking process calculates the CRC over the entire data block, including the CRC result CRC Polynomial (0x1021) ,

Initial Value : 0xFFFF, XOR value : 0x0000

The mathematical expression to 16 bit CRC polynomial is give";
BA_ "Version" SG_ 674 FR_CMR_Ln_Crc01Val "18.03.01";
BA_ "UserSigValidity" SG_ 674 FR_CMR_Ln_AlvCnt01Val 3;
BA_ "Description" SG_ 674 FR_CMR_Ln_AlvCnt01Val "[Alive counter] For the first transmission request for a data element the counter shall be initialized with 0 and shall be incremented by 1

for every subsequent send request. When the counter reaches the maximum value(0xFF), then it shall restart with �";
BA_ "Version" SG_ 674 FR_CMR_Ln_AlvCnt01Val "18.03.01";
BA_ "UserSigValidity" SG_ 674 FR_CMR_Ln_LftDptDstVal 3;
BA_ "GenSigStartValue" SG_ 674 FR_CMR_Ln_LftDptDstVal 1000;
BA_ "Description" SG_ 674 FR_CMR_Ln_LftDptDstVal "[Position parameter for the left-side line on current lane] the distance between lane mark (line) and the the subject vehicle (the center of front bumper) on lateral direction. (parameter C0 of 3rd degree polynomial model X= (C3)*Z^3+(C2)*Z^2+(C1)*Z+(C0)";
BA_ "Version" SG_ 674 FR_CMR_Ln_LftDptDstVal "18.03.01";
BA_ "UserSigValidity" SG_ 674 FR_CMR_Ln_RtDptDstVal 3;
BA_ "GenSigStartValue" SG_ 674 FR_CMR_Ln_RtDptDstVal 1000;
BA_ "Description" SG_ 674 FR_CMR_Ln_RtDptDstVal "[Position parameter for the right-side line on current lane] the distance between lane mark (line) and the the subject vehicle (the center of front bumper) on lateral direction. (parameter C0 of 3rd degree polynomial model X= (C3)*Z^3+(C2)*Z^2+(C1)*Z+(C0";
BA_ "Version" SG_ 674 FR_CMR_Ln_RtDptDstVal "18.03.01";
BA_ "UserSigValidity" SG_ 674 FR_CMR_Ln_LftDptAnglVal 3;
BA_ "GenSigStartValue" SG_ 674 FR_CMR_Ln_LftDptAnglVal 365;
BA_ "Description" SG_ 674 FR_CMR_Ln_LftDptAnglVal "[Heading angle parameter for the left-side line on current lane] physical slope of the lane mark. (parameter C1 of 3rd degree polynomial model X= (C3)*Z^3+(C2)*Z^2+(C1)*Z+(C0)) 

A positive value means steering towards the left (CCW).";
BA_ "Version" SG_ 674 FR_CMR_Ln_LftDptAnglVal "18.03.01";
BA_ "UserSigValidity" SG_ 674 FR_CMR_Ln_RtDptAnglVal 3;
BA_ "GenSigStartValue" SG_ 674 FR_CMR_Ln_RtDptAnglVal 365;
BA_ "Description" SG_ 674 FR_CMR_Ln_RtDptAnglVal "[Heading angle parameter for the right-side line on current lane] physical slope of the lane mark. (parameter C1 of 3rd degree polynomial model X= (C3)*Z^3+(C2)*Z^2+(C1)*Z+(C0)) 

A positive value means steering towards the left (CCW). ";
BA_ "Version" SG_ 674 FR_CMR_Ln_RtDptAnglVal "18.03.01";
BA_ "UserSigValidity" SG_ 674 FR_CMR_Ln_LftCurveVal 3;
BA_ "GenSigStartValue" SG_ 674 FR_CMR_Ln_LftCurveVal 32753;
BA_ "Description" SG_ 674 FR_CMR_Ln_LftCurveVal "[Curvature parameter for the left-side on current lane] parameter C2 of 3rd degree polynomial model X= (C3)*Z^3+(C2)*Z^2+(C1)*Z+(C0)";
BA_ "Version" SG_ 674 FR_CMR_Ln_LftCurveVal "18.03.01";
BA_ "UserSigValidity" SG_ 674 FR_CMR_Ln_RtCurveVal 3;
BA_ "GenSigStartValue" SG_ 674 FR_CMR_Ln_RtCurveVal 32753;
BA_ "Description" SG_ 674 FR_CMR_Ln_RtCurveVal "[Curvature parameter for the right-side on current lane] parameter C2 of 3rd degree polynomial model X= (C3)*Z^3+(C2)*Z^2+(C1)*Z+(C0)";
BA_ "Version" SG_ 674 FR_CMR_Ln_RtCurveVal "18.03.01";
BA_ "UserSigValidity" SG_ 674 FR_CMR_Ln_LftCurveRatVal 3;
BA_ "GenSigStartValue" SG_ 674 FR_CMR_Ln_LftCurveRatVal 32707;
BA_ "Description" SG_ 674 FR_CMR_Ln_LftCurveRatVal "[Curvature derivative parameter for the left-side line on current lane] parameter C3 of 3rd degree polynomial model X= (C3)*Z^3+(C2)*Z^2+(C1)*Z+(C0) ";
BA_ "Version" SG_ 674 FR_CMR_Ln_LftCurveRatVal "18.03.01";
BA_ "UserSigValidity" SG_ 674 FR_CMR_Ln_RtCurveRatVal 3;
BA_ "GenSigStartValue" SG_ 674 FR_CMR_Ln_RtCurveRatVal 32707;
BA_ "Description" SG_ 674 FR_CMR_Ln_RtCurveRatVal "[Curvature derivative parameter for the right-side line on current lane] parameter C3 of 3rd degree polynomial model X= (C3)*Z^3+(C2)*Z^2+(C1)*Z+(C0) ";
BA_ "Version" SG_ 674 FR_CMR_Ln_RtCurveRatVal "18.03.01";
BA_ "UserSigValidity" SG_ 675 FR_CMR_Ln_Crc02Val 3;
BA_ "GenSigStartValue" SG_ 675 FR_CMR_Ln_Crc02Val 65535;
BA_ "Description" SG_ 675 FR_CMR_Ln_Crc02Val "[Cyclic redundancy check] The CRC checking process calculates the CRC over the entire data block, including the CRC result CRC Polynomial (0x1021) ,

Initial Value : 0xFFFF, XOR value : 0x0000

The mathematical expression to 16 bit CRC polynomial is give";
BA_ "Version" SG_ 675 FR_CMR_Ln_Crc02Val "18.03.01";
BA_ "UserSigValidity" SG_ 675 FR_CMR_Ln_AlvCnt02Val 3;
BA_ "Description" SG_ 675 FR_CMR_Ln_AlvCnt02Val "[Alive counter] For the first transmission request for a data element the counter shall be initialized with 0 and shall be incremented by 1

for every subsequent send request. When the counter reaches the maximum value(0xFF), then it shall restart with �";
BA_ "Version" SG_ 675 FR_CMR_Ln_AlvCnt02Val "18.03.01";
BA_ "UserSigValidity" SG_ 675 FR_CMR_Ln_LftNextLnDptDstVal 3;
BA_ "GenSigStartValue" SG_ 675 FR_CMR_Ln_LftNextLnDptDstVal 1000;
BA_ "Description" SG_ 675 FR_CMR_Ln_LftNextLnDptDstVal "[Position parameter for the left lane] the distance between lane mark (line) and the the subject vehicle (the center of front bumper) on lateral direction. (parameter C0 of 3rd degree polynomial model X= (C3)*Z^3+(C2)*Z^2+(C1)*Z+(C0))

If line is existed";
BA_ "Version" SG_ 675 FR_CMR_Ln_LftNextLnDptDstVal "18.03.01";
BA_ "UserSigValidity" SG_ 675 FR_CMR_Ln_RtNextDptDstVal 3;
BA_ "GenSigStartValue" SG_ 675 FR_CMR_Ln_RtNextDptDstVal 1000;
BA_ "Description" SG_ 675 FR_CMR_Ln_RtNextDptDstVal "[Position parameter for the right lane] the distance between lane mark (line) and the the subject vehicle (the center of front bumper) on lateral direction. (parameter C0 of 3rd degree polynomial model X= (C3)*Z^3+(C2)*Z^2+(C1)*Z+(C0))

If line is locate";
BA_ "Version" SG_ 675 FR_CMR_Ln_RtNextDptDstVal "18.03.01";
BA_ "UserSigValidity" SG_ 675 FR_CMR_Ln_LftNextDptAnglVal 3;
BA_ "GenSigStartValue" SG_ 675 FR_CMR_Ln_LftNextDptAnglVal 365;
BA_ "Description" SG_ 675 FR_CMR_Ln_LftNextDptAnglVal "[Heading angle parameter for the left lane] physical slope of the lane mark. (parameter C1 of 3rd degree polynomial model X= (C3)*Z^3+(C2)*Z^2+(C1)*Z+(C0)) 

A positive value means steering towards the left (CCW).";
BA_ "Version" SG_ 675 FR_CMR_Ln_LftNextDptAnglVal "18.03.01";
BA_ "UserSigValidity" SG_ 675 FR_CMR_Ln_RtNextDptAnglVal 3;
BA_ "GenSigStartValue" SG_ 675 FR_CMR_Ln_RtNextDptAnglVal 365;
BA_ "Description" SG_ 675 FR_CMR_Ln_RtNextDptAnglVal "[Heading angle parameter for the right lane] physical slope of the lane mark. (parameter C1 of 3rd degree polynomial model X= (C3)*Z^3+(C2)*Z^2+(C1)*Z+(C0)) 

A positive value means steering towards the left (CCW). ";
BA_ "Version" SG_ 675 FR_CMR_Ln_RtNextDptAnglVal "18.03.01";
BA_ "UserSigValidity" SG_ 675 FR_CMR_Ln_LftNextCurveVal 3;
BA_ "GenSigStartValue" SG_ 675 FR_CMR_Ln_LftNextCurveVal 32753;
BA_ "Description" SG_ 675 FR_CMR_Ln_LftNextCurveVal "[Curvature parameter for the left lane] parameter C2 of 3rd degree polynomial model X= (C3)*Z^3+(C2)*Z^2+(C1)*Z+(C0)";
BA_ "Version" SG_ 675 FR_CMR_Ln_LftNextCurveVal "18.03.01";
BA_ "UserSigValidity" SG_ 675 FR_CMR_Ln_RtNextCurveVal 3;
BA_ "GenSigStartValue" SG_ 675 FR_CMR_Ln_RtNextCurveVal 32753;
BA_ "Description" SG_ 675 FR_CMR_Ln_RtNextCurveVal "[Curvature parameter for the right lane] parameter C2 of 3rd degree polynomial model X= (C3)*Z^3+(C2)*Z^2+(C1)*Z+(C0)";
BA_ "Version" SG_ 675 FR_CMR_Ln_RtNextCurveVal "18.03.01";
BA_ "UserSigValidity" SG_ 675 FR_CMR_Ln_LftNextCurveRatVal 3;
BA_ "GenSigStartValue" SG_ 675 FR_CMR_Ln_LftNextCurveRatVal 32707;
BA_ "Description" SG_ 675 FR_CMR_Ln_LftNextCurveRatVal "[Curvature derivative parameter for the left lane] parameter C3 of 3rd degree polynomial model X= (C3)*Z^3+(C2)*Z^2+(C1)*Z+(C0) ";
BA_ "Version" SG_ 675 FR_CMR_Ln_LftNextCurveRatVal "18.03.01";
BA_ "UserSigValidity" SG_ 675 FR_CMR_Ln_RtNextCurveRatVal 3;
BA_ "GenSigStartValue" SG_ 675 FR_CMR_Ln_RtNextCurveRatVal 32707;
BA_ "Description" SG_ 675 FR_CMR_Ln_RtNextCurveRatVal "[Curvature derivative parameter for the right lane] parameter C3 of 3rd degree polynomial model X= (C3)*Z^3+(C2)*Z^2+(C1)*Z+(C0) ";
BA_ "Version" SG_ 675 FR_CMR_Ln_RtNextCurveRatVal "18.03.01";
BA_ "UserSigValidity" SG_ 676 FR_CMR_Ln_Crc03Val 3;
BA_ "GenSigStartValue" SG_ 676 FR_CMR_Ln_Crc03Val 65535;
BA_ "Description" SG_ 676 FR_CMR_Ln_Crc03Val "[Cyclic redundancy check] The CRC checking process calculates the CRC over the entire data block, including the CRC result CRC Polynomial (0x1021) ,

Initial Value : 0xFFFF, XOR value : 0x0000

The mathematical expression to 16 bit CRC polynomial is give";
BA_ "Version" SG_ 676 FR_CMR_Ln_Crc03Val "18.03.01";
BA_ "UserSigValidity" SG_ 676 FR_CMR_Ln_AlvCnt03Val 3;
BA_ "Description" SG_ 676 FR_CMR_Ln_AlvCnt03Val "[Alive counter] For the first transmission request for a data element the counter shall be initialized with 0 and shall be incremented by 1

for every subsequent send request. When the counter reaches the maximum value(0xFF), then it shall restart with �";
BA_ "Version" SG_ 676 FR_CMR_Ln_AlvCnt03Val "18.03.01";
BA_ "UserSigValidity" SG_ 676 FR_CMR_Ln_WthLnLft01Val 3;
BA_ "Description" SG_ 676 FR_CMR_Ln_WthLnLft01Val "Line width of the left-side line on current lane";
BA_ "Version" SG_ 676 FR_CMR_Ln_WthLnLft01Val "18.03.01";
BA_ "UserSigValidity" SG_ 676 FR_CMR_Ln_WthLnRt01Val 3;
BA_ "Description" SG_ 676 FR_CMR_Ln_WthLnRt01Val "Line width of the right-side line on current lane";
BA_ "Version" SG_ 676 FR_CMR_Ln_WthLnRt01Val "18.03.01";
BA_ "UserSigValidity" SG_ 676 FR_CMR_Ln_ClfctLft01Sta 3;
BA_ "Description" SG_ 676 FR_CMR_Ln_ClfctLft01Sta "[Type of the left-side line on current lane] dashed line, solid line, road edge, bott's dot, etc.";
BA_ "Version" SG_ 676 FR_CMR_Ln_ClfctLft01Sta "18.03.01";
BA_ "UserSigValidity" SG_ 676 FR_CMR_Ln_ClfctRt01Sta 3;
BA_ "Description" SG_ 676 FR_CMR_Ln_ClfctRt01Sta "[Type of the right-side line on current lane] dashed line, solid line, road edge, bott's dot, etc.";
BA_ "Version" SG_ 676 FR_CMR_Ln_ClfctRt01Sta "18.03.01";
BA_ "UserSigValidity" SG_ 676 FR_CMR_Ln_LftClr01Sta 3;
BA_ "Description" SG_ 676 FR_CMR_Ln_LftClr01Sta "[Color of the left-side line on current lane] unknown, white, yellow, blue, etc.";
BA_ "Version" SG_ 676 FR_CMR_Ln_LftClr01Sta "18.03.01";
BA_ "UserSigValidity" SG_ 676 FR_CMR_Ln_RtClr01Sta 3;
BA_ "Description" SG_ 676 FR_CMR_Ln_RtClr01Sta "[Color of the right-side line on current lane] unknown, white, yellow, blue, etc.";
BA_ "Version" SG_ 676 FR_CMR_Ln_RtClr01Sta "18.03.01";
BA_ "UserSigValidity" SG_ 676 FR_CMR_Ln_QualLvlLft01Sta 3;
BA_ "Description" SG_ 676 FR_CMR_Ln_QualLvlLft01Sta "Quality level of current lane [Left] ";
BA_ "Version" SG_ 676 FR_CMR_Ln_QualLvlLft01Sta "18.03.01";
BA_ "UserSigValidity" SG_ 676 FR_CMR_Ln_QualLvlRt01Sta 3;
BA_ "Description" SG_ 676 FR_CMR_Ln_QualLvlRt01Sta "Quality level of current lane [Right]";
BA_ "Version" SG_ 676 FR_CMR_Ln_QualLvlRt01Sta "18.03.01";
BA_ "UserSigValidity" SG_ 676 FR_CMR_Ln_ClfctLft02Sta 3;
BA_ "Description" SG_ 676 FR_CMR_Ln_ClfctLft02Sta "[Type of the line on next lane] dashed line, solid line, road edge, bott's dot, etc.";
BA_ "Version" SG_ 676 FR_CMR_Ln_ClfctLft02Sta "18.03.01";
BA_ "UserSigValidity" SG_ 676 FR_CMR_Ln_ClfctRt02Sta 3;
BA_ "Description" SG_ 676 FR_CMR_Ln_ClfctRt02Sta "[Type of the line on next lane] dashed line, solid line, road edge, bott's dot, etc.";
BA_ "Version" SG_ 676 FR_CMR_Ln_ClfctRt02Sta "18.03.01";
BA_ "UserSigValidity" SG_ 676 FR_CMR_Ln_QualLvlLft02Sta 3;
BA_ "Description" SG_ 676 FR_CMR_Ln_QualLvlLft02Sta "Quality level of next lane [Left]";
BA_ "Version" SG_ 676 FR_CMR_Ln_QualLvlLft02Sta "18.03.01";
BA_ "UserSigValidity" SG_ 676 FR_CMR_Ln_QualLvlRt02Sta 3;
BA_ "Description" SG_ 676 FR_CMR_Ln_QualLvlRt02Sta "Quality level of next lane [Right] ";
BA_ "Version" SG_ 676 FR_CMR_Ln_QualLvlRt02Sta "18.03.01";
BA_ "UserSigValidity" SG_ 676 FR_CMR_Ln_LftViewRngVal 3;
BA_ "Description" SG_ 676 FR_CMR_Ln_LftViewRngVal "physical view range of left lane mark";
BA_ "Version" SG_ 676 FR_CMR_Ln_LftViewRngVal "18.03.01";
BA_ "UserSigValidity" SG_ 676 FR_CMR_Ln_RtViewRngVal 3;
BA_ "Description" SG_ 676 FR_CMR_Ln_RtViewRngVal "physical view range of right lane mark";
BA_ "Version" SG_ 676 FR_CMR_Ln_RtViewRngVal "18.03.01";
BA_ "UserSigValidity" SG_ 698 FR_CMR_Crc4Val 3;
BA_ "GenSigStartValue" SG_ 698 FR_CMR_Crc4Val 65535;
BA_ "Description" SG_ 698 FR_CMR_Crc4Val "The CRC checking process calculates the CRC over the entire data block, including the CRC result.

- CRC Polynomial (0x1021) , Initial Value : 0xFFFF, XOR value : 0x0000

- The mathematical expression to 16 bit CRC polynomial is given here. G(x) = x16 + ";
BA_ "Version" SG_ 698 FR_CMR_Crc4Val "17.11.00";
BA_ "UserSigValidity" SG_ 698 FR_CMR_AlvCnt4Val 3;
BA_ "Description" SG_ 698 FR_CMR_AlvCnt4Val "For the first transmission request for a data element the counter shall be initialized with 0 and shall be incremented by 1

for every subsequent send request. When the counter reaches the maximum value(0xFF), then it shall restart with – for the next ";
BA_ "Version" SG_ 698 FR_CMR_AlvCnt4Val "17.11.00";
BA_ "UserSigValidity" SG_ 698 IFSref_FR_CMR_Sta 3;
BA_ "Description" SG_ 698 IFSref_FR_CMR_Sta "This is IFS system status needed for operate the IFS function of headlamp highbeam";
BA_ "Version" SG_ 698 IFSref_FR_CMR_Sta "18.05.02";
BA_ "UserSigValidity" SG_ 698 IFSref_VehNumVal 3;
BA_ "Description" SG_ 698 IFSref_VehNumVal "This is number of vehicles detected from camera";
BA_ "Version" SG_ 698 IFSref_VehNumVal "18.05.02";
BA_ "UserSigValidity" SG_ 698 IFSref_ILLAmbtSta 3;
BA_ "Description" SG_ 698 IFSref_ILLAmbtSta "This signal is status of the ambient brightness

0x0 is bright condition (HighBeam off), 0x1 is dark condition (None)";
BA_ "Version" SG_ 698 IFSref_ILLAmbtSta "17.11.00";
BA_ "UserSigValidity" SG_ 698 IFSref_VehLftAngl1Val 3;
BA_ "Description" SG_ 698 IFSref_VehLftAngl1Val "This is left angle of vehicle 1



Deg = (HEX)*0.1-25";
BA_ "Version" SG_ 698 IFSref_VehLftAngl1Val "18.02.03";
BA_ "UserSigValidity" SG_ 698 IFSref_VehRtAngl1Val 3;
BA_ "Description" SG_ 698 IFSref_VehRtAngl1Val "This is right angle of vehicle 1



Deg = (HEX)*0.1-25";
BA_ "Version" SG_ 698 IFSref_VehRtAngl1Val "18.02.03";
BA_ "UserSigValidity" SG_ 698 IFSref_VehLftAngl2Val 3;
BA_ "Description" SG_ 698 IFSref_VehLftAngl2Val "This is left angle of vehicle 2



Deg = (HEX)*0.1-25";
BA_ "Version" SG_ 698 IFSref_VehLftAngl2Val "18.02.03";
BA_ "UserSigValidity" SG_ 698 IFSref_VehDst1Val 3;
BA_ "Description" SG_ 698 IFSref_VehDst1Val "IFSref_VehicleDistance1Value";
BA_ "Version" SG_ 698 IFSref_VehDst1Val "18.05.01";
BA_ "UserSigValidity" SG_ 698 IFSref_VehRtAngl2Val 3;
BA_ "Description" SG_ 698 IFSref_VehRtAngl2Val "This is right angle of vehicle 2



Deg = (HEX)*0.1-25";
BA_ "Version" SG_ 698 IFSref_VehRtAngl2Val "18.02.03";
BA_ "UserSigValidity" SG_ 698 IFSref_VehLftAngl3Val 3;
BA_ "Description" SG_ 698 IFSref_VehLftAngl3Val "This is left angle of vehicle 3



Deg = (HEX)*0.1-25";
BA_ "Version" SG_ 698 IFSref_VehLftAngl3Val "18.02.03";
BA_ "UserSigValidity" SG_ 698 IFSref_VehRtAngl3Val 3;
BA_ "Description" SG_ 698 IFSref_VehRtAngl3Val "This is right angle of vehicle 3



Deg = (HEX)*0.1-25";
BA_ "Version" SG_ 698 IFSref_VehRtAngl3Val "18.02.03";
BA_ "UserSigValidity" SG_ 698 IFSref_VehLftAngl4Val 3;
BA_ "Description" SG_ 698 IFSref_VehLftAngl4Val "This is left angle of vehicle 4



Deg = (HEX)*0.1-25";
BA_ "Version" SG_ 698 IFSref_VehLftAngl4Val "18.02.03";
BA_ "UserSigValidity" SG_ 698 IFSref_VehRtAngl4Val 3;
BA_ "Description" SG_ 698 IFSref_VehRtAngl4Val "This is right angle of vehicle 4



Deg = (HEX)*0.1-25";
BA_ "Version" SG_ 698 IFSref_VehRtAngl4Val "18.02.03";
BA_ "UserSigValidity" SG_ 698 IFSref_VehLftAngl5Val 3;
BA_ "Description" SG_ 698 IFSref_VehLftAngl5Val "This is left angle of vehicle 5



Deg = (HEX)*0.1-25";
BA_ "Version" SG_ 698 IFSref_VehLftAngl5Val "18.02.03";
BA_ "UserSigValidity" SG_ 698 IFSref_VehRtAngl5Val 3;
BA_ "Description" SG_ 698 IFSref_VehRtAngl5Val "This is right angle of vehicle 5



Deg = (HEX)*0.1-25";
BA_ "Version" SG_ 698 IFSref_VehRtAngl5Val "18.02.03";
BA_ "UserSigValidity" SG_ 698 IFSref_VehLftAngl6Val 3;
BA_ "Description" SG_ 698 IFSref_VehLftAngl6Val "This is left angle of vehicle 6



Deg = (HEX)*0.1-25";
BA_ "Version" SG_ 698 IFSref_VehLftAngl6Val "18.02.03";
BA_ "UserSigValidity" SG_ 698 IFSref_VehRtAngl6Val 3;
BA_ "Description" SG_ 698 IFSref_VehRtAngl6Val "This is right angle of vehicle 6



Deg = (HEX)*0.1-25";
BA_ "Version" SG_ 698 IFSref_VehRtAngl6Val "18.02.03";
BA_ "UserSigValidity" SG_ 698 IFSref_VehLftAngl7Val 3;
BA_ "Description" SG_ 698 IFSref_VehLftAngl7Val "This is left angle of vehicle 7



Deg = (HEX)*0.1-25";
BA_ "Version" SG_ 698 IFSref_VehLftAngl7Val "18.02.03";
BA_ "UserSigValidity" SG_ 698 IFSref_VehRtAngl7Val 3;
BA_ "Description" SG_ 698 IFSref_VehRtAngl7Val "This is right angle of vehicle 7



Deg = (HEX)*0.1-25";
BA_ "Version" SG_ 698 IFSref_VehRtAngl7Val "18.02.03";
BA_ "UserSigValidity" SG_ 698 IFSref_VehLftAngl8Val 3;
BA_ "Description" SG_ 698 IFSref_VehLftAngl8Val "This is left angle of vehicle 8



Deg = (HEX)*0.1-25";
BA_ "Version" SG_ 698 IFSref_VehLftAngl8Val "18.02.03";
BA_ "UserSigValidity" SG_ 698 IFSref_VehRtAngl8Val 3;
BA_ "Description" SG_ 698 IFSref_VehRtAngl8Val "This is right angle of vehicle 8



Deg = (HEX)*0.1-25";
BA_ "Version" SG_ 698 IFSref_VehRtAngl8Val "18.02.03";
BA_ "UserSigValidity" SG_ 698 IFSref_VehLftAngl9Val 3;
BA_ "Description" SG_ 698 IFSref_VehLftAngl9Val "This is left angle of vehicle 9



Deg = (HEX)*0.1-25";
BA_ "Version" SG_ 698 IFSref_VehLftAngl9Val "18.05.01";
BA_ "UserSigValidity" SG_ 698 IFSref_VehRtAngl9Val 3;
BA_ "Description" SG_ 698 IFSref_VehRtAngl9Val "This is right angle of vehicle 9



Deg = (HEX)*0.1-25";
BA_ "Version" SG_ 698 IFSref_VehRtAngl9Val "18.05.01";
BA_ "UserSigValidity" SG_ 698 IFSref_VehLftAngl10Val 3;
BA_ "Description" SG_ 698 IFSref_VehLftAngl10Val "This is left angle of vehicle 10



Deg = (HEX)*0.1-25";
BA_ "Version" SG_ 698 IFSref_VehLftAngl10Val "18.05.01";
BA_ "UserSigValidity" SG_ 698 IFSref_VehRtAngl10Val 3;
BA_ "Description" SG_ 698 IFSref_VehRtAngl10Val "This is right angle of vehicle 10



Deg = (HEX)*0.1-25";
BA_ "Version" SG_ 698 IFSref_VehRtAngl10Val "18.05.01";
BA_ "UserSigValidity" SG_ 698 IFSref_VehDst2Val 3;
BA_ "Description" SG_ 698 IFSref_VehDst2Val "IFSref_VehicleDistance2Value";
BA_ "Version" SG_ 698 IFSref_VehDst2Val "18.05.01";
BA_ "UserSigValidity" SG_ 698 IFSref_VehDst3Val 3;
BA_ "Description" SG_ 698 IFSref_VehDst3Val "IFSref_VehicleDistance3Value";
BA_ "Version" SG_ 698 IFSref_VehDst3Val "18.05.01";
BA_ "UserSigValidity" SG_ 698 IFSref_VehDst4Val 3;
BA_ "Description" SG_ 698 IFSref_VehDst4Val "IFSref_VehicleDistance4Value";
BA_ "Version" SG_ 698 IFSref_VehDst4Val "18.05.01";
BA_ "UserSigValidity" SG_ 698 IFSref_VehDst5Val 3;
BA_ "Description" SG_ 698 IFSref_VehDst5Val "IFSref_VehicleDistance5Value";
BA_ "Version" SG_ 698 IFSref_VehDst5Val "18.05.01";
BA_ "UserSigValidity" SG_ 698 IFSref_VehDst6Val 3;
BA_ "Description" SG_ 698 IFSref_VehDst6Val "IFSref_VehicleDistance6Value";
BA_ "Version" SG_ 698 IFSref_VehDst6Val "18.05.01";
BA_ "UserSigValidity" SG_ 698 IFSref_VehDst7Val 3;
BA_ "Description" SG_ 698 IFSref_VehDst7Val "IFSref_VehicleDistance7Value";
BA_ "Version" SG_ 698 IFSref_VehDst7Val "18.05.01";
BA_ "UserSigValidity" SG_ 698 IFSref_VehDst8Val 3;
BA_ "Description" SG_ 698 IFSref_VehDst8Val "IFSref_VehicleDistance8Value";
BA_ "Version" SG_ 698 IFSref_VehDst8Val "18.05.01";
BA_ "UserSigValidity" SG_ 698 IFSref_VehDst9Val 3;
BA_ "Description" SG_ 698 IFSref_VehDst9Val "IFSref_VehicleDistance9Value";
BA_ "Version" SG_ 698 IFSref_VehDst9Val "18.05.01";
BA_ "UserSigValidity" SG_ 698 IFSref_VehDst10Val 3;
BA_ "Description" SG_ 698 IFSref_VehDst10Val "IFSref_VehicleDistance10Value";
BA_ "Version" SG_ 698 IFSref_VehDst10Val "18.05.01";
BA_ "UserSigValidity" SG_ 720 TCU_Crc3Val 3;
BA_ "GenSigStartValue" SG_ 720 TCU_Crc3Val 65535;
BA_ "RoutingFactor" SG_ 720 TCU_Crc3Val 2;
BA_ "Description" SG_ 720 TCU_Crc3Val "The CRC checking process calculates the CRC over the entire data block, including the CRC result.

- CRC Polynomial (0x1021) , Initial Value : 0xFFFF, XOR value : 0x0000

- The mathematical expression to 16 bit CRC polynomial is given here. G(x) = x16 + ";
BA_ "Version" SG_ 720 TCU_Crc3Val "17.11.00";
BA_ "UserSigValidity" SG_ 720 TCU_AlvCnt3Val 3;
BA_ "RoutingFactor" SG_ 720 TCU_AlvCnt3Val 2;
BA_ "Description" SG_ 720 TCU_AlvCnt3Val "For the first transmission request for a data element the counter shall be initialized with 0 and shall be incremented by 1

for every subsequent send request. When the counter reaches the maximum value(0xFF), then it shall restart with – for the next ";
BA_ "Version" SG_ 720 TCU_AlvCnt3Val "17.11.00";
BA_ "UserSigValidity" SG_ 720 TCU_WrngMsgSta 3;
BA_ "RoutingFactor" SG_ 720 TCU_WrngMsgSta 2;
BA_ "Description" SG_ 720 TCU_WrngMsgSta "This signal indicates the status of “TCU Warning message”";
BA_ "Version" SG_ 720 TCU_WrngMsgSta "17.11.00";
BA_ "UserSigValidity" SG_ 832 HEV_OBD_EngRpmVal 3;
BA_ "RoutingFactor" SG_ 832 HEV_OBD_EngRpmVal 2;
BA_ "Description" SG_ 832 HEV_OBD_EngRpmVal "PID_0CH : Parameter ID for CARB OBD regulation - SAE J1979 Service Mode 02

This signal indicates engine speed (RPM-Revolution per Min.) and compatible with signal “N” in EMS1 message.";
BA_ "Version" SG_ 832 HEV_OBD_EngRpmVal "18.05.04";
BA_ "UserSigValidity" SG_ 934 PTGM_SpeedRValue 0;
BA_ "Description" SG_ 934 PTGM_SpeedRValue "PTG Speed USM Setting Signal";
BA_ "Version" SG_ 934 PTGM_SpeedRValue "18.02.03";
BA_ "UserSigValidity" SG_ 934 PTGM_SpeedSetWarn 0;
BA_ "Description" SG_ 934 PTGM_SpeedSetWarn "PTG Speed USM Setting Warning Message Popup";
BA_ "Version" SG_ 934 PTGM_SpeedSetWarn "18.02.03";
BA_ "UserSigValidity" SG_ 934 PTGM_HeightRValue 0;
BA_ "Description" SG_ 934 PTGM_HeightRValue "PTG Opening Height USM Setting Signal";
BA_ "Version" SG_ 934 PTGM_HeightRValue "18.02.03";
BA_ "UserSigValidity" SG_ 934 PTGM_OpnClsState 0;
BA_ "Description" SG_ 934 PTGM_OpnClsState "This signal indicates PTGM Open/Close Status";
BA_ "Version" SG_ 934 PTGM_OpnClsState "18.02.03";
BA_ "UserSigValidity" SG_ 934 PTGM_CmdWarn 3;
BA_ "Description" SG_ 934 PTGM_CmdWarn "This signal indicates PTGM Warning Status";
BA_ "Version" SG_ 934 PTGM_CmdWarn "18.02.03";
BA_ "UserSigValidity" SG_ 934 PTGM_AntiPinchSnsr 0;
BA_ "Description" SG_ 934 PTGM_AntiPinchSnsr "This signal indicates Anti-Pinch Sensor Applied Status";
BA_ "Version" SG_ 934 PTGM_AntiPinchSnsr "18.02.03";
BA_ "UserSigValidity" SG_ 961 MFSW_Crc1Val 0;
BA_ "GenSigStartValue" SG_ 961 MFSW_Crc1Val 255;
BA_ "Description" SG_ 961 MFSW_Crc1Val "The CRC checking process calculates the CRC over the entire data block, including the CRC result CRC Polynomial (0x1D) ,

Initial Value : 0x00, XOR value : 0x00

The mathematical expression to 8 bit CRC polynomial is given here. G(x) = x8 + x4 + x3 + x2 ";
BA_ "Version" SG_ 961 MFSW_Crc1Val "17.12.08";
BA_ "UserSigValidity" SG_ 961 MFSW_AlvCnt1Val 0;
BA_ "Description" SG_ 961 MFSW_AlvCnt1Val "For the first transmission request for a data element the counter shall be initialized with 0 and shall be incremented by 1

for every subsequent send request. When the counter reaches the maximum value(0xE), then it shall restart with – for the next s";
BA_ "Version" SG_ 961 MFSW_AlvCnt1Val "17.12.08";
BA_ "UserSigValidity" SG_ 961 Lamp_HdLmpHiSwSta 0;
BA_ "NetworkRequestHoldingTime" SG_ 961 Lamp_HdLmpHiSwSta 5000;
BA_ "Version" SG_ 961 Lamp_HdLmpHiSwSta "17.12.08";
BA_ "UserSigValidity" SG_ 961 Lamp_LtSwSta 0;
BA_ "NetworkRequestHoldingTime" SG_ 961 Lamp_LtSwSta 5000;
BA_ "Version" SG_ 961 Lamp_LtSwSta "17.12.08";
BA_ "UserSigValidity" SG_ 961 Lamp_OneTouchTrnSigLftSwSta 0;
BA_ "NetworkRequestHoldingTime" SG_ 961 Lamp_OneTouchTrnSigLftSwSta 5000;
BA_ "Description" SG_ 961 Lamp_OneTouchTrnSigLftSwSta "ONE TOUCH TURN SIGNAL FOR LH";
BA_ "Version" SG_ 961 Lamp_OneTouchTrnSigLftSwSta "17.12.08";
BA_ "UserSigValidity" SG_ 961 Lamp_OneTouchTrnSigRtSwSta 0;
BA_ "NetworkRequestHoldingTime" SG_ 961 Lamp_OneTouchTrnSigRtSwSta 5000;
BA_ "Description" SG_ 961 Lamp_OneTouchTrnSigRtSwSta "ONE TOUCH TURN SIGNAL FOR RH";
BA_ "Version" SG_ 961 Lamp_OneTouchTrnSigRtSwSta "17.12.08";
BA_ "UserSigValidity" SG_ 961 Lamp_PassingLmpSwSta 0;
BA_ "NetworkRequestHoldingTime" SG_ 961 Lamp_PassingLmpSwSta 5000;
BA_ "Version" SG_ 961 Lamp_PassingLmpSwSta "17.12.08";
BA_ "UserSigValidity" SG_ 961 Lamp_TrnSigLftSwSta 0;
BA_ "NetworkRequestHoldingTime" SG_ 961 Lamp_TrnSigLftSwSta 5000;
BA_ "Version" SG_ 961 Lamp_TrnSigLftSwSta "17.12.08";
BA_ "UserSigValidity" SG_ 961 Lamp_TrnSigRtSwSta 0;
BA_ "NetworkRequestHoldingTime" SG_ 961 Lamp_TrnSigRtSwSta 5000;
BA_ "Version" SG_ 961 Lamp_TrnSigRtSwSta "17.12.08";
BA_ "UserSigValidity" SG_ 961 Lamp_LaneChgTrnSigLftSwSta 0;
BA_ "NetworkRequestHoldingTime" SG_ 961 Lamp_LaneChgTrnSigLftSwSta 5000;
BA_ "Description" SG_ 961 Lamp_LaneChgTrnSigLftSwSta "LANE CHANGE TURN SIGNAL FOR LH";
BA_ "Version" SG_ 961 Lamp_LaneChgTrnSigLftSwSta "18.01.00";
BA_ "UserSigValidity" SG_ 961 Lamp_LaneChgTrnSigRtSwSta 0;
BA_ "NetworkRequestHoldingTime" SG_ 961 Lamp_LaneChgTrnSigRtSwSta 5000;
BA_ "Description" SG_ 961 Lamp_LaneChgTrnSigRtSwSta "LANE CHANGE TURN SIGNAL FOR RH";
BA_ "Version" SG_ 961 Lamp_LaneChgTrnSigRtSwSta "18.01.00";
BA_ "UserSigValidity" SG_ 962 MFSW_Crc2Val 0;
BA_ "GenSigStartValue" SG_ 962 MFSW_Crc2Val 255;
BA_ "Description" SG_ 962 MFSW_Crc2Val "The CRC checking process calculates the CRC over the entire data block, including the CRC result CRC Polynomial (0x1D) ,

Initial Value : 0x00, XOR value : 0x00

The mathematical expression to 8 bit CRC polynomial is given here. G(x) = x8 + x4 + x3 + x2 ";
BA_ "Version" SG_ 962 MFSW_Crc2Val "17.12.08";
BA_ "UserSigValidity" SG_ 962 MFSW_AlvCnt2Val 0;
BA_ "Description" SG_ 962 MFSW_AlvCnt2Val "For the first transmission request for a data element the counter shall be initialized with 0 and shall be incremented by 1

for every subsequent send request. When the counter reaches the maximum value(0xE), then it shall restart with – for the next s";
BA_ "Version" SG_ 962 MFSW_AlvCnt2Val "17.12.08";
BA_ "UserSigValidity" SG_ 962 Wiper_FrWiperSwSta 0;
BA_ "NetworkRequestHoldingTime" SG_ 962 Wiper_FrWiperSwSta 5000;
BA_ "Description" SG_ 962 Wiper_FrWiperSwSta "Multifuction Front Wiper Switch Status



The value '0x1' means 'Int Sw On' or 'Auto Sw on' and its status determined by 'C_RainSnsOption' signal



0x1 : Wiper Int Sw on (C_RainSnsOption = 0x0)



0x1 : Wiper Auto Sw on (C_RainSnsOption = 0x1)";
BA_ "Version" SG_ 962 Wiper_FrWiperSwSta "17.12.08";
BA_ "UserSigValidity" SG_ 962 Wiper_IntStepSta 0;
BA_ "NetworkRequestHoldingTime" SG_ 962 Wiper_IntStepSta 5000;
BA_ "Version" SG_ 962 Wiper_IntStepSta "17.12.08";
BA_ "UserSigValidity" SG_ 1035 ExtLamp_IRLmpLftFlSta 0;
BA_ "NetworkRequestHoldingTime" SG_ 1035 ExtLamp_IRLmpLftFlSta 5000;
BA_ "Description" SG_ 1035 ExtLamp_IRLmpLftFlSta "-(Old)C_FSJB_IRLpLeftFail";
BA_ "Version" SG_ 1035 ExtLamp_IRLmpLftFlSta "17.11.00";
BA_ "UserSigValidity" SG_ 1035 ExtLamp_IRLmpRtFlSta 0;
BA_ "NetworkRequestHoldingTime" SG_ 1035 ExtLamp_IRLmpRtFlSta 5000;
BA_ "Description" SG_ 1035 ExtLamp_IRLmpRtFlSta "-(Old)C_FSJB_IRLpRightFail";
BA_ "Version" SG_ 1035 ExtLamp_IRLmpRtFlSta "17.11.00";
BA_ "UserSigValidity" SG_ 1041 ICU_Crc2Val 0;
BA_ "GenSigStartValue" SG_ 1041 ICU_Crc2Val 255;
BA_ "Description" SG_ 1041 ICU_Crc2Val "The CRC checking process calculates the CRC over the entire data block, including the CRC result CRC Polynomial (0x1D) ,

Initial Value : 0x00, XOR value : 0x00

The mathematical expression to 8 bit CRC polynomial is given here. G(x) = x8 + x4 + x3 + x2 ";
BA_ "Version" SG_ 1041 ICU_Crc2Val "17.11.00";
BA_ "UserSigValidity" SG_ 1041 ICU_AlvCnt2Val 0;
BA_ "Description" SG_ 1041 ICU_AlvCnt2Val "For the first transmission request for a data element the counter shall be initialized with 0 and shall be incremented by 1

for every subsequent send request. When the counter reaches the maximum value(0xE), then it shall restart with – for the next s";
BA_ "Version" SG_ 1041 ICU_AlvCnt2Val "17.11.00";
BA_ "UserSigValidity" SG_ 1041 Warn_DrvDrSwSta 0;
BA_ "NetworkRequestHoldingTime" SG_ 1041 Warn_DrvDrSwSta 5000;
BA_ "Version" SG_ 1041 Warn_DrvDrSwSta "17.12.00";
BA_ "UserSigValidity" SG_ 1041 Warn_AsstDrSwSta 0;
BA_ "NetworkRequestHoldingTime" SG_ 1041 Warn_AsstDrSwSta 5000;
BA_ "Version" SG_ 1041 Warn_AsstDrSwSta "17.12.00";
BA_ "UserSigValidity" SG_ 1041 Warn_DrvStBltSwSta 0;
BA_ "NetworkRequestHoldingTime" SG_ 1041 Warn_DrvStBltSwSta 5000;
BA_ "Version" SG_ 1041 Warn_DrvStBltSwSta "17.12.00";
BA_ "UserSigValidity" SG_ 1041 Warn_RrLftDrSwSta 0;
BA_ "NetworkRequestHoldingTime" SG_ 1041 Warn_RrLftDrSwSta 5000;
BA_ "Version" SG_ 1041 Warn_RrLftDrSwSta "17.12.00";
BA_ "UserSigValidity" SG_ 1041 Warn_RrRtDrSwSta 0;
BA_ "NetworkRequestHoldingTime" SG_ 1041 Warn_RrRtDrSwSta 5000;
BA_ "Version" SG_ 1041 Warn_RrRtDrSwSta "17.12.00";
BA_ "UserSigValidity" SG_ 1043 ICU_Crc4Val 0;
BA_ "GenSigStartValue" SG_ 1043 ICU_Crc4Val 255;
BA_ "Description" SG_ 1043 ICU_Crc4Val "The CRC checking process calculates the CRC over the entire data block, including the CRC result CRC Polynomial (0x1D) ,

Initial Value : 0x00, XOR value : 0x00

The mathematical expression to 8 bit CRC polynomial is given here. G(x) = x8 + x4 + x3 + x2 ";
BA_ "Version" SG_ 1043 ICU_Crc4Val "17.11.00";
BA_ "UserSigValidity" SG_ 1043 ICU_AlvCnt4Val 0;
BA_ "Description" SG_ 1043 ICU_AlvCnt4Val "For the first transmission request for a data element the counter shall be initialized with 0 and shall be incremented by 1

for every subsequent send request. When the counter reaches the maximum value(0xE), then it shall restart with – for the next s";
BA_ "Version" SG_ 1043 ICU_AlvCnt4Val "17.11.00";
BA_ "UserSigValidity" SG_ 1043 ExtLamp_FrFgLmpSta 0;
BA_ "NetworkRequestHoldingTime" SG_ 1043 ExtLamp_FrFgLmpSta 5000;
BA_ "Version" SG_ 1043 ExtLamp_FrFgLmpSta "17.12.00";
BA_ "UserSigValidity" SG_ 1043 ExtLamp_TrnSigLmpLftBlnkngSta 0;
BA_ "NetworkRequestHoldingTime" SG_ 1043 ExtLamp_TrnSigLmpLftBlnkngSta 5000;
BA_ "Version" SG_ 1043 ExtLamp_TrnSigLmpLftBlnkngSta "17.12.00";
BA_ "UserSigValidity" SG_ 1043 ExtLamp_TrnSigLmpRtBlnkngSta 0;
BA_ "NetworkRequestHoldingTime" SG_ 1043 ExtLamp_TrnSigLmpRtBlnkngSta 5000;
BA_ "Version" SG_ 1043 ExtLamp_TrnSigLmpRtBlnkngSta "17.12.00";
BA_ "UserSigValidity" SG_ 1043 ExtLamp_ExtrnlTailLmpSta 0;
BA_ "NetworkRequestHoldingTime" SG_ 1043 ExtLamp_ExtrnlTailLmpSta 5000;
BA_ "Description" SG_ 1043 ExtLamp_ExtrnlTailLmpSta "-(Old)C_EXTTail_Act";
BA_ "Version" SG_ 1043 ExtLamp_ExtrnlTailLmpSta "17.12.00";
BA_ "UserSigValidity" SG_ 1043 ExtLamp_HzrdSwSta 0;
BA_ "NetworkRequestHoldingTime" SG_ 1043 ExtLamp_HzrdSwSta 5000;
BA_ "Version" SG_ 1043 ExtLamp_HzrdSwSta "17.12.00";
BA_ "UserSigValidity" SG_ 1044 C_CrashUnlockState 0;
BA_ "Description" SG_ 1044 C_CrashUnlockState "Crash Unlock Active State

-0x0:Off

-0x1:Unlock(crash)

";
BA_ "Version" SG_ 1044 C_CrashUnlockState "18.05.02";
BA_ "UserSigValidity" SG_ 1050 BCM_Crc7Val 0;
BA_ "GenSigStartValue" SG_ 1050 BCM_Crc7Val 255;
BA_ "Description" SG_ 1050 BCM_Crc7Val "The CRC checking process calculates the CRC over the entire data block, including the CRC result CRC Polynomial (0x1D) ,

Initial Value : 0x00, XOR value : 0x00

The mathematical expression to 8 bit CRC polynomial is given here. G(x) = x8 + x4 + x3 + x2 ";
BA_ "Version" SG_ 1050 BCM_Crc7Val "17.11.00";
BA_ "UserSigValidity" SG_ 1050 BCM_AlvCnt7Val 0;
BA_ "Description" SG_ 1050 BCM_AlvCnt7Val "For the first transmission request for a data element the counter shall be initialized with 0 and shall be incremented by 1

for every subsequent send request. When the counter reaches the maximum value(0xE), then it shall restart with – for the next s";
BA_ "Version" SG_ 1050 BCM_AlvCnt7Val "17.11.00";
BA_ "UserSigValidity" SG_ 1050 Lamp_ExtrnlTailLmpOnReq 0;
BA_ "NetworkRequestHoldingTime" SG_ 1050 Lamp_ExtrnlTailLmpOnReq 5000;
BA_ "Description" SG_ 1050 Lamp_ExtrnlTailLmpOnReq "-(Old)C_EXTTailOn";
BA_ "Version" SG_ 1050 Lamp_ExtrnlTailLmpOnReq "17.12.00";
BA_ "UserSigValidity" SG_ 1050 Lamp_HdLmpLoOnReq 0;
BA_ "NetworkRequestHoldingTime" SG_ 1050 Lamp_HdLmpLoOnReq 5000;
BA_ "Description" SG_ 1050 Lamp_HdLmpLoOnReq "-(Old)C_HLampLowON";
BA_ "Version" SG_ 1050 Lamp_HdLmpLoOnReq "17.12.00";
BA_ "UserSigValidity" SG_ 1050 Lamp_HdLmpHiOnReq 0;
BA_ "NetworkRequestHoldingTime" SG_ 1050 Lamp_HdLmpHiOnReq 5000;
BA_ "Description" SG_ 1050 Lamp_HdLmpHiOnReq "-(Old)C_HLampHighON";
BA_ "Version" SG_ 1050 Lamp_HdLmpHiOnReq "17.12.00";
BA_ "UserSigValidity" SG_ 1050 Lamp_PassingLmpOnReq 0;
BA_ "NetworkRequestHoldingTime" SG_ 1050 Lamp_PassingLmpOnReq 5000;
BA_ "Description" SG_ 1050 Lamp_PassingLmpOnReq "-Lamp on command for passing lamp dedicated from headlamp";
BA_ "Version" SG_ 1050 Lamp_PassingLmpOnReq "17.12.00";
BA_ "UserSigValidity" SG_ 1051 BCM_Crc8Val 0;
BA_ "GenSigStartValue" SG_ 1051 BCM_Crc8Val 255;
BA_ "Description" SG_ 1051 BCM_Crc8Val "The CRC checking process calculates the CRC over the entire data block, including the CRC result CRC Polynomial (0x1D) ,

Initial Value : 0x00, XOR value : 0x00

The mathematical expression to 8 bit CRC polynomial is given here. G(x) = x8 + x4 + x3 + x2 ";
BA_ "Version" SG_ 1051 BCM_Crc8Val "17.11.00";
BA_ "UserSigValidity" SG_ 1051 BCM_AlvCnt8Val 0;
BA_ "Description" SG_ 1051 BCM_AlvCnt8Val "For the first transmission request for a data element the counter shall be initialized with 0 and shall be incremented by 1

for every subsequent send request. When the counter reaches the maximum value(0xE), then it shall restart with – for the next s";
BA_ "Version" SG_ 1051 BCM_AlvCnt8Val "17.11.00";
BA_ "UserSigValidity" SG_ 1051 Lamp_HbaCtrlModTyp 0;
BA_ "NetworkRequestHoldingTime" SG_ 1051 Lamp_HbaCtrlModTyp 5000;
BA_ "Description" SG_ 1051 Lamp_HbaCtrlModTyp "This signal headlamp high control by BCM or HBA";
BA_ "Version" SG_ 1051 Lamp_HbaCtrlModTyp "17.12.00";
BA_ "UserSigValidity" SG_ 1052 Lamp_AutoLtSnsrNightSta 0;
BA_ "NetworkRequestHoldingTime" SG_ 1052 Lamp_AutoLtSnsrNightSta 5000;
BA_ "Description" SG_ 1052 Lamp_AutoLtSnsrNightSta "This signal indicates autolight sensor output ";
BA_ "Version" SG_ 1052 Lamp_AutoLtSnsrNightSta "17.12.00";
BA_ "UserSigValidity" SG_ 1057 ILCU_LH_Crc1Val 0;
BA_ "GenSigStartValue" SG_ 1057 ILCU_LH_Crc1Val 255;
BA_ "Description" SG_ 1057 ILCU_LH_Crc1Val "The CRC checking process calculates the CRC over the entire data block, including the CRC result CRC Polynomial (0x1D) ,

Initial Value : 0x00, XOR value : 0x00

The mathematical expression to 8 bit CRC polynomial is given here. G(x) = x8 + x4 + x3 + x2 ";
BA_ "Version" SG_ 1057 ILCU_LH_Crc1Val "17.12.02";
BA_ "UserSigValidity" SG_ 1057 ILCU_LH_AlvCnt1Val 0;
BA_ "Description" SG_ 1057 ILCU_LH_AlvCnt1Val "For the first transmission request for a data element the counter shall be initialized with 0 and shall be incremented by 1

for every subsequent send request. When the counter reaches the maximum value(0xE), then it shall restart with – for the next s";
BA_ "Version" SG_ 1057 ILCU_LH_AlvCnt1Val "17.12.02";
BA_ "UserSigValidity" SG_ 1057 ILCULH_LowBeamAct_Sta 0;
BA_ "NetworkRequestHoldingTime" SG_ 1057 ILCULH_LowBeamAct_Sta 5000;
BA_ "Version" SG_ 1057 ILCULH_LowBeamAct_Sta "17.12.02";
BA_ "UserSigValidity" SG_ 1057 ILCULH_HighBeamAct_Sta 3;
BA_ "NetworkRequestHoldingTime" SG_ 1057 ILCULH_HighBeamAct_Sta 5000;
BA_ "Version" SG_ 1057 ILCULH_HighBeamAct_Sta "17.12.02";
BA_ "UserSigValidity" SG_ 1057 ILCULH_FrontTurnAct_Sta 0;
BA_ "NetworkRequestHoldingTime" SG_ 1057 ILCULH_FrontTurnAct_Sta 5000;
BA_ "Version" SG_ 1057 ILCULH_FrontTurnAct_Sta "17.12.02";
BA_ "UserSigValidity" SG_ 1057 ILCULH_IFSLamp_Act 3;
BA_ "NetworkRequestHoldingTime" SG_ 1057 ILCULH_IFSLamp_Act 5000;
BA_ "Version" SG_ 1057 ILCULH_IFSLamp_Act "18.06.00";
BA_ "UserSigValidity" SG_ 1058 Wiper_PrkngPosSta 0;
BA_ "NetworkRequestHoldingTime" SG_ 1058 Wiper_PrkngPosSta 5000;
BA_ "Version" SG_ 1058 Wiper_PrkngPosSta "17.12.00";
BA_ "UserSigValidity" SG_ 1058 Wiper_RainSnsrSta 0;
BA_ "NetworkRequestHoldingTime" SG_ 1058 Wiper_RainSnsrSta 5000;
BA_ "Description" SG_ 1058 Wiper_RainSnsrSta "This signal represents the status of Rain Sensor signal state. ";
BA_ "Version" SG_ 1058 Wiper_RainSnsrSta "17.12.00";
BA_ "UserSigValidity" SG_ 1062 ILCU_RH_Crc1Val 0;
BA_ "GenSigStartValue" SG_ 1062 ILCU_RH_Crc1Val 255;
BA_ "Description" SG_ 1062 ILCU_RH_Crc1Val "The CRC checking process calculates the CRC over the entire data block, including the CRC result CRC Polynomial (0x1D) ,

Initial Value : 0x00, XOR value : 0x00

The mathematical expression to 8 bit CRC polynomial is given here. G(x) = x8 + x4 + x3 + x2 ";
BA_ "Version" SG_ 1062 ILCU_RH_Crc1Val "17.12.02";
BA_ "UserSigValidity" SG_ 1062 ILCU_RH_AlvCnt1Val 0;
BA_ "Description" SG_ 1062 ILCU_RH_AlvCnt1Val "For the first transmission request for a data element the counter shall be initialized with 0 and shall be incremented by 1

for every subsequent send request. When the counter reaches the maximum value(0xE), then it shall restart with – for the next s";
BA_ "Version" SG_ 1062 ILCU_RH_AlvCnt1Val "17.12.02";
BA_ "UserSigValidity" SG_ 1062 ILCURH_LowBeamAct_Sta 0;
BA_ "NetworkRequestHoldingTime" SG_ 1062 ILCURH_LowBeamAct_Sta 5000;
BA_ "Version" SG_ 1062 ILCURH_LowBeamAct_Sta "17.12.02";
BA_ "UserSigValidity" SG_ 1062 ILCURH_HighBeamAct_Sta 3;
BA_ "NetworkRequestHoldingTime" SG_ 1062 ILCURH_HighBeamAct_Sta 5000;
BA_ "Version" SG_ 1062 ILCURH_HighBeamAct_Sta "17.12.02";
BA_ "UserSigValidity" SG_ 1062 ILCURH_FrontTurnAct_Sta 0;
BA_ "NetworkRequestHoldingTime" SG_ 1062 ILCURH_FrontTurnAct_Sta 5000;
BA_ "Version" SG_ 1062 ILCURH_FrontTurnAct_Sta "17.12.02";
BA_ "UserSigValidity" SG_ 1062 ILCURH_IFSLamp_Act 3;
BA_ "NetworkRequestHoldingTime" SG_ 1062 ILCURH_IFSLamp_Act 5000;
BA_ "Version" SG_ 1062 ILCURH_IFSLamp_Act "18.06.00";
BA_ "UserSigValidity" SG_ 1076 IAU_ProfileIDRVal 0;
BA_ "NetworkRequestHoldingTime" SG_ 1076 IAU_ProfileIDRVal 5000;
BA_ "Version" SG_ 1076 IAU_ProfileIDRVal "17.12.08";
BA_ "UserSigValidity" SG_ 1092 SMK_Crc2Val 0;
BA_ "GenSigStartValue" SG_ 1092 SMK_Crc2Val 255;
BA_ "Description" SG_ 1092 SMK_Crc2Val "The CRC checking process calculates the CRC over the entire data block, including the CRC result CRC Polynomial (0x1D) ,

Initial Value : 0x00, XOR value : 0x00

The mathematical expression to 8 bit CRC polynomial is given here. G(x) = x8 + x4 + x3 + x2 ";
BA_ "Version" SG_ 1092 SMK_Crc2Val "17.11.00";
BA_ "UserSigValidity" SG_ 1092 SMK_AlvCnt2Val 0;
BA_ "Description" SG_ 1092 SMK_AlvCnt2Val "For the first transmission request for a data element the counter shall be initialized with 0 and shall be incremented by 1

for every subsequent send request. When the counter reaches the maximum value(0xE), then it shall restart with – for the next s";
BA_ "Version" SG_ 1092 SMK_AlvCnt2Val "17.11.00";
BA_ "UserSigValidity" SG_ 1092 SMK_TlEngRunSta 0;
BA_ "Version" SG_ 1092 SMK_TlEngRunSta "17.12.00";
BA_ "UserSigValidity" SG_ 1097 Lamp_ExtrnlTailLmpSta_BCM 0;
BA_ "NetworkRequestHoldingTime" SG_ 1097 Lamp_ExtrnlTailLmpSta_BCM 5000;
BA_ "Description" SG_ 1097 Lamp_ExtrnlTailLmpSta_BCM "-(Old)C_EXTTail_Act";
BA_ "Version" SG_ 1097 Lamp_ExtrnlTailLmpSta_BCM "17.12.00";
BA_ "UserSigValidity" SG_ 1097 Lamp_HzrdSwSta_BCM 0;
BA_ "NetworkRequestHoldingTime" SG_ 1097 Lamp_HzrdSwSta_BCM 5000;
BA_ "Version" SG_ 1097 Lamp_HzrdSwSta_BCM "17.12.00";
BA_ "UserSigValidity" SG_ 1098 Lamp_HdLmpHiSta_BCM 0;
BA_ "NetworkRequestHoldingTime" SG_ 1098 Lamp_HdLmpHiSta_BCM 5000;
BA_ "Description" SG_ 1098 Lamp_HdLmpHiSta_BCM "-(Old)C_HLampHIGH_Act";
BA_ "Version" SG_ 1098 Lamp_HdLmpHiSta_BCM "17.12.00";
BA_ "UserSigValidity" SG_ 1098 Lamp_HdLmpLoSta_BCM 0;
BA_ "NetworkRequestHoldingTime" SG_ 1098 Lamp_HdLmpLoSta_BCM 5000;
BA_ "Description" SG_ 1098 Lamp_HdLmpLoSta_BCM "-(Old)C_HLampLOW_Act";
BA_ "Version" SG_ 1098 Lamp_HdLmpLoSta_BCM "17.12.00";
BA_ "UserSigValidity" SG_ 1098 Lamp_FrFgLmpSta_BCM 0;
BA_ "NetworkRequestHoldingTime" SG_ 1098 Lamp_FrFgLmpSta_BCM 5000;
BA_ "Version" SG_ 1098 Lamp_FrFgLmpSta_BCM "17.12.00";
BA_ "UserSigValidity" SG_ 1135 CLU_Crc13Val 3;
BA_ "GenSigStartValue" SG_ 1135 CLU_Crc13Val 65535;
BA_ "Description" SG_ 1135 CLU_Crc13Val "The CRC checking process calculates the CRC over the entire data block, including the CRC result.

- CRC Polynomial (0x1021) , Initial Value : 0xFFFF, XOR value : 0x0000

- The mathematical expression to 16 bit CRC polynomial is given here. G(x) = x16 + ";
BA_ "Version" SG_ 1135 CLU_Crc13Val "17.12.03";
BA_ "UserSigValidity" SG_ 1135 CLU_AlvCnt13Val 3;
BA_ "Description" SG_ 1135 CLU_AlvCnt13Val "For the first transmission request for a data element the counter shall be initialized with 0 and shall be incremented by 1

for every subsequent send request. When the counter reaches the maximum value(0xFF), then it shall restart with – for the next ";
BA_ "Version" SG_ 1135 CLU_AlvCnt13Val "17.12.03";
BA_ "UserSigValidity" SG_ 1135 USM_AdasLkaModSetReq 3;
BA_ "Description" SG_ 1135 USM_AdasLkaModSetReq "This signal is used for a request to set the value of USM Menus. This signal requests to change status of LKA Mode.";
BA_ "Version" SG_ 1135 USM_AdasLkaModSetReq "17.12.03";
BA_ "UserSigValidity" SG_ 1135 USM_AdasFCAJnctnSetReq 3;
BA_ "Description" SG_ 1135 USM_AdasFCAJnctnSetReq "This signal is used for a request to set the value of USM Menus. This signal requests to change status of FCA Junction.";
BA_ "Version" SG_ 1135 USM_AdasFCAJnctnSetReq "18.02.00";
BA_ "UserSigValidity" SG_ 1135 USM_AdasHbaSetReq 3;
BA_ "Description" SG_ 1135 USM_AdasHbaSetReq "This signal is used for a request to set the value of USM Menus. ";
BA_ "Version" SG_ 1135 USM_AdasHbaSetReq "18.04.00";
BA_ "UserSigValidity" SG_ 1135 USM_AdasSCCMLSetReq 3;
BA_ "Description" SG_ 1135 USM_AdasSCCMLSetReq "This signal is used for a request to set the value of USM Menus. ";
BA_ "Version" SG_ 1135 USM_AdasSCCMLSetReq "18.05.02";
BA_ "UserSigValidity" SG_ 1135 USM_AdasSCCMLResetReq 3;
BA_ "Description" SG_ 1135 USM_AdasSCCMLResetReq "This signal is used for a request to reset of ADAS SCCML.";
BA_ "Version" SG_ 1135 USM_AdasSCCMLResetReq "18.05.02";
BA_ "UserSigValidity" SG_ 1145 CLU_Crc12Val 3;
BA_ "GenSigStartValue" SG_ 1145 CLU_Crc12Val 65535;
BA_ "Description" SG_ 1145 CLU_Crc12Val "The CRC checking process calculates the CRC over the entire data block, including the CRC result.

- CRC Polynomial (0x1021) , Initial Value : 0xFFFF, XOR value : 0x0000

- The mathematical expression to 16 bit CRC polynomial is given here. G(x) = x16 + ";
BA_ "Version" SG_ 1145 CLU_Crc12Val "17.12.03";
BA_ "UserSigValidity" SG_ 1145 CLU_AlvCnt12Val 3;
BA_ "Description" SG_ 1145 CLU_AlvCnt12Val "For the first transmission request for a data element the counter shall be initialized with 0 and shall be incremented by 1

for every subsequent send request. When the counter reaches the maximum value(0xFF), then it shall restart with – for the next ";
BA_ "Version" SG_ 1145 CLU_AlvCnt12Val "17.12.03";
BA_ "UserSigValidity" SG_ 1145 USM_AdasUSMResetReq 3;
BA_ "Description" SG_ 1145 USM_AdasUSMResetReq "This signal is used for a request to reset of ADAS USM settings.";
BA_ "Version" SG_ 1145 USM_AdasUSMResetReq "17.12.03";
BA_ "UserSigValidity" SG_ 1145 USM_AdasFCASetReq 3;
BA_ "Description" SG_ 1145 USM_AdasFCASetReq "This signal is used for a request to set the value of USM Menus. This signal requests to change status of FCA.";
BA_ "Version" SG_ 1145 USM_AdasFCASetReq "17.12.03";
BA_ "UserSigValidity" SG_ 1145 USM_AdasSCCDrvModSetReq 3;
BA_ "Description" SG_ 1145 USM_AdasSCCDrvModSetReq "This signal is used for a request to set the value of USM Menus. This signal requests to change status of SCC Driving mode.";
BA_ "Version" SG_ 1145 USM_AdasSCCDrvModSetReq "17.12.03";
BA_ "UserSigValidity" SG_ 1145 USM_AdasDAWModSetReq 3;
BA_ "Description" SG_ 1145 USM_AdasDAWModSetReq "This signal is used for a request to set the value of USM Menus. This signal requests to change status of DAW.";
BA_ "Version" SG_ 1145 USM_AdasDAWModSetReq "17.12.03";
BA_ "UserSigValidity" SG_ 1145 USM_AdasHDASetReq 3;
BA_ "Description" SG_ 1145 USM_AdasHDASetReq "This signal is used for a request to set the value of USM Menus. This signal requests to change status of HDA.";
BA_ "Version" SG_ 1145 USM_AdasHDASetReq "17.12.03";
BA_ "UserSigValidity" SG_ 1145 USM_AdasNSCCCamSetReq 3;
BA_ "Description" SG_ 1145 USM_AdasNSCCCamSetReq "This signal is used for a request to set the value of USM Menus. This signal requests to change status of NSCC Camera.";
BA_ "Version" SG_ 1145 USM_AdasNSCCCamSetReq "17.12.03";
BA_ "UserSigValidity" SG_ 1145 USM_AdasLFASetReq 3;
BA_ "Description" SG_ 1145 USM_AdasLFASetReq "This signal is used for a request to set the value of USM Menus. This signal requests to change status of LFA.";
BA_ "Version" SG_ 1145 USM_AdasLFASetReq "17.12.03";
BA_ "UserSigValidity" SG_ 1145 USM_AdasBCASetReq 3;
BA_ "Description" SG_ 1145 USM_AdasBCASetReq "This signal is used for a request to set the value of USM Menus. This signal requests to change status of BCA.";
BA_ "Version" SG_ 1145 USM_AdasBCASetReq "17.12.03";
BA_ "UserSigValidity" SG_ 1145 USM_AdasISLWSetReq 3;
BA_ "Description" SG_ 1145 USM_AdasISLWSetReq "This signal is used for a request to set the value of USM Menus. This signal requests to change status of ISLW.";
BA_ "Version" SG_ 1145 USM_AdasISLWSetReq "17.12.03";
BA_ "UserSigValidity" SG_ 1145 USM_AdasWrngTimingSetReq 3;
BA_ "Description" SG_ 1145 USM_AdasWrngTimingSetReq "This signal is used for a request to set the value of USM Menus. This signal requests to change status of ADASWarningTiming.";
BA_ "Version" SG_ 1145 USM_AdasWrngTimingSetReq "17.12.03";
BA_ "UserSigValidity" SG_ 1145 USM_AdasLVDASetReq 3;
BA_ "Description" SG_ 1145 USM_AdasLVDASetReq "This signal is used for a request to set the value of USM Menus. This signal requests to change status of LVDA.";
BA_ "Version" SG_ 1145 USM_AdasLVDASetReq "17.12.03";
BA_ "UserSigValidity" SG_ 1145 USM_AdasNSCCCrvSetReq 3;
BA_ "Description" SG_ 1145 USM_AdasNSCCCrvSetReq "This signal is used for a request to set the value of USM Menus. This signal requests to change status of NSCCCurve.";
BA_ "Version" SG_ 1145 USM_AdasNSCCCrvSetReq "17.12.03";
VAL_ 388 FR_CMR_Obj_MvngFlag09Sta 0 " Not Defined" 1 "  Standing (never moved back lights are on)" 2 "  Parked (never moved, back lights are off)" 3 "  Stopped (movable)" 4 "  Unknown (movable)" 5 "  Moving (movable)" 6 "  Stopped (Oncoming )" 7 "  Unknown (Oncoming )" 8 "  Moving (Oncoming )" 9 "  Crossing Bicycle" ;
VAL_ 388 FR_CMR_Obj_Clfct09Sta 0 " Unknown" 1 " Truck" 2 " Car" 3 " MotorBike" 4 " Bicycle" 5 " Pedestrians" 6 " Undecided" ;
VAL_ 388 FR_CMR_Obj_MvngFlag10Sta 0 " Not Defined" 1 "  Standing (never moved back lights are on)" 2 "  Parked (never moved, back lights are off)" 3 "  Stopped (movable)" 4 "  Unknown (movable)" 5 "  Moving (movable)" 6 "  Stopped (Oncoming )" 7 "  Unknown (Oncoming )" 8 "  Moving (Oncoming )" 9 "  Crossing Bicycle" ;
VAL_ 388 FR_CMR_Obj_Clfct10Sta 0 " Unknown" 1 " Truck" 2 " Car" 3 " MotorBike" 4 " Bicycle" 5 " Pedestrians" 6 " Undecided" ;
VAL_ 389 FR_CMR_Genrl_FlInfoSta 0 "Normal" 1 "Temp. Unavailable" 2 "Service Required" ;
VAL_ 389 FR_CMR_Genrl_DayTimeIndicatorSta 0 "Day" 1 "Night" 2 "Dusk" ;
VAL_ 416 SCC_ObjDstVal 1501 "Reserved" 1502 "Reserved" 1503 "Reserved" 1504 "Reserved" 1505 "Reserved" 1506 "Reserved" 1507 "Reserved" 1508 "Reserved" 1509 "Reserved" 1510 "Reserved" 1511 "Reserved" 1512 "Reserved" 1513 "Reserved" 1514 "Reserved" 1515 "Reserved" 1516 "Reserved" 1517 "Reserved" 1518 "Reserved" 1519 "Reserved" 1520 "Reserved" 1521 "Reserved" 1522 "Reserved" 1523 "Reserved" 1524 "Reserved" 1525 "Reserved" 1526 "Reserved" 1527 "Reserved" 1528 "Reserved" 1529 "Reserved" 1530 "Reserved" 1531 "Reserved" 1532 "Reserved" 1533 "Reserved" 1534 "Reserved" 1535 "Reserved" 1536 "Reserved" 1537 "Reserved" 1538 "Reserved" 1539 "Reserved" 1540 "Reserved" 1541 "Reserved" 1542 "Reserved" 1543 "Reserved" 1544 "Reserved" 1545 "Reserved" 1546 "Reserved" 1547 "Reserved" 1548 "Reserved" 1549 "Reserved" 1550 "Reserved" 1551 "Reserved" 1552 "Reserved" 1553 "Reserved" 1554 "Reserved" 1555 "Reserved" 1556 "Reserved" 1557 "Reserved" 1558 "Reserved" 1559 "Reserved" 1560 "Reserved" 1561 "Reserved" 1562 "Reserved" 1563 "Reserved" 1564 "Reserved" 1565 "Reserved" 1566 "Reserved" 1567 "Reserved" 1568 "Reserved" 1569 "Reserved" 1570 "Reserved" 1571 "Reserved" 1572 "Reserved" 1573 "Reserved" 1574 "Reserved" 1575 "Reserved" 1576 "Reserved" 1577 "Reserved" 1578 "Reserved" 1579 "Reserved" 1580 "Reserved" 1581 "Reserved" 1582 "Reserved" 1583 "Reserved" 1584 "Reserved" 1585 "Reserved" 1586 "Reserved" 1587 "Reserved" 1588 "Reserved" 1589 "Reserved" 1590 "Reserved" 1591 "Reserved" 1592 "Reserved" 1593 "Reserved" 1594 "Reserved" 1595 "Reserved" 1596 "Reserved" 1597 "Reserved" 1598 "Reserved" 1599 "Reserved" 1600 "Reserved" 1601 "Reserved" 1602 "Reserved" 1603 "Reserved" 1604 "Reserved" 1605 "Reserved" 1606 "Reserved" 1607 "Reserved" 1608 "Reserved" 1609 "Reserved" 1610 "Reserved" 1611 "Reserved" 1612 "Reserved" 1613 "Reserved" 1614 "Reserved" 1615 "Reserved" 1616 "Reserved" 1617 "Reserved" 1618 "Reserved" 1619 "Reserved" 1620 "Reserved" 1621 "Reserved" 1622 "Reserved" 1623 "Reserved" 1624 "Reserved" 1625 "Reserved" 1626 "Reserved" 1627 "Reserved" 1628 "Reserved" 1629 "Reserved" 1630 "Reserved" 1631 "Reserved" 1632 "Reserved" 1633 "Reserved" 1634 "Reserved" 1635 "Reserved" 1636 "Reserved" 1637 "Reserved" 1638 "Reserved" 1639 "Reserved" 1640 "Reserved" 1641 "Reserved" 1642 "Reserved" 1643 "Reserved" 1644 "Reserved" 1645 "Reserved" 1646 "Reserved" 1647 "Reserved" 1648 "Reserved" 1649 "Reserved" 1650 "Reserved" 1651 "Reserved" 1652 "Reserved" 1653 "Reserved" 1654 "Reserved" 1655 "Reserved" 1656 "Reserved" 1657 "Reserved" 1658 "Reserved" 1659 "Reserved" 1660 "Reserved" 1661 "Reserved" 1662 "Reserved" 1663 "Reserved" 1664 "Reserved" 1665 "Reserved" 1666 "Reserved" 1667 "Reserved" 1668 "Reserved" 1669 "Reserved" 1670 "Reserved" 1671 "Reserved" 1672 "Reserved" 1673 "Reserved" 1674 "Reserved" 1675 "Reserved" 1676 "Reserved" 1677 "Reserved" 1678 "Reserved" 1679 "Reserved" 1680 "Reserved" 1681 "Reserved" 1682 "Reserved" 1683 "Reserved" 1684 "Reserved" 1685 "Reserved" 1686 "Reserved" 1687 "Reserved" 1688 "Reserved" 1689 "Reserved" 1690 "Reserved" 1691 "Reserved" 1692 "Reserved" 1693 "Reserved" 1694 "Reserved" 1695 "Reserved" 1696 "Reserved" 1697 "Reserved" 1698 "Reserved" 1699 "Reserved" 1700 "Reserved" 1701 "Reserved" 1702 "Reserved" 1703 "Reserved" 1704 "Reserved" 1705 "Reserved" 1706 "Reserved" 1707 "Reserved" 1708 "Reserved" 1709 "Reserved" 1710 "Reserved" 1711 "Reserved" 1712 "Reserved" 1713 "Reserved" 1714 "Reserved" 1715 "Reserved" 1716 "Reserved" 1717 "Reserved" 1718 "Reserved" 1719 "Reserved" 1720 "Reserved" 1721 "Reserved" 1722 "Reserved" 1723 "Reserved" 1724 "Reserved" 1725 "Reserved" 1726 "Reserved" 1727 "Reserved" 1728 "Reserved" 1729 "Reserved" 1730 "Reserved" 1731 "Reserved" 1732 "Reserved" 1733 "Reserved" 1734 "Reserved" 1735 "Reserved" 1736 "Reserved" 1737 "Reserved" 1738 "Reserved" 1739 "Reserved" 1740 "Reserved" 1741 "Reserved" 1742 "Reserved" 1743 "Reserved" 1744 "Reserved" 1745 "Reserved" 1746 "Reserved" 1747 "Reserved" 1748 "Reserved" 1749 "Reserved" 1750 "Reserved" 1751 "Reserved" 1752 "Reserved" 1753 "Reserved" 1754 "Reserved" 1755 "Reserved" 1756 "Reserved" 1757 "Reserved" 1758 "Reserved" 1759 "Reserved" 1760 "Reserved" 1761 "Reserved" 1762 "Reserved" 1763 "Reserved" 1764 "Reserved" 1765 "Reserved" 1766 "Reserved" 1767 "Reserved" 1768 "Reserved" 1769 "Reserved" 1770 "Reserved" 1771 "Reserved" 1772 "Reserved" 1773 "Reserved" 1774 "Reserved" 1775 "Reserved" 1776 "Reserved" 1777 "Reserved" 1778 "Reserved" 1779 "Reserved" 1780 "Reserved" 1781 "Reserved" 1782 "Reserved" 1783 "Reserved" 1784 "Reserved" 1785 "Reserved" 1786 "Reserved" 1787 "Reserved" 1788 "Reserved" 1789 "Reserved" 1790 "Reserved" 1791 "Reserved" 1792 "Reserved" 1793 "Reserved" 1794 "Reserved" 1795 "Reserved" 1796 "Reserved" 1797 "Reserved" 1798 "Reserved" 1799 "Reserved" 1800 "Reserved" 1801 "Reserved" 1802 "Reserved" 1803 "Reserved" 1804 "Reserved" 1805 "Reserved" 1806 "Reserved" 1807 "Reserved" 1808 "Reserved" 1809 "Reserved" 1810 "Reserved" 1811 "Reserved" 1812 "Reserved" 1813 "Reserved" 1814 "Reserved" 1815 "Reserved" 1816 "Reserved" 1817 "Reserved" 1818 "Reserved" 1819 "Reserved" 1820 "Reserved" 1821 "Reserved" 1822 "Reserved" 1823 "Reserved" 1824 "Reserved" 1825 "Reserved" 1826 "Reserved" 1827 "Reserved" 1828 "Reserved" 1829 "Reserved" 1830 "Reserved" 1831 "Reserved" 1832 "Reserved" 1833 "Reserved" 1834 "Reserved" 1835 "Reserved" 1836 "Reserved" 1837 "Reserved" 1838 "Reserved" 1839 "Reserved" 1840 "Reserved" 1841 "Reserved" 1842 "Reserved" 1843 "Reserved" 1844 "Reserved" 1845 "Reserved" 1846 "Reserved" 1847 "Reserved" 1848 "Reserved" 1849 "Reserved" 1850 "Reserved" 1851 "Reserved" 1852 "Reserved" 1853 "Reserved" 1854 "Reserved" 1855 "Reserved" 1856 "Reserved" 1857 "Reserved" 1858 "Reserved" 1859 "Reserved" 1860 "Reserved" 1861 "Reserved" 1862 "Reserved" 1863 "Reserved" 1864 "Reserved" 1865 "Reserved" 1866 "Reserved" 1867 "Reserved" 1868 "Reserved" 1869 "Reserved" 1870 "Reserved" 1871 "Reserved" 1872 "Reserved" 1873 "Reserved" 1874 "Reserved" 1875 "Reserved" 1876 "Reserved" 1877 "Reserved" 1878 "Reserved" 1879 "Reserved" 1880 "Reserved" 1881 "Reserved" 1882 "Reserved" 1883 "Reserved" 1884 "Reserved" 1885 "Reserved" 1886 "Reserved" 1887 "Reserved" 1888 "Reserved" 1889 "Reserved" 1890 "Reserved" 1891 "Reserved" 1892 "Reserved" 1893 "Reserved" 1894 "Reserved" 1895 "Reserved" 1896 "Reserved" 1897 "Reserved" 1898 "Reserved" 1899 "Reserved" 1900 "Reserved" 1901 "Reserved" 1902 "Reserved" 1903 "Reserved" 1904 "Reserved" 1905 "Reserved" 1906 "Reserved" 1907 "Reserved" 1908 "Reserved" 1909 "Reserved" 1910 "Reserved" 1911 "Reserved" 1912 "Reserved" 1913 "Reserved" 1914 "Reserved" 1915 "Reserved" 1916 "Reserved" 1917 "Reserved" 1918 "Reserved" 1919 "Reserved" 1920 "Reserved" 1921 "Reserved" 1922 "Reserved" 1923 "Reserved" 1924 "Reserved" 1925 "Reserved" 1926 "Reserved" 1927 "Reserved" 1928 "Reserved" 1929 "Reserved" 1930 "Reserved" 1931 "Reserved" 1932 "Reserved" 1933 "Reserved" 1934 "Reserved" 1935 "Reserved" 1936 "Reserved" 1937 "Reserved" 1938 "Reserved" 1939 "Reserved" 1940 "Reserved" 1941 "Reserved" 1942 "Reserved" 1943 "Reserved" 1944 "Reserved" 1945 "Reserved" 1946 "Reserved" 1947 "Reserved" 1948 "Reserved" 1949 "Reserved" 1950 "Reserved" 1951 "Reserved" 1952 "Reserved" 1953 "Reserved" 1954 "Reserved" 1955 "Reserved" 1956 "Reserved" 1957 "Reserved" 1958 "Reserved" 1959 "Reserved" 1960 "Reserved" 1961 "Reserved" 1962 "Reserved" 1963 "Reserved" 1964 "Reserved" 1965 "Reserved" 1966 "Reserved" 1967 "Reserved" 1968 "Reserved" 1969 "Reserved" 1970 "Reserved" 1971 "Reserved" 1972 "Reserved" 1973 "Reserved" 1974 "Reserved" 1975 "Reserved" 1976 "Reserved" 1977 "Reserved" 1978 "Reserved" 1979 "Reserved" 1980 "Reserved" 1981 "Reserved" 1982 "Reserved" 1983 "Reserved" 1984 "Reserved" 1985 "Reserved" 1986 "Reserved" 1987 "Reserved" 1988 "Reserved" 1989 "Reserved" 1990 "Reserved" 1991 "Reserved" 1992 "Reserved" 1993 "Reserved" 1994 "Reserved" 1995 "Reserved" 1996 "Reserved" 1997 "Reserved" 1998 "Reserved" 1999 "Reserved" 2000 "Reserved" 2001 "Reserved" 2002 "Reserved" 2003 "Reserved" 2004 "Reserved" 2005 "Reserved" 2006 "Reserved" 2007 "Reserved" 2008 "Reserved" 2009 "Reserved" 2010 "Reserved" 2011 "Reserved" 2012 "Reserved" 2013 "Reserved" 2014 "Reserved" 2015 "Reserved" 2016 "Reserved" 2017 "Reserved" 2018 "Reserved" 2019 "Reserved" 2020 "Reserved" 2021 "Reserved" 2022 "Reserved" 2023 "Reserved" 2024 "Reserved" 2025 "Reserved" 2026 "Reserved" 2027 "Reserved" 2028 "Reserved" 2029 "Reserved" 2030 "Reserved" 2031 "Reserved" 2032 "Reserved" 2033 "Reserved" 2034 "Reserved" 2035 "Reserved" 2036 "Reserved" 2037 "Reserved" 2038 "Reserved" 2039 "Reserved" 2040 "Reserved" 2041 "Reserved" 2042 "Reserved" 2043 "Reserved" 2044 "Reserved" 2045 "Reserved" 2046 "Reserved" 2047 "Reserved" ;
VAL_ 416 SCC_ObjRelSpdVal 4094 "Default" 4095 "Error" ;
VAL_ 416 SCC_ObjLatPosVal 510 "Default" 511 "Error" ;
VAL_ 416 SCC_SysFlrSta 0 "System without error" 1 "Performance degredation" 2 "System temporairy unavailable" 3 "SCC Service Required" ;
VAL_ 416 SCC_MainOnOffSta 0 "OFF" 1 "ON" 2 "Not used" 3 "Error Indicator" ;
VAL_ 416 SCC_OpSta 0 "Off" 1 "Engaged" 2 "Override" 3 "Shutoff" 4 "Canceled" 5 "Reserved" 6 "Reserved" 7 "Reserved" ;
VAL_ 416 SCC_TakeoverReq 0 "No takeover request" 1 "Takeover request" 2 "Not used" 3 "Error Indicator" ;
VAL_ 416 SCC_InfoDis 0 "-" 1 "Display “SCC Mode”" 2 "Display “Conventional Cruise Mode”" 3 "Display “Object disappeared at low speed”" 4 "Display “Available to resume acceleration control”" 5 "Display “Front vehicle departure notice”" 6 "Reserved" 7 "Invalid" ;
VAL_ 416 SCC_DrvAlrtDis 0 "-" 1 "Display 'SCC Disengaged'" 2 "Display 'No SCC Engage Condition!'" 3 "Display 'SCC Disengaged When The Vehicle Stops'" ;
VAL_ 416 SCC_HeadwayDstSetVal 0 "No time gap set" 1 "1st level distance" 2 "2nd level distance" 3 "3rd level distance" 4 "4th level distance" 5 "Reserved" 6 "Reserved" 7 "Reserved" 8 "Reserved" 9 "Reserved" 10 "Reserved" 11 "Reserved" 12 "Reserved" 13 "Reserved" 14 "SCC-ML Active" 15 "Error Indicator" ;
VAL_ 416 SCC_EquipSta 0 "Not Applied" 1 "Applied" 2 "Not used" 3 "Error Indicator" ;
VAL_ 416 SCC_TrgtSpdSetVal 255 "Error" ;
VAL_ 416 SCC_NSCCOpSta 0 "Off" 1 "Ready" 2 "Act" 3 "Error Indicator" ;
VAL_ 416 SCC_NSCCOnOffSta 0 "Default" 1 "Off" 2 "On" 3 "Invalid" ;
VAL_ 416 SCC_ObjSta 0 "No in-path object detected" 1 "In-path object detected (uncontrollable)" 2 "In-path object detected (controllable longitudinal)" 3 "In-path object detected (controllable longitudinal & lateral)" 4 "Reserved" 5 "Reserved" 6 "Reserved" 7 "Reserved" ;
VAL_ 416 SCC_SnstvtyModRetVal 0 "Default" 1 "Comford Mode" 2 "Normal Mode" 3 "Dynamic Mode" 4 "Reserved" 5 "Reserved" 6 "Reserved" 7 "Invalid" ;
VAL_ 416 SCC_AccelReqVal 2047 "Error" ;
VAL_ 416 SCC_AccelReqRawVal 2047 "Error" ;
VAL_ 416 SCC_JrkUppLimVal 127 "No Limit" ;
VAL_ 416 SCC_JrkLwrLimVal 127 "No Limit" ;
VAL_ 416 SCC_AccelLimBandUppVal 0 "Precise Control" ;
VAL_ 416 SCC_AccelLimBandLwrVal 0 "Precise Control" ;
VAL_ 416 SCC_VehStpReq 0 "No request" 1 "Stop control is required" 2 "Not used" 3 "Error Indicator" ;
VAL_ 416 SCC_TrgtDstVal 1501 "Reserved" 1502 "Reserved" 1503 "Reserved" 1504 "Reserved" 1505 "Reserved" 1506 "Reserved" 1507 "Reserved" 1508 "Reserved" 1509 "Reserved" 1510 "Reserved" 1511 "Reserved" 1512 "Reserved" 1513 "Reserved" 1514 "Reserved" 1515 "Reserved" 1516 "Reserved" 1517 "Reserved" 1518 "Reserved" 1519 "Reserved" 1520 "Reserved" 1521 "Reserved" 1522 "Reserved" 1523 "Reserved" 1524 "Reserved" 1525 "Reserved" 1526 "Reserved" 1527 "Reserved" 1528 "Reserved" 1529 "Reserved" 1530 "Reserved" 1531 "Reserved" 1532 "Reserved" 1533 "Reserved" 1534 "Reserved" 1535 "Reserved" 1536 "Reserved" 1537 "Reserved" 1538 "Reserved" 1539 "Reserved" 1540 "Reserved" 1541 "Reserved" 1542 "Reserved" 1543 "Reserved" 1544 "Reserved" 1545 "Reserved" 1546 "Reserved" 1547 "Reserved" 1548 "Reserved" 1549 "Reserved" 1550 "Reserved" 1551 "Reserved" 1552 "Reserved" 1553 "Reserved" 1554 "Reserved" 1555 "Reserved" 1556 "Reserved" 1557 "Reserved" 1558 "Reserved" 1559 "Reserved" 1560 "Reserved" 1561 "Reserved" 1562 "Reserved" 1563 "Reserved" 1564 "Reserved" 1565 "Reserved" 1566 "Reserved" 1567 "Reserved" 1568 "Reserved" 1569 "Reserved" 1570 "Reserved" 1571 "Reserved" 1572 "Reserved" 1573 "Reserved" 1574 "Reserved" 1575 "Reserved" 1576 "Reserved" 1577 "Reserved" 1578 "Reserved" 1579 "Reserved" 1580 "Reserved" 1581 "Reserved" 1582 "Reserved" 1583 "Reserved" 1584 "Reserved" 1585 "Reserved" 1586 "Reserved" 1587 "Reserved" 1588 "Reserved" 1589 "Reserved" 1590 "Reserved" 1591 "Reserved" 1592 "Reserved" 1593 "Reserved" 1594 "Reserved" 1595 "Reserved" 1596 "Reserved" 1597 "Reserved" 1598 "Reserved" 1599 "Reserved" 1600 "Reserved" 1601 "Reserved" 1602 "Reserved" 1603 "Reserved" 1604 "Reserved" 1605 "Reserved" 1606 "Reserved" 1607 "Reserved" 1608 "Reserved" 1609 "Reserved" 1610 "Reserved" 1611 "Reserved" 1612 "Reserved" 1613 "Reserved" 1614 "Reserved" 1615 "Reserved" 1616 "Reserved" 1617 "Reserved" 1618 "Reserved" 1619 "Reserved" 1620 "Reserved" 1621 "Reserved" 1622 "Reserved" 1623 "Reserved" 1624 "Reserved" 1625 "Reserved" 1626 "Reserved" 1627 "Reserved" 1628 "Reserved" 1629 "Reserved" 1630 "Reserved" 1631 "Reserved" 1632 "Reserved" 1633 "Reserved" 1634 "Reserved" 1635 "Reserved" 1636 "Reserved" 1637 "Reserved" 1638 "Reserved" 1639 "Reserved" 1640 "Reserved" 1641 "Reserved" 1642 "Reserved" 1643 "Reserved" 1644 "Reserved" 1645 "Reserved" 1646 "Reserved" 1647 "Reserved" 1648 "Reserved" 1649 "Reserved" 1650 "Reserved" 1651 "Reserved" 1652 "Reserved" 1653 "Reserved" 1654 "Reserved" 1655 "Reserved" 1656 "Reserved" 1657 "Reserved" 1658 "Reserved" 1659 "Reserved" 1660 "Reserved" 1661 "Reserved" 1662 "Reserved" 1663 "Reserved" 1664 "Reserved" 1665 "Reserved" 1666 "Reserved" 1667 "Reserved" 1668 "Reserved" 1669 "Reserved" 1670 "Reserved" 1671 "Reserved" 1672 "Reserved" 1673 "Reserved" 1674 "Reserved" 1675 "Reserved" 1676 "Reserved" 1677 "Reserved" 1678 "Reserved" 1679 "Reserved" 1680 "Reserved" 1681 "Reserved" 1682 "Reserved" 1683 "Reserved" 1684 "Reserved" 1685 "Reserved" 1686 "Reserved" 1687 "Reserved" 1688 "Reserved" 1689 "Reserved" 1690 "Reserved" 1691 "Reserved" 1692 "Reserved" 1693 "Reserved" 1694 "Reserved" 1695 "Reserved" 1696 "Reserved" 1697 "Reserved" 1698 "Reserved" 1699 "Reserved" 1700 "Reserved" 1701 "Reserved" 1702 "Reserved" 1703 "Reserved" 1704 "Reserved" 1705 "Reserved" 1706 "Reserved" 1707 "Reserved" 1708 "Reserved" 1709 "Reserved" 1710 "Reserved" 1711 "Reserved" 1712 "Reserved" 1713 "Reserved" 1714 "Reserved" 1715 "Reserved" 1716 "Reserved" 1717 "Reserved" 1718 "Reserved" 1719 "Reserved" 1720 "Reserved" 1721 "Reserved" 1722 "Reserved" 1723 "Reserved" 1724 "Reserved" 1725 "Reserved" 1726 "Reserved" 1727 "Reserved" 1728 "Reserved" 1729 "Reserved" 1730 "Reserved" 1731 "Reserved" 1732 "Reserved" 1733 "Reserved" 1734 "Reserved" 1735 "Reserved" 1736 "Reserved" 1737 "Reserved" 1738 "Reserved" 1739 "Reserved" 1740 "Reserved" 1741 "Reserved" 1742 "Reserved" 1743 "Reserved" 1744 "Reserved" 1745 "Reserved" 1746 "Reserved" 1747 "Reserved" 1748 "Reserved" 1749 "Reserved" 1750 "Reserved" 1751 "Reserved" 1752 "Reserved" 1753 "Reserved" 1754 "Reserved" 1755 "Reserved" 1756 "Reserved" 1757 "Reserved" 1758 "Reserved" 1759 "Reserved" 1760 "Reserved" 1761 "Reserved" 1762 "Reserved" 1763 "Reserved" 1764 "Reserved" 1765 "Reserved" 1766 "Reserved" 1767 "Reserved" 1768 "Reserved" 1769 "Reserved" 1770 "Reserved" 1771 "Reserved" 1772 "Reserved" 1773 "Reserved" 1774 "Reserved" 1775 "Reserved" 1776 "Reserved" 1777 "Reserved" 1778 "Reserved" 1779 "Reserved" 1780 "Reserved" 1781 "Reserved" 1782 "Reserved" 1783 "Reserved" 1784 "Reserved" 1785 "Reserved" 1786 "Reserved" 1787 "Reserved" 1788 "Reserved" 1789 "Reserved" 1790 "Reserved" 1791 "Reserved" 1792 "Reserved" 1793 "Reserved" 1794 "Reserved" 1795 "Reserved" 1796 "Reserved" 1797 "Reserved" 1798 "Reserved" 1799 "Reserved" 1800 "Reserved" 1801 "Reserved" 1802 "Reserved" 1803 "Reserved" 1804 "Reserved" 1805 "Reserved" 1806 "Reserved" 1807 "Reserved" 1808 "Reserved" 1809 "Reserved" 1810 "Reserved" 1811 "Reserved" 1812 "Reserved" 1813 "Reserved" 1814 "Reserved" 1815 "Reserved" 1816 "Reserved" 1817 "Reserved" 1818 "Reserved" 1819 "Reserved" 1820 "Reserved" 1821 "Reserved" 1822 "Reserved" 1823 "Reserved" 1824 "Reserved" 1825 "Reserved" 1826 "Reserved" 1827 "Reserved" 1828 "Reserved" 1829 "Reserved" 1830 "Reserved" 1831 "Reserved" 1832 "Reserved" 1833 "Reserved" 1834 "Reserved" 1835 "Reserved" 1836 "Reserved" 1837 "Reserved" 1838 "Reserved" 1839 "Reserved" 1840 "Reserved" 1841 "Reserved" 1842 "Reserved" 1843 "Reserved" 1844 "Reserved" 1845 "Reserved" 1846 "Reserved" 1847 "Reserved" 1848 "Reserved" 1849 "Reserved" 1850 "Reserved" 1851 "Reserved" 1852 "Reserved" 1853 "Reserved" 1854 "Reserved" 1855 "Reserved" 1856 "Reserved" 1857 "Reserved" 1858 "Reserved" 1859 "Reserved" 1860 "Reserved" 1861 "Reserved" 1862 "Reserved" 1863 "Reserved" 1864 "Reserved" 1865 "Reserved" 1866 "Reserved" 1867 "Reserved" 1868 "Reserved" 1869 "Reserved" 1870 "Reserved" 1871 "Reserved" 1872 "Reserved" 1873 "Reserved" 1874 "Reserved" 1875 "Reserved" 1876 "Reserved" 1877 "Reserved" 1878 "Reserved" 1879 "Reserved" 1880 "Reserved" 1881 "Reserved" 1882 "Reserved" 1883 "Reserved" 1884 "Reserved" 1885 "Reserved" 1886 "Reserved" 1887 "Reserved" 1888 "Reserved" 1889 "Reserved" 1890 "Reserved" 1891 "Reserved" 1892 "Reserved" 1893 "Reserved" 1894 "Reserved" 1895 "Reserved" 1896 "Reserved" 1897 "Reserved" 1898 "Reserved" 1899 "Reserved" 1900 "Reserved" 1901 "Reserved" 1902 "Reserved" 1903 "Reserved" 1904 "Reserved" 1905 "Reserved" 1906 "Reserved" 1907 "Reserved" 1908 "Reserved" 1909 "Reserved" 1910 "Reserved" 1911 "Reserved" 1912 "Reserved" 1913 "Reserved" 1914 "Reserved" 1915 "Reserved" 1916 "Reserved" 1917 "Reserved" 1918 "Reserved" 1919 "Reserved" 1920 "Reserved" 1921 "Reserved" 1922 "Reserved" 1923 "Reserved" 1924 "Reserved" 1925 "Reserved" 1926 "Reserved" 1927 "Reserved" 1928 "Reserved" 1929 "Reserved" 1930 "Reserved" 1931 "Reserved" 1932 "Reserved" 1933 "Reserved" 1934 "Reserved" 1935 "Reserved" 1936 "Reserved" 1937 "Reserved" 1938 "Reserved" 1939 "Reserved" 1940 "Reserved" 1941 "Reserved" 1942 "Reserved" 1943 "Reserved" 1944 "Reserved" 1945 "Reserved" 1946 "Reserved" 1947 "Reserved" 1948 "Reserved" 1949 "Reserved" 1950 "Reserved" 1951 "Reserved" 1952 "Reserved" 1953 "Reserved" 1954 "Reserved" 1955 "Reserved" 1956 "Reserved" 1957 "Reserved" 1958 "Reserved" 1959 "Reserved" 1960 "Reserved" 1961 "Reserved" 1962 "Reserved" 1963 "Reserved" 1964 "Reserved" 1965 "Reserved" 1966 "Reserved" 1967 "Reserved" 1968 "Reserved" 1969 "Reserved" 1970 "Reserved" 1971 "Reserved" 1972 "Reserved" 1973 "Reserved" 1974 "Reserved" 1975 "Reserved" 1976 "Reserved" 1977 "Reserved" 1978 "Reserved" 1979 "Reserved" 1980 "Reserved" 1981 "Reserved" 1982 "Reserved" 1983 "Reserved" 1984 "Reserved" 1985 "Reserved" 1986 "Reserved" 1987 "Reserved" 1988 "Reserved" 1989 "Reserved" 1990 "Reserved" 1991 "Reserved" 1992 "Reserved" 1993 "Reserved" 1994 "Reserved" 1995 "Reserved" 1996 "Reserved" 1997 "Reserved" 1998 "Reserved" 1999 "Reserved" 2000 "Reserved" 2001 "Reserved" 2002 "Reserved" 2003 "Reserved" 2004 "Reserved" 2005 "Reserved" 2006 "Reserved" 2007 "Reserved" 2008 "Reserved" 2009 "Reserved" 2010 "Reserved" 2011 "Reserved" 2012 "Reserved" 2013 "Reserved" 2014 "Reserved" 2015 "Reserved" 2016 "Reserved" 2017 "Reserved" 2018 "Reserved" 2019 "Reserved" 2020 "Reserved" 2021 "Reserved" 2022 "Reserved" 2023 "Reserved" 2024 "Reserved" 2025 "Reserved" 2026 "Reserved" 2027 "Reserved" 2028 "Reserved" 2029 "Reserved" 2030 "Reserved" 2031 "Reserved" 2032 "Reserved" 2033 "Reserved" 2034 "Reserved" 2035 "Reserved" 2036 "Reserved" 2037 "Reserved" 2038 "Reserved" 2039 "Reserved" 2040 "Reserved" 2041 "Reserved" 2042 "Reserved" 2043 "Reserved" 2044 "Reserved" 2045 "Reserved" 2046 "Reserved" 2047 "Reserved" ;
VAL_ 426 CLU_DtntOutSta 0 "Detent Off" 1 "Detent On" 2 "Not used" 3 "Error Indicator" ;
VAL_ 426 CLU_SpdUnitTyp 0 "km/h" 1 "MPH" 2 "Not used" 3 "Error Indicator" ;
VAL_ 426 CLU_SWRCLFASwSta 0 "Off" 1 "Key On" 2 "Reserved" 3 "Invalid" ;
VAL_ 426 CLU_RhstaLvlSta 0 "Reserved" 1 "Step 1" 2 "Step 2" 3 "Step 3" 4 "Step 4" 5 "Step 5" 6 "Step 6" 7 "Step 7" 8 "Step 8" 9 "Step 9" 10 "Step 10" 11 "Step 11" 12 "Step 12" 13 "Step 13" 14 "Step 14" 15 "Step 15" 16 "Step 16" 17 "Step 17" 18 "Step 18" 19 "Step 19" 20 "Step 20 (Reset Value)" 21 "Step 21 (Detent)" ;
VAL_ 426 CLU_DisSpdVal 1023 "Error" ;
VAL_ 437 Info_LftLnQualSta 0 "Very Low Quality" 1 "Low Quality" 2 "High Quality" 3 "Very High Quality" 4 "Reserved" 5 "Reserved" 6 "Reserved" 7 "Error indicator" ;
VAL_ 437 Info_LftLnDptSta 0 "No Left Line Departure" 1 "Left Line Departure" 2 "Reserved" 3 "Error Indicator" ;
VAL_ 437 Info_RtLnQualSta 0 "Very Low Quality" 1 "Low Quality" 2 "High Quality" 3 "Very High Quality" 4 "Reserved" 5 "Reserved" 6 "Reserved" 7 "Error indicator" ;
VAL_ 437 Info_RtLnDptSta 0 "No Right Line Departure" 1 "Right Line Departure" 2 "Reserved" 3 "Error Indicator" ;
VAL_ 442 BCA_Sta 0 "Default" 1 "BCA Function is off" 2 "BCA Function is passive" 3 "BCA Function active" 4 "BCA Function failure" 5 "BCA Function Blockage" 6 "BCA Function minor failure" 7 "Failure low priority" 8 "Reserved" 9 "Reserved" 10 "Reserved" 11 "Reserved" 12 "Reserved" 13 "Reserved" 14 "Reserved" ;
VAL_ 442 BCA_LftWrngSta 0 "BCA Left Warning is Off" 1 "BCA Left Warning is On" 2 "Not used" 3 "Error Indicator" ;
VAL_ 442 BCA_RtWrngSta 0 "BCA Right Warning is Off" 1 "BCA Right Warning is On" 2 "Not used" 3 "Error Indicator" ;
VAL_ 463 SWRC_CrsSwSta 0 "Idle Position" 1 "Plus/Set" 2 "Minus/Set" 3 "Time gap (Distance, SCC only)" 4 "Pause/Resume" 5 "Reserved" 6 "Reserved" 7 "Reserved" ;
VAL_ 463 SWRC_CrsMainSwSta 0 "Off" 1 "Key On" 2 "Reserved" 3 "Invalid" ;
VAL_ 463 SWRC_SldMainSwSta 0 "Off" 1 "Key On" 2 "Reserved" 3 "Invalid" ;
VAL_ 463 SWRC_LFASwSta 0 "Off" 1 "Key On" 2 "Reserved" 3 "Invalid" ;
VAL_ 480 HDA_OptUsmSta 0 "Not Applied" 1 "Function Off" 2 "Function On" 3 "Reserved" 4 "Reserved" 5 "Reserved" 6 "Reserved" 7 "Invalid (Fail)" ;
VAL_ 480 LFA_OptUsmSta 0 "Not Applied" 1 "Function Off" 2 "Function On" 3 "Reserved" 4 "Reserved" 5 "Reserved" 6 "Reserved" 7 "Invalid (Fail)" ;
VAL_ 480 HDA_CntrlModSta 0 "System Deactive (Default)" 1 "System Ready" 2 "System Active" 3 "Reserved" ;
VAL_ 480 HDA_InfoPUDis 0 "No pop-up" 1 "system start pop-up" 2 "system auto disengaged pop-up by highway off" 3 "system auto disengaged pop-up" 4 "system Fail pop-up" 5 "Hands-off pop up" 6 "Hands-off pop up w/ sound" 7 "System Automatic off" ;
VAL_ 480 HDA_AutoSetSpdSta 0 "Auto Set Speed Off" 1 "Auto Set Speed On" 2 "Reserved" 3 "Error indicator" ;
VAL_ 480 HDA_AutoSetSpdUpdtSta 0 "Auto Set Speed Update Off" 1 "Auto Set Speed Update On" 2 "Reserved" 3 "Error indicator" ;
VAL_ 480 HDA_LFA_SymSta 0 "Off" 1 "Gray" 2 "Green" 3 "Green blink" ;
VAL_ 480 HDA_LFA_WrnSnd 0 "Off " 1 "Additional Warning Sound" 2 "Reserved" 3 "Error indicator" ;
VAL_ 506 ISLA_SpdwOffst 255 "Invalid" 254 "Reserved" 253 "Unlimited Speed" 1 "1-252 kph or mph" 0 "No Recognition" ;
VAL_ 506 ISLA_SwIgnoreReq 3 "-(SET) and +(SET) Ignore" 2 "+(SET) Switch Input Ignore" 1 "-(SET) Switch Input Ignore" 0 "Allow All Switch Inputs" ;
VAL_ 506 ISLA_SpdChgReq 3 "Reserved" 2 "Reserved" 1 "Speed Change Request" 0 "Default" ;
VAL_ 506 ISLA_SpdWrn 3 "Reserved" 2 "Reserved" 1 "Warning" 0 "No Warning" ;
VAL_ 506 ISLA_IcyWrn 3 "Reserved" 2 "Reserved" 1 "Warning" 0 "No Warning" ;
VAL_ 506 ISLA_SymFlashMod 7 "Reserved" 6 "Reserved" 5 "Reserved" 4 "Flashing Auto Symbol" 3 "Flashing + Arrow Symbol" 2 "Flashing - Arrow Symbol" 1 "Flashing Sign" 0 "No Flasing" ;
VAL_ 506 ISLA_Popup 7 "Reserved" 6 "Reserved" 5 "Reserved" 4 "CC_SCC Speed has Changed" 3 "CC_SCC Speed will Change" 2 "MSLA Speed has Changed" 1 "MSLA Speed will Change" 0 "No Popup" ;
VAL_ 506 ISLA_OptUsmSta 7 "Invalid (GRAY)" 6 "Reserved" 5 "Reserved" 4 "Reserved" 3 "Assist" 2 "Warning" 1 "Off" 0 "None ISLA Option" ;
VAL_ 506 ISLA_OffstUsmSta 7 "Invalid (GRAY)" 6 "Reserved" 5 "+10kph or +5mph" 4 "+5kph or +3mph" 3 "0kph or 0mph" 2 "-5kph or -3mph" 1 "-10kph or -5mph" 0 "None Offset Function" ;
VAL_ 506 ISLA_AutoUsmSta 3 "Invalid (GRAY)" 2 "Auto On" 1 "Auto Off" 0 "None Auto Function (Delete Menu)" ;
VAL_ 506 ISLA_Cntry 15 "Initial Value (default)" 14 "Reserved" 13 "Reserved" 12 "Reserved" 11 "Reserved" 10 "Reserved" 9 "Reserved" 8 "Reserved" 7 "Reserved" 6 "Reserved" 5 "Australia" 4 "Canada" 3 "USA" 2 "China" 1 "Domestic" 0 "Europe_Russia_Australia" ;
VAL_ 506 ISLA_AddtnlSign 31 "Reserved" 30 "Reserved" 29 "Reserved" 28 "Winding Road" 27 "Left Curve" 26 "Right Curve" 25 "Roundabout" 24 "Exit" 23 "Reserved" 22 "Reserved" 21 "Reserved" 20 "Reserved" 19 "Reserved" 18 "Reserved" 17 "Reserved" 16 "Do Not Pass" 15 "Reserved" 14 "Reserved" 13 "Lane Reduction" 12 "Road Construction Ahead" 11 "Yield Ahead" 10 "Stop Ahead" 9 "Yield" 8 "Stop" 7 "Reserved" 6 "Reserved" 5 "Reserved" 4 "Reserved" 3 "Bicycle Crossing" 2 "Pedestrian Crossing" 1 "School Crossing" 0 "No Recognition (default)" ;
VAL_ 506 ISLA_SchoolZone 3 "Reserved" 2 "Reserved" 1 "School Zone" 0 "No School Zone" ;
VAL_ 506 ISLW_OptUsmSta 0 "None ISLW Option (Default)" 1 "System Disabled by USM" 2 "System Enable by USM" 3 "Reserved" ;
VAL_ 506 ISLW_SysSta 0 "Normal (Default)" 1 "System Fail" 2 "ISLW Temporary Unavailable" 3 "Reserved" ;
VAL_ 506 ISLW_NoPassingInfoDis 0 "None Display (Default)" 1 "LHD No Passing Zone Display" 2 "RHD No Passing Zone Display" 3 "Reserved" 4 "Reserved" 5 "Reserved" 6 "Reserved" 7 "Invalid" ;
VAL_ 506 ISLW_OvrlpSignDis 0 "None (Default)" 1 "Overlap Sign" 2 "Reserved" 3 "Error indicator" ;
VAL_ 506 ISLW_SpdCluMainDis 255 "Invalid" 254 "Reserved" 253 "Unlimited Speed" 0 "No Recognition (Default)" ;
VAL_ 506 ISLW_SpdNaviMainDis 255 "Invalid" 254 "Reserved" 253 "Unlimited Speed" 0 "No Recognition (Default)" ;
VAL_ 506 ISLW_SubCondinfoSta1 0 "None (Default)" 1 "Rain" 2 "Snow" 3 "Snow&Rain" 4 "Trailer" 5 "Distance" 6 "Time" 7 "Fog" 8 "Reserved" 9 "Reserved" 10 "Reserved" 11 "Reserved" 12 "Reserved" 13 "Reserved" 14 "Reserved" 15 "Generic" ;
VAL_ 506 ISLW_SubCondinfoSta2 0 "None (Default)" 1 "Rain" 2 "Snow" 3 "Snow&Rain" 4 "Trailer" 5 "Distance" 6 "Time" 7 "Fog" 8 "Reserved" 9 "Reserved" 10 "Reserved" 11 "Reserved" 12 "Reserved" 13 "Reserved" 14 "Reserved" 15 "Generic" ;
VAL_ 506 ISLW_SpdCluSubMainDis 255 "Invalid" 254 "Reserved" 253 "Unlimited Speed" 0 "No Recognition (Default)" ;
VAL_ 506 ISLW_SpdCluDisSubCond1 255 "Invalid" 254 "RHD Conditional No Passing ZONE" 253 "LHD Conditional No Passing ZONE" 0 "No Recognition (Default)" ;
VAL_ 506 ISLW_SpdCluDisSubCond2 255 "Invalid" 254 "RHD Conditional No Passing ZONE" 253 "LHD Conditional No Passing ZONE" 0 "No Recognition (Default)" ;
VAL_ 506 ISLW_SpdNaviSubMainDis 255 "Invalid" 254 "Reserved" 253 "Unlimited Speed" 0 "No Recognition (Default)" ;
VAL_ 506 ISLW_SpdNaviDisSubCond1 255 "Invalid" 254 "RHD Conditional No Passing ZONE" 253 "LHD Conditional No Passing ZONE" 0 "No Recognition (Default)" ;
VAL_ 506 ISLW_SpdNaviDisSubCond2 255 "Invalid" 254 "RHD Conditional No Passing ZONE" 253 "LHD Conditional No Passing ZONE" 0 "No Recognition (Default)" ;
VAL_ 549 CLU_TerrainMainSwSta 0 "Default" 1 "On-Road" 2 "Off-Road" 3 "Reserved" ;
VAL_ 549 CLU_OdoVal 16777215 "Error" ;
VAL_ 549 CLU_IceWrnIndSta 0 "Off" 1 "On" 2 "Not used" 3 "Error Indicator" ;
VAL_ 549 CLU_DrvngModSwSta 0 "Off" 1 "Normal" 2 "Eco" 3 "Sport" 4 "Sport+" 5 "Smart" 6 "Custom" 7 "N-mode" 8 "Reserved" 9 "Reserved" 10 "Reserved" 11 "Reserved" 12 "Reserved" 13 "Reserved" 14 "Reserved" 15 "Reserved" ;
VAL_ 549 CLU_TerrainModSwSta 0 "Default" 1 "Snow" 2 "Sand" 3 "Mud" 4 "Reserved" 5 "Reserved" 6 "Reserved" 7 "Reserved" ;
VAL_ 560 HCU_BrkLmpOnReq 0 "None" 1 "Lamp On Request" 2 "Not used" 3 "Error Indicator" ;
VAL_ 608 ENG_TransmsnTyp 0 "A/T vehicle (Step Shift A/T)" 10 "CVT vehicle (CVT A/T)" 11 "DCT vehicle (DCT A/T)" 15 "M/T vehicle" ;
VAL_ 608 ENG_EngDsplceTyp 255 "Error indicator" ;
VAL_ 613 HEV_BrkLtSwSta 0 "Not Support" 1 "Off" 2 "On" 3 "failure" ;
VAL_ 676 FR_CMR_Ln_ClfctLft01Sta 0 " Dashed" 1 "  Solid" 2 "  Undecided" 3 "  Road Edge" 4 "  DLM Inner Solid" 5 "  DLM Inner Dashed" 6 "  DLM Inner Undecided" 7 "  Botts Dots" 8 "  Barrier" ;
VAL_ 676 FR_CMR_Ln_ClfctRt01Sta 0 " Dashed" 1 "  Solid" 2 "  Undecided" 3 "  Road Edge" 4 "  DLM Inner Solid" 5 "  DLM Inner Dashed" 6 "  DLM Inner Undecided" 7 "  Botts Dots" 8 "  Barrier" ;
VAL_ 676 FR_CMR_Ln_LftClr01Sta 0 " Unknown" 1 " White" 2 " Yellow,Orange,Red" 3 " Blue,Green" ;
VAL_ 676 FR_CMR_Ln_RtClr01Sta 0 " Unknown" 1 " White" 2 " Yellow,Orange,Red" 3 " Blue,Green" ;
VAL_ 676 FR_CMR_Ln_QualLvlLft01Sta 0 " Very Low Quality 1" 1 " Low Quality 2" 2 " Prediction" 3 " High Quality" 4 "Reserved" 5 "Reserved" 6 "Not used" 7 "Error Indicator" ;
VAL_ 676 FR_CMR_Ln_QualLvlRt01Sta 0 " Very Low Quality 1" 1 " Low Quality 2" 2 " Prediction" 3 " High Quality" 4 "Reserved" 5 "Reserved" 6 "Not used" 7 "Error Indicator" ;
VAL_ 676 FR_CMR_Ln_ClfctLft02Sta 0 " Dashed" 1 "  Solid" 2 "  Undecided" 3 "  Road Edge" 4 "  DLM Inner Solid" 5 "  DLM Inner Dashed" 6 "  DLM Inner Undecided" 7 "  Botts Dots" 8 "  Barrier" ;
VAL_ 676 FR_CMR_Ln_ClfctRt02Sta 0 " Dashed" 1 "  Solid" 2 "  Undecided" 3 "  Road Edge" 4 "  DLM Inner Solid" 5 "  DLM Inner Dashed" 6 "  DLM Inner Undecided" 7 "  Botts Dots" 8 "  Barrier" ;
VAL_ 676 FR_CMR_Ln_QualLvlLft02Sta 0 " Very Low Quality 1" 1 " Low Quality 2" 2 " Prediction" 3 " High Quality" 4 "Reserved" 5 "Reserved" 6 "Not used" 7 "Error Indicator" ;
VAL_ 676 FR_CMR_Ln_QualLvlRt02Sta 0 " Very Low Quality 1" 1 " Low Quality 2" 2 " Prediction" 3 " High Quality" 4 "Reserved" 5 "Reserved" 6 "Not used" 7 "Error Indicator" ;
VAL_ 698 IFSref_FR_CMR_Sta 0 "None Option (Default)" 1 "Normal" 2 "Blockage Status" 3 "Error Indicator" ;
VAL_ 698 IFSref_VehNumVal 0 "No vehicle" 1 "Number of vehicles" 2 "Number of vehicles" 3 "Number of vehicles" 4 "Number of vehicles" 5 "Number of vehicles" 6 "Number of vehicles" 7 "Number of vehicles" 8 "Number of vehicles" 9 "Number of vehicles" 10 "Number of vehicles" 11 "Over than 10 vehicles" 12 "Reserved" 13 "Reserved" 14 "Default" 15 "Error indicator" ;
VAL_ 698 IFSref_ILLAmbtSta 0 "Bright" 1 "Dark" 2 "Not used" 3 "Error indicator" ;
VAL_ 720 TCU_WrngMsgSta 0 "No Warning message" 1 "Warning message 1" 2 "Warning message 2" 3 "Warning message 3" 4 "Warning message 4" ;
VAL_ 934 PTGM_SpeedRValue 0 "Default" 1 "Fast" 2 "Slow" 3 "Invalid" ;
VAL_ 934 PTGM_SpeedSetWarn 0 "Off" 1 "On" ;
VAL_ 934 PTGM_HeightRValue 0 "Default" 1 "Level1" 2 "Level2" 3 "Level3" 4 "Level4" 5 "Reserved" 6 "Reserved" 7 "Invalid" ;
VAL_ 934 PTGM_CmdWarn 0 "Default" 1 "Gear P or Vehicle speed" 2 "Obstacle detected" 3 "System temporary error" 4 "Power mode OFF" 5 "Reserved" 6 "Reserved" 7 "Invalid" ;
VAL_ 934 PTGM_AntiPinchSnsr 0 "Default" 1 "Applied" 2 "Not applied" 3 "Invalid" ;
VAL_ 961 Lamp_HdLmpHiSwSta 0 "Off" 1 "On" 2 "Not Used" 3 "Error Indicator" ;
VAL_ 961 Lamp_LtSwSta 0 "Light Sw Off" 1 "Tail Sw On" 2 "HeadLamp Low Sw On" 3 "AutoLight Sw On" ;
VAL_ 961 Lamp_OneTouchTrnSigLftSwSta 0 "Off" 1 "On" 2 "Not Used" 3 "Error Indicator" ;
VAL_ 961 Lamp_OneTouchTrnSigRtSwSta 0 "Off" 1 "On" 2 "Not Used" 3 "Error Indicator" ;
VAL_ 961 Lamp_PassingLmpSwSta 0 "Off" 1 "On" 2 "Not Used" 3 "Error Indicator" ;
VAL_ 961 Lamp_TrnSigLftSwSta 0 "Off" 1 "On" 2 "Not Used" 3 "Error Indicator" ;
VAL_ 961 Lamp_TrnSigRtSwSta 0 "Off" 1 "On" 2 "Not Used" 3 "Error Indicator" ;
VAL_ 961 Lamp_LaneChgTrnSigLftSwSta 0 "Off" 1 "On" 2 "Not Used" 3 "Error Indicator" ;
VAL_ 961 Lamp_LaneChgTrnSigRtSwSta 0 "Off" 1 "On" 2 "Not Used" 3 "Error Indicator" ;
VAL_ 962 Wiper_FrWiperSwSta 0 "Wiper Sw Off" 1 "Wiper Int or Auto Sw On(Refer to C_RainSnsOption)" 2 "Wiper Low Sw On" 3 "Wiper High Sw On" 4 "Reserved" 5 "Reserved" 6 "Not Used" 7 "Error Indicator" ;
VAL_ 962 Wiper_IntStepSta 0 "STEP1(SLOW)" 1 "STEP2" 2 "STEP3" 3 "STEP4" 4 "STEP5(FAST)" ;
VAL_ 1035 ExtLamp_IRLmpLftFlSta 0 "Ok" 1 "Fail" 2 "Not Used" 3 "Error Indicator" ;
VAL_ 1035 ExtLamp_IRLmpRtFlSta 0 "Ok" 1 "Fail" 2 "Not Used" 3 "Error Indicator" ;
VAL_ 1041 Warn_DrvDrSwSta 0 "Close" 1 "Open" 2 "Not Used" 3 "Error Indicator" ;
VAL_ 1041 Warn_AsstDrSwSta 0 "Close" 1 "Open" 2 "Not Used" 3 "Error Indicator" ;
VAL_ 1041 Warn_DrvStBltSwSta 0 "Unbelted" 1 "Belted" 2 "Not Used" 3 "Error Indicator" ;
VAL_ 1041 Warn_RrLftDrSwSta 0 "Close" 1 "Open" 2 "Not Used" 3 "Error Indicator" ;
VAL_ 1041 Warn_RrRtDrSwSta 0 "Close" 1 "Open" 2 "Not Used" 3 "Error Indicator" ;
VAL_ 1043 ExtLamp_FrFgLmpSta 0 "Off" 1 "On" 2 "Not Used" 3 "Error Indicator" ;
VAL_ 1043 ExtLamp_TrnSigLmpLftBlnkngSta 0 "Off" 1 "On" 2 "Not Used" 3 "Error Indicator" ;
VAL_ 1043 ExtLamp_TrnSigLmpRtBlnkngSta 0 "Off" 1 "On" 2 "Not Used" 3 "Error Indicator" ;
VAL_ 1043 ExtLamp_ExtrnlTailLmpSta 0 "Off" 1 "On" 2 "Not Used" 3 "Error Indicator" ;
VAL_ 1043 ExtLamp_HzrdSwSta 0 "Off" 1 "On" 2 "Not Used" 3 "Error Indicator" ;
VAL_ 1044 C_CrashUnlockState 0 "Off" 1 "Unlock(Crash)" ;
VAL_ 1050 Lamp_ExtrnlTailLmpOnReq 0 "Off" 1 "On" 2 "Not Used" 3 "Error Indicator" ;
VAL_ 1050 Lamp_HdLmpLoOnReq 0 "Off" 1 "On" 2 "Not Used" 3 "Error Indicator" ;
VAL_ 1050 Lamp_HdLmpHiOnReq 0 "Off" 1 "On" 2 "Not Used" 3 "Error Indicator" ;
VAL_ 1050 Lamp_PassingLmpOnReq 0 "Off" 1 "On" 2 "Not Used" 3 "Error Indicator" ;
VAL_ 1051 Lamp_HbaCtrlModTyp 0 "H/Lamp High control Mode by BCM" 1 "H/Lamp High control Mode by HBA" 2 "Not Used" 3 "Error Indicator" ;
VAL_ 1052 Lamp_AutoLtSnsrNightSta 0 "Off" 1 "Night" 2 "Not Used" 3 "Error Indicator" ;
VAL_ 1057 ILCULH_LowBeamAct_Sta 0 "Off" 1 "On" 2 "Not Used" 3 "Error Indicator" ;
VAL_ 1057 ILCULH_HighBeamAct_Sta 0 "Off" 1 "On" 2 "Not Used" 3 "Error Indicator" ;
VAL_ 1057 ILCULH_FrontTurnAct_Sta 0 "Off" 1 "On" 2 "Not Used" 3 "Error Indicator" ;
VAL_ 1057 ILCULH_IFSLamp_Act 0 "IFS Indicator Lamp Off (Default)" 1 "IFS Indicator Lamp On" 2 "IFS Indicator Lamp Off & Blockage state" 3 "Error Indicator" ;
VAL_ 1058 Wiper_PrkngPosSta 0 "else" 1 "Parking Position" 2 "Not Used" 3 "Error Indicator" ;
VAL_ 1058 Wiper_RainSnsrSta 0 "OFF" 1 "Rain Detected" 2 "Low" 3 "High" 4 "Fault 1" 5 "Fault 2" 6 "Fault 3" 7 "Reserved" 8 "Reserved" 9 "Reserved" 10 "Reserved" 11 "Reserved" 12 "Reserved" 13 "Reserved" 14 "Not Used" 15 "Error Indicator" ;
VAL_ 1062 ILCURH_LowBeamAct_Sta 0 "Off" 1 "On" 2 "Not Used" 3 "Error Indicator" ;
VAL_ 1062 ILCURH_HighBeamAct_Sta 0 "Off" 1 "On" 2 "Not Used" 3 "Error Indicator" ;
VAL_ 1062 ILCURH_FrontTurnAct_Sta 0 "Off" 1 "On" 2 "Not Used" 3 "Error Indicator" ;
VAL_ 1062 ILCURH_IFSLamp_Act 0 "IFS Indicator Lamp Off (Default)" 1 "IFS Indicator Lamp On" 2 "IFS Indicator Lamp Off & Blockage state" 3 "Error Indicator" ;
VAL_ 1076 IAU_ProfileIDRVal 0 "Default" 1 "Guest" 2 "Profile1" 3 "Profile2" 4 "Reserved" 5 "Reserved" 6 "Reserved" 7 "Reserved" 8 "Reserved" 9 "Reserved" 10 "Reserved" 11 "Reserved" 12 "Reserved" 13 "Reserved" 14 "Reserved" 15 "Invalid" ;
VAL_ 1092 SMK_TlEngRunSta 0 "Off" 1 "Tele Engine Running" 2 "Not Used" 3 "Error Indicator" ;
VAL_ 1097 Lamp_ExtrnlTailLmpSta_BCM 0 "Off" 1 "On" 2 "Not Used" 3 "Error Indicator" ;
VAL_ 1097 Lamp_HzrdSwSta_BCM 0 "Off" 1 "On" 2 "Not Used" 3 "Error Indicator" ;
VAL_ 1098 Lamp_HdLmpHiSta_BCM 0 "Off" 1 "On" 2 "Not Used" 3 "Error Indicator" ;
VAL_ 1098 Lamp_HdLmpLoSta_BCM 0 "Off" 1 "On" 2 "Not Used" 3 "Error Indicator" ;
VAL_ 1098 Lamp_FrFgLmpSta_BCM 0 "Off" 1 "On" 2 "Not Used" 3 "Error Indicator" ;
VAL_ 1135 USM_AdasLkaModSetReq 0 "Default" 1 "LDW mode" 2 "LKA" 3 "Reserved" 4 "LDW only ON (None LKA)" 5 "LDW only OFF (None LKA)" 6 "LDW/LKA OFF" 7 "Invalid" ;
VAL_ 1135 USM_AdasFCAJnctnSetReq 0 "Default" 1 "Off" 2 "On" 3 "Invalid" ;
VAL_ 1135 USM_AdasHbaSetReq 0 "Default" 1 "Off" 2 "On" 3 "Invalid" ;
VAL_ 1135 USM_AdasSCCMLSetReq 0 "Default" 1 "Off" 2 "On" 3 "Invalid" ;
VAL_ 1135 USM_AdasSCCMLResetReq 0 "Default" 1 "Reset" 2 "Reserved" 3 "Invalid" ;
VAL_ 1145 USM_AdasUSMResetReq 0 "Default" 1 "Reset" 2 "Reserved" 3 "Invalid" ;
VAL_ 1145 USM_AdasFCASetReq 0 "Default(NoneFCA)" 1 "Off" 2 "Warning" 3 "Assist" 4 "Reserved" 5 "Reserved" 6 "Reserved" 7 "Invalid" ;
VAL_ 1145 USM_AdasSCCDrvModSetReq 0 "Default" 1 "Comfort" 2 "Normal" 3 "Dynamic" 4 "Reserved" 5 "Reserved" 6 "Reserved" 7 "Invalid" ;
VAL_ 1145 USM_AdasDAWModSetReq 0 "Default" 1 "Off" 2 "Reserved" 3 "Normal" 4 "Early" 5 "Reserved" 6 "Reserved" 7 "Invalid" ;
VAL_ 1145 USM_AdasHDASetReq 0 "Default" 1 "Function Off" 2 "Function On" 3 "Invalid(Fail)" ;
VAL_ 1145 USM_AdasNSCCCamSetReq 0 "Default" 1 "Disable" 2 "Enable" 3 "Invalid" ;
VAL_ 1145 USM_AdasLFASetReq 0 "Default" 1 "Function Off" 2 "Function On" 3 "Invalid" ;
VAL_ 1145 USM_AdasBCASetReq 0 "Default" 1 "Off" 2 "Warning" 3 "Assist" 4 "Reserved" 5 "Reserved" 6 "Reserved" 7 "Invalid" ;
VAL_ 1145 USM_AdasISLWSetReq 0 "Default" 1 "Disable" 2 "Enable" 3 "Invalid" ;
VAL_ 1145 USM_AdasWrngTimingSetReq 0 "Default" 1 "Late" 2 "Normal" 3 "Reserved" 4 "Reserved" 5 "Reserved" 6 "Reserved" 7 "Invliad" ;
VAL_ 1145 USM_AdasLVDASetReq 0 "Default" 1 "Off" 2 "On" 3 "Invalid" ;
VAL_ 1145 USM_AdasNSCCCrvSetReq 0 "Default" 1 "Disable" 2 "Enable" 3 "Invalid" ;
SIG_GROUP_ 416 ADAS_CMD_20_20ms 1 : SCC_TrgtDstVal SCC_VehStpReq SCC_AccelLimBandLwrVal SCC_AccelLimBandUppVal SCC_JrkLwrLimVal SCC_JrkUppLimVal SCC_AccelReqRawVal SCC_SnstvtyModRetVal SCC_AccelReqVal SCC_ObjSta SCC_NSCCOnOffSta SCC_NSCCOpSta SCC_TrgtSpdSetVal SCC_EquipSta SCC_HeadwayDstSetVal SCC_ObjDstLvlVal SCC_DrvAlrtDis SCC_InfoDis SCC_TakeoverReq SCC_OpSta SCC_MainOnOffSta SCC_SysFlrSta SCC_ObjLatPosVal SCC_ObjRelSpdVal SCC_ObjDstVal ADAS_CMD_AlvCnt20Val ADAS_CMD_Crc20Val;
SIG_GROUP_ 426 CLU_01_20ms 1 : CLU_DisSpdVal CLU_RhstaLvlSta CLU_SWRCLFASwSta CLU_SpdUnitTyp CLU_DtntOutSta CLU_AlvCnt1Val CLU_Crc1Val;
SIG_GROUP_ 437 FR_CMR_03_50ms 1 : Info_RtLnCrvtrDrvtvVal Info_RtLnCvtrVal Info_RtLnHdingAnglVal Info_RtLnPosVal Info_RtLnDptSta Info_RtLnQualSta Info_LftLnCrvtrDrvtvVal Info_LftLnCvtrVal Info_LftLnHdingAnglVal Info_LftLnPosVal Info_LftLnDptSta Info_LftLnQualSta FR_CMR_AlvCnt3Val FR_CMR_Crc3Val;
SIG_GROUP_ 506 FR_CMR_02_100ms 1 : ISLW_SpdNaviDisSubCond2 ISLW_SpdNaviDisSubCond1 ISLW_SpdNaviSubMainDis ISLW_SpdCluDisSubCond2 ISLW_SpdCluDisSubCond1 ISLW_SpdCluSubMainDis ISLW_SubCondinfoSta2 ISLW_SubCondinfoSta1 ISLW_SpdNaviMainDis ISLW_SpdCluMainDis ISLW_OvrlpSignDis ISLW_NoPassingInfoDis ISLW_SysSta ISLW_OptUsmSta FR_CMR_AlvCnt2Val FR_CMR_Crc2Val ISLA_SchoolZone ISLA_AddtnlSign ISLA_Cntry ISLA_AutoUsmSta ISLA_OffstUsmSta ISLA_OptUsmSta ISLA_Popup ISLA_SymFlashMod ISLA_IcyWrn ISLA_SpdWrn ISLA_SpdChgReq ISLA_SwIgnoreReq ISLA_SpdwOffst;
SIG_GROUP_ 549 CLU_02_100ms 1 : CLU_TerrainModSwSta CLU_DrvngModSwSta CLU_IceWrnIndSta CLU_DawLastBrkTimeVal CLU_OdoVal CLU_TerrainMainSwSta CLU_AlvCnt2Val;
SIG_GROUP_ 608 EMS_05_100ms 1 : ENG_EngDsplceTyp ENG_TransmsnTyp;
SIG_GROUP_ 1043 ICU_04_200ms 1 : ExtLamp_TrnSigLmpLftBlnkngSta ExtLamp_TrnSigLmpRtBlnkngSta;
SIG_GROUP_ 1135 CLU_13_00ms 1 : USM_AdasSCCMLResetReq USM_AdasSCCMLSetReq USM_AdasHbaSetReq USM_AdasFCAJnctnSetReq USM_AdasLkaModSetReq CLU_AlvCnt13Val CLU_Crc13Val;
SIG_GROUP_ 1145 CLU_12_00ms 1 : USM_AdasNSCCCrvSetReq USM_AdasBCASetReq USM_AdasLFASetReq USM_AdasNSCCCamSetReq USM_AdasHDASetReq USM_AdasDAWModSetReq USM_AdasSCCDrvModSetReq USM_AdasLVDASetReq USM_AdasWrngTimingSetReq USM_AdasISLWSetReq USM_AdasUSMResetReq USM_AdasFCASetReq CLU_AlvCnt12Val CLU_Crc12Val;
